VERSION ""

NS_ :

BS_:

BU_:

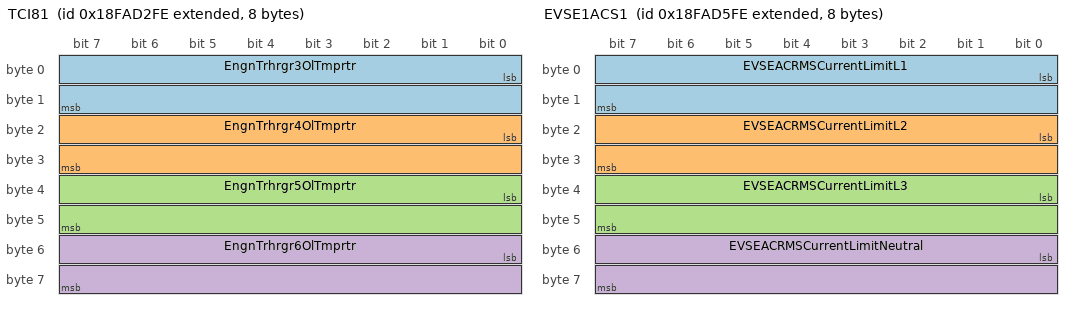
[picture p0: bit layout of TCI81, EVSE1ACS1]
BO_ 2566574846 TCI81: 8 Vector__XXX
 SG_ EngnTrhrgr3OlTmprtr : 0|16@1+ (0.03125,-273) [-273|1734.96875] "degC" Vector__XXX
 SG_ EngnTrhrgr4OlTmprtr : 16|16@1+ (0.03125,-273) [-273|1734.96875] "degC" Vector__XXX
 SG_ EngnTrhrgr5OlTmprtr : 32|16@1+ (0.03125,-273) [-273|1734.96875] "degC" Vector__XXX
 SG_ EngnTrhrgr6OlTmprtr : 48|16@1+ (0.03125,-273) [-273|1734.96875] "degC" Vector__XXX

BO_ 2566575102 ADSC: 8 Vector__XXX
 SG_ TSC1CntrlPrpsP7InhtCmmnd : 0|2@1+ (1,0) [0|3] "" Vector__XXX

BO_ 2566575358 EVSE1ACS2: 8 Vector__XXX
 SG_ EVSE1ACRMSCurrent : 0|16@1+ (0.05,-1600) [-1600|1612.75] "A" Vector__XXX
 SG_ EVSE1ACRMSVoltage : 16|16@1+ (0.05,0) [0|3212.75] "V" Vector__XXX

BO_ 2566575614 EVSE1ACS1: 8 Vector__XXX
 SG_ EVSEACRMSCurrentLimitL1 : 0|16@1+ (0.0625,0) [0|4015.9375] "A" Vector__XXX
 SG_ EVSEACRMSCurrentLimitL2 : 16|16@1+ (0.0625,0) [0|4015.9375] "A" Vector__XXX
 SG_ EVSEACRMSCurrentLimitL3 : 32|16@1+ (0.0625,0) [0|4015.9375] "A" Vector__XXX
 SG_ EVSEACRMSCurrentLimitNeutral : 48|16@1+ (0.0625,0) [0|4015.9375] "A" Vector__XXX

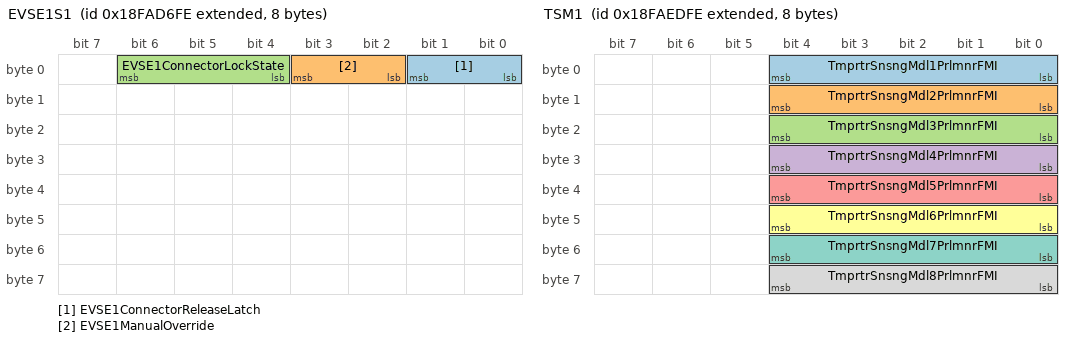
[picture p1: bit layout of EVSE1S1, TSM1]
BO_ 2566575870 EVSE1S1: 8 Vector__XXX
 SG_ EVSE1ConnectorReleaseLatch : 0|2@1+ (1,0) [0|3] "" Vector__XXX
 SG_ EVSE1ManualOverride : 2|2@1+ (1,0) [0|3] "" Vector__XXX
 SG_ EVSE1ConnectorLockState : 4|3@1+ (1,0) [0|7] "" Vector__XXX

BO_ 2566581758 TSM1: 8 Vector__XXX
 SG_ TmprtrSnsngMdl1PrlmnrFMI : 0|5@1+ (1,0) [0|31] "binary" Vector__XXX
 SG_ TmprtrSnsngMdl2PrlmnrFMI : 8|5@1+ (1,0) [0|31] "binary" Vector__XXX
 SG_ TmprtrSnsngMdl3PrlmnrFMI : 16|5@1+ (1,0) [0|31] "binary" Vector__XXX
 SG_ TmprtrSnsngMdl4PrlmnrFMI : 24|5@1+ (1,0) [0|31] "binary" Vector__XXX
 SG_ TmprtrSnsngMdl5PrlmnrFMI : 32|5@1+ (1,0) [0|31] "binary" Vector__XXX
 SG_ TmprtrSnsngMdl6PrlmnrFMI : 40|5@1+ (1,0) [0|31] "binary" Vector__XXX
 SG_ TmprtrSnsngMdl7PrlmnrFMI : 48|5@1+ (1,0) [0|31] "binary" Vector__XXX
 SG_ TmprtrSnsngMdl8PrlmnrFMI : 56|5@1+ (1,0) [0|31] "binary" Vector__XXX

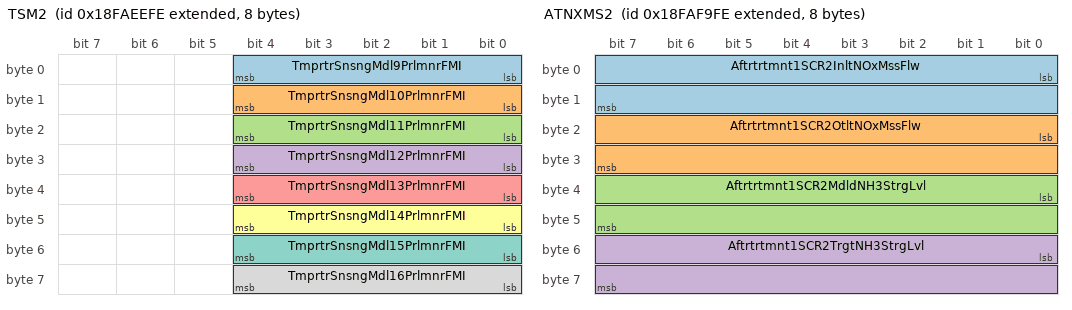
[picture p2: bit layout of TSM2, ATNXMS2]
BO_ 2566582014 TSM2: 8 Vector__XXX
 SG_ TmprtrSnsngMdl9PrlmnrFMI : 0|5@1+ (1,0) [0|31] "binary" Vector__XXX
 SG_ TmprtrSnsngMdl10PrlmnrFMI : 8|5@1+ (1,0) [0|31] "binary" Vector__XXX
 SG_ TmprtrSnsngMdl11PrlmnrFMI : 16|5@1+ (1,0) [0|31] "binary" Vector__XXX
 SG_ TmprtrSnsngMdl12PrlmnrFMI : 24|5@1+ (1,0) [0|31] "binary" Vector__XXX
 SG_ TmprtrSnsngMdl13PrlmnrFMI : 32|5@1+ (1,0) [0|31] "binary" Vector__XXX
 SG_ TmprtrSnsngMdl14PrlmnrFMI : 40|5@1+ (1,0) [0|31] "binary" Vector__XXX
 SG_ TmprtrSnsngMdl15PrlmnrFMI : 48|5@1+ (1,0) [0|31] "binary" Vector__XXX
 SG_ TmprtrSnsngMdl16PrlmnrFMI : 56|5@1+ (1,0) [0|31] "binary" Vector__XXX

BO_ 2566582270 A2SCRSI3: 8 Vector__XXX
 SG_ Aftrtrtmnt2SCRNrmlzdCnvrsnEffn : 0|8@1+ (0.4,0) [0|100] "%" Vector__XXX

BO_ 2566582526 A1SCRSI3: 8 Vector__XXX
 SG_ Aftrtrtmnt1SCRNrmlzdCnvrsnEffn : 0|8@1+ (0.4,0) [0|100] "%" Vector__XXX

BO_ 2566582782 PSATL: 200 Vector__XXX
 SG_ HrdLftmPrplsnSstmAtvTm : 0|32@1+ (1,0) [0|4211081215] "s" Vector__XXX
 SG_ HrdLftmIdlPrplsnSstmAtvTm : 32|32@1+ (1,0) [0|4211081215] "s" Vector__XXX
 SG_ HrdLftmUrnPrplsnSstmAtvTm : 64|32@1+ (1,0) [0|4211081215] "s" Vector__XXX

BO_ 2566583038 PSATS: 200 Vector__XXX
 SG_ HrdStrd100HrRntPrplsnSstmAtvTm : 0|16@1+ (10,0) [0|642550] "s" Vector__XXX
 SG_ HrdStrd100HrIdlPrplsnSstmAtvTm : 16|16@1+ (10,0) [0|642550] "s" Vector__XXX
 SG_ HrdStrd100HrUrnPrplsnSstmAtvTm : 32|16@1+ (10,0) [0|642550] "s" Vector__XXX

BO_ 2566583294 PSATA: 200 Vector__XXX
 SG_ HrdAtv100HrPrplsnSstmAtvTm : 0|16@1+ (10,0) [0|642550] "s" Vector__XXX
 SG_ HrdAtv100HrIdlPrplsnSstmAtvTm : 16|16@1+ (10,0) [0|642550] "s" Vector__XXX
 SG_ HrdAtv100HrUrnPrplsnSstmAtvTm : 32|16@1+ (10,0) [0|642550] "s" Vector__XXX

BO_ 2566583550 HCDIOL: 200 Vector__XXX
 SG_ HdLtDstTvdCDptOptwtE : 0|32@1+ (5,0) [0|21055406075] "m" Vector__XXX
 SG_ HdLtDstTvdCDptOptwtER : 32|32@1+ (5,0) [0|21055406075] "m" Vector__XXX
 SG_ HdLtDstTvdDvStCIsOpt : 64|32@1+ (5,0) [0|21055406075] "m" Vector__XXX
 SG_ HrdLftmFlCnsmdnChrgDpltngOprtn : 96|32@1+ (0.5,0) [0|2105540607.5] "l" Vector__XXX
 SG_ HdLtFCsdDvStCIsOpt : 128|32@1+ (0.5,0) [0|2105540607.5] "l" Vector__XXX
 SG_ HdLtGdECsdCDptOptwtE : 160|32@1+ (1,0) [0|4211081215] "kWh" Vector__XXX
 SG_ HdLtGdECsdCDptOptwtER : 192|32@1+ (1,0) [0|4211081215] "kWh" Vector__XXX
 SG_ HrdLftmGrdEnrgntthBttr : 224|32@1+ (1,0) [0|4211081215] "kWh" Vector__XXX

BO_ 2566583806 HCDIOS: 200 Vector__XXX
 SG_ HdStd100HDstTvdCDptOptwtE : 0|16@1+ (0.25,0) [0|16063.75] "km" Vector__XXX
 SG_ HdStd100HDstTvdCDptOptwtER : 16|16@1+ (0.25,0) [0|16063.75] "km" Vector__XXX
 SG_ HdStd100HDstTvdDvStCIsOpt : 32|16@1+ (0.25,0) [0|16063.75] "km" Vector__XXX
 SG_ HdStd100HFCsdCDptOpt : 48|16@1+ (0.5,0) [0|32127.5] "l" Vector__XXX
 SG_ HdStd100HFCsdDvStCIsOpt : 64|16@1+ (0.5,0) [0|32127.5] "l" Vector__XXX
 SG_ HdStd100HGdECsdCDptOptwtE : 80|16@1+ (1,0) [0|64255] "kWh" Vector__XXX
 SG_ HdStd100HGdECsdCDptOptwtER : 96|16@1+ (1,0) [0|64255] "kWh" Vector__XXX
 SG_ HrdStrd100HrGrdEnrgntthBttr : 112|16@1+ (1,0) [0|64255] "kWh" Vector__XXX

BO_ 2566584062 HCDIOA: 200 Vector__XXX
 SG_ HdAtv100HDstTvdCDptOptwtE : 0|16@1+ (0.25,0) [0|16063.75] "km" Vector__XXX
 SG_ HdAtv100HDstTvdCDptOptwtER : 16|16@1+ (0.25,0) [0|16063.75] "km" Vector__XXX
 SG_ HdAtv100HDstTvdDvStCIsOpt : 32|16@1+ (0.25,0) [0|16063.75] "km" Vector__XXX
 SG_ HdAtv100HFCsdCDptOpt : 48|16@1+ (0.5,0) [0|32127.5] "l" Vector__XXX
 SG_ HdAtv100HFCsdDvStCIsOpt : 64|16@1+ (0.5,0) [0|32127.5] "l" Vector__XXX
 SG_ HdAtv100HGdECsdCDptOptwtE : 80|16@1+ (1,0) [0|64255] "kWh" Vector__XXX
 SG_ HdAtv100HGdECsdCDptOptwtER : 96|16@1+ (1,0) [0|64255] "kWh" Vector__XXX
 SG_ HrdAtv100HrGrdEnrgntthBttr : 112|16@1+ (1,0) [0|64255] "kWh" Vector__XXX

BO_ 2566584318 AT1HI3: 200 Vector__XXX
 SG_ Atttt1DPFRCptSttEVDst1 : 0|32@1+ (5,0) [0|21055406075] "m" Vector__XXX
 SG_ Atttt1DPFRCptEdEVDst1 : 32|32@1+ (5,0) [0|21055406075] "m" Vector__XXX
 SG_ Atttt1DPFRCptSttEVDst2 : 64|32@1+ (5,0) [0|21055406075] "m" Vector__XXX
 SG_ Atttt1DPFRCptEdEVDst2 : 96|32@1+ (0.125,0) [0|526385151.875] "km" Vector__XXX
 SG_ Atttt1DPFRCptSttEVDst3 : 128|32@1+ (5,0) [0|21055406075] "m" Vector__XXX
 SG_ Atttt1DPFRCptEdEVDst3 : 160|32@1+ (5,0) [0|21055406075] "m" Vector__XXX
 SG_ Atttt1TtERtWtNDEFDv : 192|32@1+ (1,0) [0|4211081215] "s" Vector__XXX
 SG_ Atttt1TtTSCRItBw200Css : 224|32@1+ (1,0) [0|4211081215] "s" Vector__XXX

BO_ 2566584830 ATNXMS2: 8 Vector__XXX
 SG_ Aftrtrtmnt1SCR2InltNOxMssFlw : 0|16@1+ (0.0001,0) [0|6.4255] "g/s" Vector__XXX
 SG_ Aftrtrtmnt1SCR2OtltNOxMssFlw : 16|16@1+ (0.0001,0) [0|6.4255] "g/s" Vector__XXX
 SG_ Aftrtrtmnt1SCR2MdldNH3StrgLvl : 32|16@1+ (1,0) [0|64255] "mg/l" Vector__XXX
 SG_ Aftrtrtmnt1SCR2TrgtNH3StrgLvl : 48|16@1+ (1,0) [0|64255] "mg/l" Vector__XXX

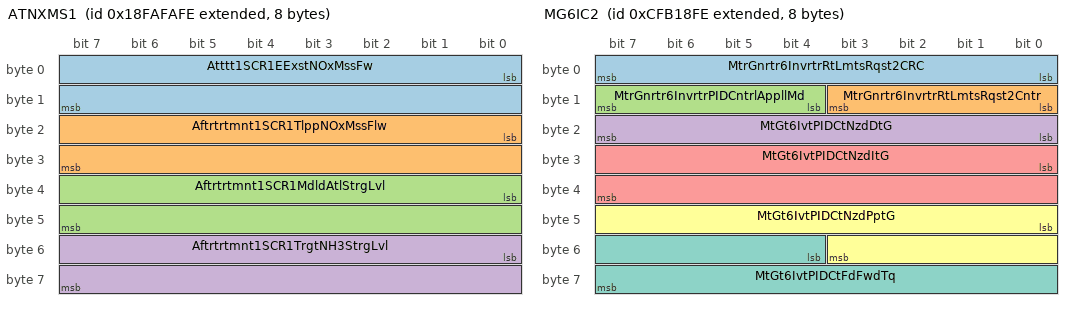
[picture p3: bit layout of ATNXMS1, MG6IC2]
BO_ 2566585086 ATNXMS1: 8 Vector__XXX
 SG_ Atttt1SCR1EExstNOxMssFw : 0|16@1+ (0.0001,0) [0|6.4255] "g/s" Vector__XXX
 SG_ Aftrtrtmnt1SCR1TlppNOxMssFlw : 16|16@1+ (0.0001,0) [0|6.4255] "g/s" Vector__XXX
 SG_ Aftrtrtmnt1SCR1MdldAtlStrgLvl : 32|16@1+ (1,0) [0|64255] "mg/l" Vector__XXX
 SG_ Aftrtrtmnt1SCR1TrgtNH3StrgLvl : 48|16@1+ (1,0) [0|64255] "mg/l" Vector__XXX

BO_ 2566585342 EVAP1: 200 Vector__XXX
 SG_ EVAPSystemPurgePressure : 0|16@1+ (4,0) [0|257] "Pa" Vector__XXX
 SG_ EVAPSystemVaporPressure : 16|16@1+ (4,0) [0|257] "Pa" Vector__XXX
 SG_ EVAPSystemPurgeValveCommand : 32|8@1+ (0.4,0) [0|100] "%" Vector__XXX
 SG_ EVAPSystemPurgeValvePosition : 40|8@1+ (0.4,0) [0|100] "%" Vector__XXX

BO_ 2566585598 GHGTL: 200 Vector__XXX
 SG_ GHGTrkngLftmEngnRnTm : 0|32@1+ (1,0) [0|4211081215] "s" Vector__XXX
 SG_ GHGTrkngLftmVhlDstn : 32|32@1+ (5,0) [0|21055406075] "m" Vector__XXX
 SG_ GHGTrkngLftmVhlFlCnsmptn : 64|32@1+ (0.05,0) [0|210554060.75] "l" Vector__XXX
 SG_ GHGTrkngLftmEngnFlCnsmptn : 96|32@1+ (0.05,0) [0|210554060.75] "l" Vector__XXX
 SG_ GHGTrkngLftmEngnOtptEnrg : 128|32@1+ (1,0) [0|4211081215] "kWh" Vector__XXX
 SG_ GHGTrkngLftmPstvKntEnrgNmrtr : 160|32@1+ (5,0) [0|21055406075] "(km*km)/(h*h)" Vector__XXX
 SG_ GHGTrkngLftmUrnSpdRnTm : 192|32@1+ (1,0) [0|4211081215] "s" Vector__XXX
 SG_ GHGTrackingLifetimeIdleRunTime : 224|32@1+ (1,0) [0|4211081215] "s" Vector__XXX
 SG_ GHGTrkngLftmEngnIdlFlCnsmptn : 256|32@1+ (0.05,0) [0|210554060.75] "l" Vector__XXX
 SG_ GHGTrkngLftmEngnPwrTkOffRnTm : 288|32@1+ (1,0) [0|4211081215] "s" Vector__XXX
 SG_ GHGTLtEPwTOFCspt : 320|32@1+ (0.05,0) [0|210554060.75] "l" Vector__XXX
 SG_ GHGTLtAttEStdwTAtvtCt : 352|16@1+ (1,0) [0|64255] "count" Vector__XXX
 SG_ GHGTrkngLftmStpStrtThnlgRnTm : 384|32@1+ (1,0) [0|4211081215] "s" Vector__XXX

BO_ 2566585854 GHGTS1: 200 Vector__XXX
 SG_ GHGTrkngStrd100HrEngnRnTm : 0|16@1+ (10,0) [0|642550] "s" Vector__XXX
 SG_ GHGTrkngStrd100HrVhlDstn : 16|16@1+ (0.25,0) [0|16063.75] "km" Vector__XXX
 SG_ GHGTrkngStrd100HrVhlFlCnsmptn : 32|16@1+ (0.5,0) [0|32127.5] "l" Vector__XXX
 SG_ GHGTrkngStrd100HrEngnFlCnsmptn : 48|16@1+ (0.5,0) [0|32127.5] "l" Vector__XXX
 SG_ GHGTrkngStrd100HrEngnOtptEnrg : 64|16@1+ (1,0) [0|64255] "kWh" Vector__XXX
 SG_ GHGTStd100HPstvKtENt : 80|32@1+ (1,0) [0|4211081215] "(km*km)/(h*h)" Vector__XXX
 SG_ GHGTrkngStrd100HrUrnSpdRnTm : 112|16@1+ (10,0) [0|642550] "s" Vector__XXX
 SG_ GHGTrkngStrd100HrIdlRnTm : 128|16@1+ (10,0) [0|642550] "s" Vector__XXX
 SG_ GHGTStd100HEIdFCspt : 144|16@1+ (0.5,0) [0|32127.5] "l" Vector__XXX
 SG_ GHGTStd100HEPwTORT : 160|16@1+ (10,0) [0|642550] "s" Vector__XXX
 SG_ GHGTStd100HEPwTOFCspt : 176|16@1+ (0.5,0) [0|32127.5] "l" Vector__XXX
 SG_ GHGTStd100HAttEStdwTAtvtCt : 192|16@1+ (1,0) [0|64255] "count" Vector__XXX
 SG_ GHGTStd100HStpSttTRT : 208|16@1+ (10,0) [0|642550] "s" Vector__XXX

BO_ 2566586110 GHGTA1: 200 Vector__XXX
 SG_ GHGTrkngAtv100HrEngnRnTm : 0|16@1+ (10,0) [0|642550] "s" Vector__XXX
 SG_ GHGTrkngAtv100HrVhlDstn : 16|16@1+ (0.25,0) [0|16063.75] "km" Vector__XXX
 SG_ GHGTrkngAtv100HrVhlFlCnsmptn : 32|16@1+ (0.5,0) [0|32127.5] "l" Vector__XXX
 SG_ GHGTrkngAtv100HrEngnFlCnsmptn : 48|16@1+ (0.5,0) [0|32127.5] "l" Vector__XXX
 SG_ GHGTrkngAtv100HrEngnOtptEnrg : 64|16@1+ (1,0) [0|64255] "kWh" Vector__XXX
 SG_ GHGTAtv100HPstvKtENt : 80|32@1+ (1,0) [0|4211081215] "(km*km)/(h*h)" Vector__XXX
 SG_ GHGTrkngAtv100HrUrnSpdRnTm : 112|16@1+ (10,0) [0|642550] "s" Vector__XXX
 SG_ GHGTrkngAtv100HrIdlRnTm : 128|16@1+ (10,0) [0|642550] "s" Vector__XXX
 SG_ GHGTAtv100HEIdFCspt : 144|16@1+ (0.5,0) [0|32127.5] "l" Vector__XXX
 SG_ GHGTAtv100HEPwTORT : 160|16@1+ (10,0) [0|642550] "s" Vector__XXX
 SG_ GHGTAtv100HEPwTOFCspt : 176|16@1+ (0.5,0) [0|32127.5] "l" Vector__XXX
 SG_ GHGTAtv100HAttEStdwTAtvtCt : 192|16@1+ (1,0) [0|64255] "count" Vector__XXX
 SG_ GHGTAtv100HStpSttTRT : 208|16@1+ (10,0) [0|642550] "s" Vector__XXX

BO_ 2566587134 NTFCEA: 200 Vector__XXX
 SG_ NOxTEAtvtLtFCsptB1Tt : 0|32@1+ (0.05,0) [0|210554060.75] "l" Vector__XXX
 SG_ NOxTEAtvtLtFCsptB2 : 32|32@1+ (0.05,0) [0|210554060.75] "l" Vector__XXX
 SG_ NOxTEAtvtLtFCsptB3 : 64|32@1+ (0.05,0) [0|210554060.75] "l" Vector__XXX
 SG_ NOxTEAtvtLtFCsptB4 : 96|32@1+ (0.05,0) [0|210554060.75] "l" Vector__XXX
 SG_ NOxTEAtvtLtFCsptB5 : 128|32@1+ (0.05,0) [0|210554060.75] "l" Vector__XXX
 SG_ NOxTEAtvtLtFCsptB6 : 160|32@1+ (0.05,0) [0|210554060.75] "l" Vector__XXX
 SG_ NOxTEAtvtLtFCsptB7 : 192|32@1+ (0.05,0) [0|210554060.75] "l" Vector__XXX
 SG_ NOxTEAtvtLtFCsptB8 : 224|32@1+ (0.05,0) [0|210554060.75] "l" Vector__XXX
 SG_ NOxTEAtvtLtFCsptB9 : 256|32@1+ (0.05,0) [0|210554060.75] "l" Vector__XXX
 SG_ NOxTEAtvtLtFCsptB10 : 288|32@1+ (0.05,0) [0|210554060.75] "l" Vector__XXX
 SG_ NOxTEAtvtLtFCsptB11 : 320|32@1+ (0.05,0) [0|210554060.75] "l" Vector__XXX
 SG_ NOxTEAtvtLtFCsptB12 : 352|32@1+ (0.05,0) [0|210554060.75] "l" Vector__XXX
 SG_ NOxTEAtvtLtFCsptB13 : 384|32@1+ (0.05,0) [0|210554060.75] "l" Vector__XXX
 SG_ NOxTEAtvtLtFCsptB14 : 416|32@1+ (0.05,0) [0|210554060.75] "l" Vector__XXX
 SG_ NOxTEAtvtLtFCsptB15NTEBIN : 448|32@1+ (0.05,0) [0|210554060.75] "l" Vector__XXX
 SG_ NOxTEAtvtLtFCsptB16RB : 480|32@1+ (0.05,0) [0|210554060.75] "l" Vector__XXX
 SG_ NOxTEAtvtLtFCsptB17MILOB : 512|32@1+ (0.05,0) [0|210554060.75] "l" Vector__XXX

BO_ 2566587390 NTEHEA: 200 Vector__XXX
 SG_ NOxTEAtvtLtERTB1Tt : 0|32@1+ (1,0) [0|4211081215] "s" Vector__XXX
 SG_ NOxTrkngEngnAtvtLftmEngnRnTmBn2 : 32|32@1+ (1,0) [0|4211081215] "s" Vector__XXX
 SG_ NOxTrkngEngnAtvtLftmEngnRnTmBn3 : 64|32@1+ (1,0) [0|4211081215] "s" Vector__XXX
 SG_ NOxTrkngEngnAtvtLftmEngnRnTmBn4 : 96|32@1+ (1,0) [0|4211081215] "s" Vector__XXX
 SG_ NOxTrkngEngnAtvtLftmEngnRnTmBn5 : 128|32@1+ (1,0) [0|4211081215] "s" Vector__XXX
 SG_ NOxTrkngEngnAtvtLftmEngnRnTmBn6 : 160|32@1+ (1,0) [0|4211081215] "s" Vector__XXX
 SG_ NOxTrkngEngnAtvtLftmEngnRnTmBn7 : 192|32@1+ (1,0) [0|4211081215] "s" Vector__XXX
 SG_ NOxTrkngEngnAtvtLftmEngnRnTmBn8 : 224|32@1+ (1,0) [0|4211081215] "s" Vector__XXX
 SG_ NOxTrkngEngnAtvtLftmEngnRnTmBn9 : 256|32@1+ (1,0) [0|4211081215] "s" Vector__XXX
 SG_ NOxTEAtvtLtERTB10 : 288|32@1+ (1,0) [0|4211081215] "s" Vector__XXX
 SG_ NOxTEAtvtLtERTB11 : 320|32@1+ (1,0) [0|4211081215] "s" Vector__XXX
 SG_ NOxTEAtvtLtERTB12 : 352|32@1+ (1,0) [0|4211081215] "s" Vector__XXX
 SG_ NOxTEAtvtLtERTB13 : 384|32@1+ (1,0) [0|4211081215] "s" Vector__XXX
 SG_ NOxTEAtvtLtERTB14 : 416|32@1+ (1,0) [0|4211081215] "s" Vector__XXX
 SG_ NOxTEAtvtLtERTB15NTEBIN : 448|32@1+ (1,0) [0|4211081215] "s" Vector__XXX
 SG_ NOxTEAtvtLtERTB16RB : 480|32@1+ (1,0) [0|4211081215] "s" Vector__XXX
 SG_ NOxTEAtvtLtERTB17MILOB : 512|32@1+ (1,0) [0|4211081215] "s" Vector__XXX

BO_ 2566587646 NTVMEA: 200 Vector__XXX
 SG_ NOxTEAtvtLtVDstB1Tt : 0|32@1+ (5,0) [0|21055406075] "m" Vector__XXX
 SG_ NOxTrkngEngnAtvtLftmVhlDstnBn2 : 32|32@1+ (5,0) [0|21055406075] "m" Vector__XXX
 SG_ NOxTrkngEngnAtvtLftmVhlDstnBn3 : 64|32@1+ (5,0) [0|21055406075] "m" Vector__XXX
 SG_ NOxTrkngEngnAtvtLftmVhlDstnBn4 : 96|32@1+ (5,0) [0|21055406075] "m" Vector__XXX
 SG_ NOxTrkngEngnAtvtLftmVhlDstnBn5 : 128|32@1+ (5,0) [0|21055406075] "m" Vector__XXX
 SG_ NOxTrkngEngnAtvtLftmVhlDstnBn6 : 160|32@1+ (5,0) [0|21055406075] "m" Vector__XXX
 SG_ NOxTrkngEngnAtvtLftmVhlDstnBn7 : 192|32@1+ (5,0) [0|21055406075] "m" Vector__XXX
 SG_ NOxTrkngEngnAtvtLftmVhlDstnBn8 : 224|32@1+ (5,0) [0|21055406075] "m" Vector__XXX
 SG_ NOxTrkngEngnAtvtLftmVhlDstnBn9 : 256|32@1+ (5,0) [0|21055406075] "m" Vector__XXX
 SG_ NOxTrkngEngnAtvtLftmVhlDstnBn10 : 288|32@1+ (5,0) [0|21055406075] "m" Vector__XXX
 SG_ NOxTrkngEngnAtvtLftmVhlDstnBn11 : 320|32@1+ (5,0) [0|21055406075] "m" Vector__XXX
 SG_ NOxTrkngEngnAtvtLftmVhlDstnBn12 : 352|32@1+ (5,0) [0|21055406075] "m" Vector__XXX
 SG_ NOxTrkngEngnAtvtLftmVhlDstnBn13 : 384|32@1+ (5,0) [0|21055406075] "m" Vector__XXX
 SG_ NOxTrkngEngnAtvtLftmVhlDstnBn14 : 416|32@1+ (5,0) [0|21055406075] "m" Vector__XXX
 SG_ NOxTEAtvtLtVDstB15NTEBIN : 448|32@1+ (5,0) [0|21055406075] "m" Vector__XXX
 SG_ NOxTEAtvtLtVDstB16RB : 480|32@1+ (5,0) [0|21055406075] "m" Vector__XXX
 SG_ NOxTEAtvtLtVDstB17MILOB : 512|32@1+ (5,0) [0|21055406075] "m" Vector__XXX

BO_ 2566587902 NTEEEA: 200 Vector__XXX
 SG_ NOxTEAtvtLtEOtptEB1Tt : 0|32@1+ (1,0) [0|4211081215] "kWh" Vector__XXX
 SG_ NOxTEAtvtLtEOtptEB2 : 32|32@1+ (1,0) [0|4211081215] "kWh" Vector__XXX
 SG_ NOxTEAtvtLtEOtptEB3 : 64|32@1+ (1,0) [0|4211081215] "kWh" Vector__XXX
 SG_ NOxTEAtvtLtEOtptEB4 : 96|32@1+ (1,0) [0|4211081215] "kWh" Vector__XXX
 SG_ NOxTEAtvtLtEOtptEB5 : 128|32@1+ (1,0) [0|4211081215] "kWh" Vector__XXX
 SG_ NOxTEAtvtLtEOtptEB6 : 160|32@1+ (1,0) [0|4211081215] "kWh" Vector__XXX
 SG_ NOxTEAtvtLtEOtptEB7 : 192|32@1+ (1,0) [0|4211081215] "kWh" Vector__XXX
 SG_ NOxTEAtvtLtEOtptEB8 : 224|32@1+ (1,0) [0|4211081215] "kWh" Vector__XXX
 SG_ NOxTEAtvtLtEOtptEB9 : 256|32@1+ (1,0) [0|4211081215] "kWh" Vector__XXX
 SG_ NOxTEAtvtLtEOtptEB10 : 288|32@1+ (1,0) [0|4211081215] "kWh" Vector__XXX
 SG_ NOxTEAtvtLtEOtptEB11 : 320|32@1+ (1,0) [0|4211081215] "kWh" Vector__XXX
 SG_ NOxTEAtvtLtEOtptEB12 : 352|32@1+ (1,0) [0|4211081215] "kWh" Vector__XXX
 SG_ NOxTEAtvtLtEOtptEB13 : 384|32@1+ (1,0) [0|4211081215] "kWh" Vector__XXX
 SG_ NOxTEAtvtLtEOtptEB14 : 416|32@1+ (1,0) [0|4211081215] "kWh" Vector__XXX
 SG_ NOxTEAtvtLtEOtptEB15NTEBIN : 448|32@1+ (1,0) [0|4211081215] "kWh" Vector__XXX
 SG_ NOxTEAtvtLtEOtptEB16RB : 480|32@1+ (1,0) [0|4211081215] "kWh" Vector__XXX
 SG_ NOxTEAtvtLtEOtptEB17MILOB : 512|32@1+ (1,0) [0|4211081215] "kWh" Vector__XXX

BO_ 2566588158 NTFCV: 200 Vector__XXX
 SG_ NOxTVdNOxLtFCsptB1Tt : 0|32@1+ (0.05,0) [0|210554060.75] "l" Vector__XXX
 SG_ NOxTrkngVldNOxLftmFlCnsmptnBn2 : 32|32@1+ (0.05,0) [0|210554060.75] "l" Vector__XXX
 SG_ NOxTrkngVldNOxLftmFlCnsmptnBn3 : 64|32@1+ (0.05,0) [0|210554060.75] "l" Vector__XXX
 SG_ NOxTrkngVldNOxLftmFlCnsmptnBn4 : 96|32@1+ (0.05,0) [0|210554060.75] "l" Vector__XXX
 SG_ NOxTrkngVldNOxLftmFlCnsmptnBn5 : 128|32@1+ (0.05,0) [0|210554060.75] "l" Vector__XXX
 SG_ NOxTrkngVldNOxLftmFlCnsmptnBn6 : 160|32@1+ (0.05,0) [0|210554060.75] "l" Vector__XXX
 SG_ NOxTrkngVldNOxLftmFlCnsmptnBn7 : 192|32@1+ (0.05,0) [0|210554060.75] "l" Vector__XXX
 SG_ NOxTrkngVldNOxLftmFlCnsmptnBn8 : 224|32@1+ (0.05,0) [0|210554060.75] "l" Vector__XXX
 SG_ NOxTrkngVldNOxLftmFlCnsmptnBn9 : 256|32@1+ (0.05,0) [0|210554060.75] "l" Vector__XXX
 SG_ NOxTrkngVldNOxLftmFlCnsmptnBn10 : 288|32@1+ (0.05,0) [0|210554060.75] "l" Vector__XXX
 SG_ NOxTrkngVldNOxLftmFlCnsmptnBn11 : 320|32@1+ (0.05,0) [0|210554060.75] "l" Vector__XXX
 SG_ NOxTrkngVldNOxLftmFlCnsmptnBn12 : 352|32@1+ (0.05,0) [0|210554060.75] "l" Vector__XXX
 SG_ NOxTrkngVldNOxLftmFlCnsmptnBn13 : 384|32@1+ (0.05,0) [0|210554060.75] "l" Vector__XXX
 SG_ NOxTrkngVldNOxLftmFlCnsmptnBn14 : 416|32@1+ (0.05,0) [0|210554060.75] "l" Vector__XXX
 SG_ NOxTVdNOxLtFCsptB15NTEBIN : 448|32@1+ (0.05,0) [0|210554060.75] "l" Vector__XXX
 SG_ NOxTVdNOxLtFCsptB16RB : 480|32@1+ (0.05,0) [0|210554060.75] "l" Vector__XXX
 SG_ NOxTVdNOxLtFCsptB17MILOB : 512|32@1+ (0.05,0) [0|210554060.75] "l" Vector__XXX

BO_ 2566588414 NTEHV: 200 Vector__XXX
 SG_ NOxTVdNOxLtERTB1Tt : 0|32@1+ (1,0) [0|4211081215] "s" Vector__XXX
 SG_ NOxTrkngVldNOxLftmEngnRnTmBn2 : 32|32@1+ (1,0) [0|4211081215] "s" Vector__XXX
 SG_ NOxTrkngVldNOxLftmEngnRnTmBn3 : 64|32@1+ (1,0) [0|4211081215] "s" Vector__XXX
 SG_ NOxTrkngVldNOxLftmEngnRnTmBn4 : 96|32@1+ (1,0) [0|4211081215] "s" Vector__XXX
 SG_ NOxTrkngVldNOxLftmEngnRnTmBn5 : 128|32@1+ (1,0) [0|4211081215] "s" Vector__XXX
 SG_ NOxTrkngVldNOxLftmEngnRnTmBn6 : 160|32@1+ (1,0) [0|4211081215] "s" Vector__XXX
 SG_ NOxTrkngVldNOxLftmEngnRnTmBn7 : 192|32@1+ (1,0) [0|4211081215] "s" Vector__XXX
 SG_ NOxTrkngVldNOxLftmEngnRnTmBn8 : 224|32@1+ (1,0) [0|4211081215] "s" Vector__XXX
 SG_ NOxTrkngVldNOxLftmEngnRnTmBn9 : 256|32@1+ (1,0) [0|4211081215] "s" Vector__XXX
 SG_ NOxTrkngVldNOxLftmEngnRnTmBn10 : 288|32@1+ (1,0) [0|4211081215] "s" Vector__XXX
 SG_ NOxTrkngVldNOxLftmEngnRnTmBn11 : 320|32@1+ (1,0) [0|4211081215] "s" Vector__XXX
 SG_ NOxTrkngVldNOxLftmEngnRnTmBn12 : 352|32@1+ (1,0) [0|4211081215] "s" Vector__XXX
 SG_ NOxTrkngVldNOxLftmEngnRnTmBn13 : 384|32@1+ (1,0) [0|4211081215] "s" Vector__XXX
 SG_ NOxTrkngVldNOxLftmEngnRnTmBn14 : 416|32@1+ (1,0) [0|4211081215] "s" Vector__XXX
 SG_ NOxTVdNOxLtERTB15NTEBIN : 448|32@1+ (1,0) [0|4211081215] "s" Vector__XXX
 SG_ NOxTVdNOxLtERTB16RB : 480|32@1+ (1,0) [0|4211081215] "s" Vector__XXX
 SG_ NOxTVdNOxLtERTB17MILOB : 512|32@1+ (1,0) [0|4211081215] "s" Vector__XXX

BO_ 2566588670 NTVMV: 200 Vector__XXX
 SG_ NOxTrkngVldNOxLftmVhlDstnBn1Ttl : 0|32@1+ (5,0) [0|21055406075] "m" Vector__XXX
 SG_ NOxTrkngVldNOxLftmVhlDstnBn2 : 32|32@1+ (5,0) [0|21055406075] "m" Vector__XXX
 SG_ NOxTrkngVldNOxLftmVhlDstnBn3 : 64|32@1+ (5,0) [0|21055406075] "m" Vector__XXX
 SG_ NOxTrkngVldNOxLftmVhlDstnBn4 : 96|32@1+ (5,0) [0|21055406075] "m" Vector__XXX
 SG_ NOxTrkngVldNOxLftmVhlDstnBn5 : 128|32@1+ (5,0) [0|21055406075] "m" Vector__XXX
 SG_ NOxTrkngVldNOxLftmVhlDstnBn6 : 160|32@1+ (5,0) [0|21055406075] "m" Vector__XXX
 SG_ NOxTrkngVldNOxLftmVhlDstnBn7 : 192|32@1+ (5,0) [0|21055406075] "m" Vector__XXX
 SG_ NOxTrkngVldNOxLftmVhlDstnBn8 : 224|32@1+ (5,0) [0|21055406075] "m" Vector__XXX
 SG_ NOxTrkngVldNOxLftmVhlDstnBn9 : 256|32@1+ (5,0) [0|21055406075] "m" Vector__XXX
 SG_ NOxTrkngVldNOxLftmVhlDstnBn10 : 288|32@1+ (5,0) [0|21055406075] "m" Vector__XXX
 SG_ NOxTrkngVldNOxLftmVhlDstnBn11 : 320|32@1+ (5,0) [0|21055406075] "m" Vector__XXX
 SG_ NOxTrkngVldNOxLftmVhlDstnBn12 : 352|32@1+ (5,0) [0|21055406075] "m" Vector__XXX
 SG_ NOxTrkngVldNOxLftmVhlDstnBn13 : 384|32@1+ (5,0) [0|21055406075] "m" Vector__XXX
 SG_ NOxTrkngVldNOxLftmVhlDstnBn14 : 416|32@1+ (5,0) [0|21055406075] "m" Vector__XXX
 SG_ NOxTVdNOxLtVDstB15NTEBIN : 448|32@1+ (5,0) [0|21055406075] "m" Vector__XXX
 SG_ NOxTVdNOxLtVDstB16RB : 480|32@1+ (5,0) [0|21055406075] "m" Vector__XXX
 SG_ NOxTVdNOxLtVDstB17MILOB : 512|32@1+ (5,0) [0|21055406075] "m" Vector__XXX

BO_ 2566588926 NTEEV: 200 Vector__XXX
 SG_ NOxTVdNOxLtEOtptEB1Tt : 0|32@1+ (1,0) [0|4211081215] "kWh" Vector__XXX
 SG_ NOxTVdNOxLtEOtptEB2 : 32|32@1+ (1,0) [0|4211081215] "kWh" Vector__XXX
 SG_ NOxTVdNOxLtEOtptEB3 : 64|32@1+ (1,0) [0|4211081215] "kWh" Vector__XXX
 SG_ NOxTVdNOxLtEOtptEB4 : 96|32@1+ (1,0) [0|4211081215] "kWh" Vector__XXX
 SG_ NOxTVdNOxLtEOtptEB5 : 128|32@1+ (1,0) [0|4211081215] "kWh" Vector__XXX
 SG_ NOxTVdNOxLtEOtptEB6 : 160|32@1+ (1,0) [0|4211081215] "kWh" Vector__XXX
 SG_ NOxTVdNOxLtEOtptEB7 : 192|32@1+ (1,0) [0|4211081215] "kWh" Vector__XXX
 SG_ NOxTVdNOxLtEOtptEB8 : 224|32@1+ (1,0) [0|4211081215] "kWh" Vector__XXX
 SG_ NOxTVdNOxLtEOtptEB9 : 256|32@1+ (1,0) [0|4211081215] "kWh" Vector__XXX
 SG_ NOxTVdNOxLtEOtptEB10 : 288|32@1+ (1,0) [0|4211081215] "kWh" Vector__XXX
 SG_ NOxTVdNOxLtEOtptEB11 : 320|32@1+ (1,0) [0|4211081215] "kWh" Vector__XXX
 SG_ NOxTVdNOxLtEOtptEB12 : 352|32@1+ (1,0) [0|4211081215] "kWh" Vector__XXX
 SG_ NOxTVdNOxLtEOtptEB13 : 384|32@1+ (1,0) [0|4211081215] "kWh" Vector__XXX
 SG_ NOxTVdNOxLtEOtptEB14 : 416|32@1+ (1,0) [0|4211081215] "kWh" Vector__XXX
 SG_ NOxTVdNOxLtEOtptEB15NTEBIN : 448|32@1+ (1,0) [0|4211081215] "kWh" Vector__XXX
 SG_ NOxTVdNOxLtEOtptEB16RB : 480|32@1+ (1,0) [0|4211081215] "kWh" Vector__XXX
 SG_ NOxTVdNOxLtEOtptEB17MILOB : 512|32@1+ (1,0) [0|4211081215] "kWh" Vector__XXX

BO_ 2566589182 NTENV: 200 Vector__XXX
 SG_ NOxTVdNOxLtEOtNOxMssB1Tt : 0|32@1+ (1,0) [0|4211081215] "g" Vector__XXX
 SG_ NOxTVdNOxLtEOtNOxMssB2 : 32|32@1+ (1,0) [0|4211081215] "g" Vector__XXX
 SG_ NOxTVdNOxLtEOtNOxMssB3 : 64|32@1+ (1,0) [0|4211081215] "g" Vector__XXX
 SG_ NOxTVdNOxLtEOtNOxMssB4 : 96|32@1+ (1,0) [0|4211081215] "g" Vector__XXX
 SG_ NOxTVdNOxLtEOtNOxMssB5 : 128|32@1+ (1,0) [0|4211081215] "g" Vector__XXX
 SG_ NOxTVdNOxLtEOtNOxMssB6 : 160|32@1+ (1,0) [0|4211081215] "g" Vector__XXX
 SG_ NOxTVdNOxLtEOtNOxMssB7 : 192|32@1+ (1,0) [0|4211081215] "g" Vector__XXX
 SG_ NOxTVdNOxLtEOtNOxMssB8 : 224|32@1+ (1,0) [0|4211081215] "g" Vector__XXX
 SG_ NOxTVdNOxLtEOtNOxMssB9 : 256|32@1+ (1,0) [0|4211081215] "g" Vector__XXX
 SG_ NOxTVdNOxLtEOtNOxMssB10 : 288|32@1+ (1,0) [0|4211081215] "g" Vector__XXX
 SG_ NOxTVdNOxLtEOtNOxMssB11 : 320|32@1+ (1,0) [0|4211081215] "g" Vector__XXX
 SG_ NOxTVdNOxLtEOtNOxMssB12 : 352|32@1+ (1,0) [0|4211081215] "g" Vector__XXX
 SG_ NOxTVdNOxLtEOtNOxMssB13 : 384|32@1+ (1,0) [0|4211081215] "g" Vector__XXX
 SG_ NOxTVdNOxLtEOtNOxMssB14 : 416|32@1+ (1,0) [0|4211081215] "g" Vector__XXX
 SG_ NOxTVdNOxLtEOtNOxMssB15NTEBIN : 448|32@1+ (1,0) [0|4211081215] "g" Vector__XXX
 SG_ NOxTVdNOxLtEOtNOxMssB16RB : 480|32@1+ (1,0) [0|4211081215] "g" Vector__XXX
 SG_ NOxTVdNOxLtEOtNOxMssB17MILOB : 512|32@1+ (1,0) [0|4211081215] "g" Vector__XXX

BO_ 2566589438 NTSNV: 200 Vector__XXX
 SG_ NOxTVdNOxLtSstOtNOxMssB1Tt : 0|32@1+ (1,0) [0|4211081215] "g" Vector__XXX
 SG_ NOxTVdNOxLtSstOtNOxMssB2 : 32|32@1+ (1,0) [0|4211081215] "g" Vector__XXX
 SG_ NOxTVdNOxLtSstOtNOxMssB3 : 64|32@1+ (1,0) [0|4211081215] "g" Vector__XXX
 SG_ NOxTVdNOxLtSstOtNOxMssB4 : 96|32@1+ (1,0) [0|4211081215] "g" Vector__XXX
 SG_ NOxTVdNOxLtSstOtNOxMssB5 : 128|32@1+ (1,0) [0|4211081215] "g" Vector__XXX
 SG_ NOxTVdNOxLtSstOtNOxMssB6 : 160|32@1+ (1,0) [0|4211081215] "g" Vector__XXX
 SG_ NOxTVdNOxLtSstOtNOxMssB7 : 192|32@1+ (1,0) [0|4211081215] "g" Vector__XXX
 SG_ NOxTVdNOxLtSstOtNOxMssB8 : 224|32@1+ (1,0) [0|4211081215] "g" Vector__XXX
 SG_ NOxTVdNOxLtSstOtNOxMssB9 : 256|32@1+ (1,0) [0|4211081215] "g" Vector__XXX
 SG_ NOxTVdNOxLtSstOtNOxMssB10 : 288|32@1+ (1,0) [0|4211081215] "g" Vector__XXX
 SG_ NOxTVdNOxLtSstOtNOxMssB11 : 320|32@1+ (1,0) [0|4211081215] "g" Vector__XXX
 SG_ NOxTVdNOxLtSstOtNOxMssB12 : 352|32@1+ (1,0) [0|4211081215] "g" Vector__XXX
 SG_ NOxTVdNOxLtSstOtNOxMssB13 : 384|32@1+ (1,0) [0|4211081215] "g" Vector__XXX
 SG_ NOxTVdNOxLtSstOtNOxMssB14 : 416|32@1+ (1,0) [0|4211081215] "g" Vector__XXX
 SG_ NOxTVdNOxLtSstOtNOxMssB15NTEBIN : 448|32@1+ (1,0) [0|4211081215] "g" Vector__XXX
 SG_ NOxTVdNOxLtSstOtNOxMssB16RB : 480|32@1+ (1,0) [0|4211081215] "g" Vector__XXX
 SG_ NOxTVdNOxLtSstOtNOxMssB17MILOB : 512|32@1+ (1,0) [0|4211081215] "g" Vector__XXX

BO_ 2566589694 NTFCS: 200 Vector__XXX
 SG_ NOxTStd100HFCsptB1Tt : 0|16@1+ (0.5,0) [0|32127.5] "l" Vector__XXX
 SG_ NOxTrkngStrd100HrFlCnsmptnBn2 : 16|16@1+ (0.5,0) [0|32127.5] "l" Vector__XXX
 SG_ NOxTrkngStrd100HrFlCnsmptnBn3 : 32|16@1+ (0.5,0) [0|32127.5] "l" Vector__XXX
 SG_ NOxTrkngStrd100HrFlCnsmptnBn4 : 48|16@1+ (0.5,0) [0|32127.5] "l" Vector__XXX
 SG_ NOxTrkngStrd100HrFlCnsmptnBn5 : 64|16@1+ (0.5,0) [0|32127.5] "l" Vector__XXX
 SG_ NOxTrkngStrd100HrFlCnsmptnBn6 : 80|16@1+ (0.5,0) [0|32127.5] "l" Vector__XXX
 SG_ NOxTrkngStrd100HrFlCnsmptnBn7 : 96|16@1+ (0.5,0) [0|32127.5] "l" Vector__XXX
 SG_ NOxTrkngStrd100HrFlCnsmptnBn8 : 112|16@1+ (0.5,0) [0|32127.5] "l" Vector__XXX
 SG_ NOxTrkngStrd100HrFlCnsmptnBn9 : 128|16@1+ (0.5,0) [0|32127.5] "l" Vector__XXX
 SG_ NOxTrkngStrd100HrFlCnsmptnBn10 : 144|16@1+ (0.5,0) [0|32127.5] "l" Vector__XXX
 SG_ NOxTrkngStrd100HrFlCnsmptnBn11 : 160|16@1+ (0.5,0) [0|32127.5] "l" Vector__XXX
 SG_ NOxTrkngStrd100HrFlCnsmptnBn12 : 176|16@1+ (0.5,0) [0|32127.5] "l" Vector__XXX
 SG_ NOxTrkngStrd100HrFlCnsmptnBn13 : 192|16@1+ (0.5,0) [0|32127.5] "l" Vector__XXX
 SG_ NOxTrkngStrd100HrFlCnsmptnBn14 : 208|16@1+ (0.5,0) [0|32127.5] "l" Vector__XXX
 SG_ NOxTStd100HFCsptB15NTEBIN : 224|16@1+ (0.5,0) [0|32127.5] "l" Vector__XXX
 SG_ NOxTStd100HFCsptB16RB : 240|16@1+ (0.5,0) [0|32127.5] "l" Vector__XXX
 SG_ NOxTStd100HFCsptB17MILOB : 256|16@1+ (0.5,0) [0|32127.5] "l" Vector__XXX

BO_ 2566589950 NTEHS: 200 Vector__XXX
 SG_ NOxTrkngStrd100HrEngnRnTmBn1Ttl : 0|16@1+ (10,0) [0|642550] "s" Vector__XXX
 SG_ NOxTrkngStrd100HrEngnRnTmBn2 : 16|16@1+ (10,0) [0|642550] "s" Vector__XXX
 SG_ NOxTrkngStrd100HrEngnRnTmBn3 : 32|16@1+ (10,0) [0|642550] "s" Vector__XXX
 SG_ NOxTrkngStrd100HrEngnRnTmBn4 : 48|16@1+ (10,0) [0|642550] "s" Vector__XXX
 SG_ NOxTrkngStrd100HrEngnRnTmBn5 : 64|16@1+ (10,0) [0|642550] "s" Vector__XXX
 SG_ NOxTrkngStrd100HrEngnRnTmBn6 : 80|16@1+ (10,0) [0|642550] "s" Vector__XXX
 SG_ NOxTrkngStrd100HrEngnRnTmBn7 : 96|16@1+ (10,0) [0|642550] "s" Vector__XXX
 SG_ NOxTrkngStrd100HrEngnRnTmBn8 : 112|16@1+ (10,0) [0|642550] "s" Vector__XXX
 SG_ NOxTrkngStrd100HrEngnRnTmBn9 : 128|16@1+ (10,0) [0|642550] "s" Vector__XXX
 SG_ NOxTrkngStrd100HrEngnRnTmBn10 : 144|16@1+ (10,0) [0|642550] "s" Vector__XXX
 SG_ NOxTrkngStrd100HrEngnRnTmBn11 : 160|16@1+ (10,0) [0|642550] "s" Vector__XXX
 SG_ NOxTrkngStrd100HrEngnRnTmBn12 : 176|16@1+ (10,0) [0|642550] "s" Vector__XXX
 SG_ NOxTrkngStrd100HrEngnRnTmBn13 : 192|16@1+ (10,0) [0|642550] "s" Vector__XXX
 SG_ NOxTrkngStrd100HrEngnRnTmBn14 : 208|16@1+ (10,0) [0|642550] "s" Vector__XXX
 SG_ NOxTStd100HERTB15NTEBIN : 224|16@1+ (10,0) [0|642550] "s" Vector__XXX
 SG_ NOxTStd100HERTB16RB : 240|16@1+ (10,0) [0|642550] "s" Vector__XXX
 SG_ NOxTStd100HERTB17MILOB : 256|16@1+ (10,0) [0|642550] "s" Vector__XXX

BO_ 2566590206 NTVMS: 200 Vector__XXX
 SG_ NOxTrkngStrd100HrVhlDstnBn1Ttl : 0|16@1+ (0.25,0) [0|16063.75] "km" Vector__XXX
 SG_ NOxTrkngStrd100HrVhlDstnBn2 : 16|16@1+ (0.25,0) [0|16063.75] "km" Vector__XXX
 SG_ NOxTrkngStrd100HrVhlDstnBn3 : 32|16@1+ (0.25,0) [0|16063.75] "km" Vector__XXX
 SG_ NOxTrkngStrd100HrVhlDstnBn4 : 48|16@1+ (0.25,0) [0|16063.75] "km" Vector__XXX
 SG_ NOxTrkngStrd100HrVhlDstnBn5 : 64|16@1+ (0.25,0) [0|16063.75] "km" Vector__XXX
 SG_ NOxTrkngStrd100HrVhlDstnBn6 : 80|16@1+ (0.25,0) [0|16063.75] "km" Vector__XXX
 SG_ NOxTrkngStrd100HrVhlDstnBn7 : 96|16@1+ (0.25,0) [0|16063.75] "km" Vector__XXX
 SG_ NOxTrkngStrd100HrVhlDstnBn8 : 112|16@1+ (0.25,0) [0|16063.75] "km" Vector__XXX
 SG_ NOxTrkngStrd100HrVhlDstnBn9 : 128|16@1+ (0.25,0) [0|16063.75] "km" Vector__XXX
 SG_ NOxTrkngStrd100HrVhlDstnBn10 : 144|16@1+ (0.25,0) [0|16063.75] "km" Vector__XXX
 SG_ NOxTrkngStrd100HrVhlDstnBn11 : 160|16@1+ (0.25,0) [0|16063.75] "km" Vector__XXX
 SG_ NOxTrkngStrd100HrVhlDstnBn12 : 176|16@1+ (0.25,0) [0|16063.75] "km" Vector__XXX
 SG_ NOxTrkngStrd100HrVhlDstnBn13 : 192|16@1+ (0.25,0) [0|16063.75] "km" Vector__XXX
 SG_ NOxTrkngStrd100HrVhlDstnBn14 : 208|16@1+ (0.25,0) [0|16063.75] "km" Vector__XXX
 SG_ NOxTStd100HVDstB15NTEBIN : 224|16@1+ (0.25,0) [0|16063.75] "km" Vector__XXX
 SG_ NOxTStd100HVDstB16RB : 240|16@1+ (0.25,0) [0|16063.75] "km" Vector__XXX
 SG_ NOxTStd100HVDstB17MILOB : 256|16@1+ (0.25,0) [0|16063.75] "km" Vector__XXX

BO_ 2566590462 NTEES: 200 Vector__XXX
 SG_ NOxTStd100HEOtptEB1Tt : 0|16@1+ (1,0) [0|64255] "kWh" Vector__XXX
 SG_ NOxTStd100HEOtptEB2 : 16|16@1+ (1,0) [0|64255] "kWh" Vector__XXX
 SG_ NOxTStd100HEOtptEB3 : 32|16@1+ (1,0) [0|64255] "kWh" Vector__XXX
 SG_ NOxTStd100HEOtptEB4 : 48|16@1+ (1,0) [0|64255] "kWh" Vector__XXX
 SG_ NOxTStd100HEOtptEB5 : 64|16@1+ (1,0) [0|64255] "kWh" Vector__XXX
 SG_ NOxTStd100HEOtptEB6 : 80|16@1+ (1,0) [0|64255] "kWh" Vector__XXX
 SG_ NOxTStd100HEOtptEB7 : 96|16@1+ (1,0) [0|64255] "kWh" Vector__XXX
 SG_ NOxTStd100HEOtptEB8 : 112|16@1+ (1,0) [0|64255] "kWh" Vector__XXX
 SG_ NOxTStd100HEOtptEB9 : 128|16@1+ (1,0) [0|64255] "kWh" Vector__XXX
 SG_ NOxTStd100HEOtptEB10 : 144|16@1+ (1,0) [0|64255] "kWh" Vector__XXX
 SG_ NOxTStd100HEOtptEB11 : 160|16@1+ (1,0) [0|64255] "kWh" Vector__XXX
 SG_ NOxTStd100HEOtptEB12 : 176|16@1+ (1,0) [0|64255] "kWh" Vector__XXX
 SG_ NOxTStd100HEOtptEB13 : 192|16@1+ (1,0) [0|64255] "kWh" Vector__XXX
 SG_ NOxTStd100HEOtptEB14 : 208|16@1+ (1,0) [0|64255] "kWh" Vector__XXX
 SG_ NOxTStd100HEOtptEB15NTEBIN : 224|16@1+ (1,0) [0|64255] "kWh" Vector__XXX
 SG_ NOxTStd100HEOtptEB16RB : 240|16@1+ (1,0) [0|64255] "kWh" Vector__XXX
 SG_ NOxTStd100HEOtptEB17MILOB : 256|16@1+ (1,0) [0|64255] "kWh" Vector__XXX

BO_ 2566590718 NTENS: 200 Vector__XXX
 SG_ NOxTStd100HEOtNOxMssB1Tt : 0|32@1+ (0.0005,0) [0|2105540.6075] "g" Vector__XXX
 SG_ NOxTStd100HEOtNOxMssB2 : 32|32@1+ (0.0005,0) [0|2105540.6075] "g" Vector__XXX
 SG_ NOxTStd100HEOtNOxMssB3 : 64|32@1+ (0.0005,0) [0|2105540.6075] "g" Vector__XXX
 SG_ NOxTStd100HEOtNOxMssB4 : 96|32@1+ (0.0005,0) [0|2105540.6075] "g" Vector__XXX
 SG_ NOxTStd100HEOtNOxMssB5 : 128|32@1+ (0.0005,0) [0|2105540.6075] "g" Vector__XXX
 SG_ NOxTStd100HEOtNOxMssB6 : 160|32@1+ (0.0005,0) [0|2105540.6075] "g" Vector__XXX
 SG_ NOxTStd100HEOtNOxMssB7 : 192|32@1+ (0.0005,0) [0|2105540.6075] "g" Vector__XXX
 SG_ NOxTStd100HEOtNOxMssB8 : 224|32@1+ (0.0005,0) [0|2105540.6075] "g" Vector__XXX
 SG_ NOxTStd100HEOtNOxMssB9 : 256|32@1+ (0.0005,0) [0|2105540.6075] "g" Vector__XXX
 SG_ NOxTStd100HEOtNOxMssB10 : 288|32@1+ (0.0005,0) [0|2105540.6075] "g" Vector__XXX
 SG_ NOxTStd100HEOtNOxMssB11 : 320|32@1+ (0.0005,0) [0|2105540.6075] "g" Vector__XXX
 SG_ NOxTStd100HEOtNOxMssB12 : 352|32@1+ (0.0005,0) [0|2105540.6075] "g" Vector__XXX
 SG_ NOxTStd100HEOtNOxMssB13 : 384|32@1+ (0.0005,0) [0|2105540.6075] "g" Vector__XXX
 SG_ NOxTStd100HEOtNOxMssB14 : 416|32@1+ (0.0005,0) [0|2105540.6075] "g" Vector__XXX
 SG_ NOxTStd100HEOtNOxMssB15NTEBIN : 448|32@1+ (0.0005,0) [0|2105540.6075] "g" Vector__XXX
 SG_ NOxTStd100HEOtNOxMssB16RB : 480|32@1+ (0.0005,0) [0|2105540.6075] "g" Vector__XXX
 SG_ NOxTStd100HEOtNOxMssB17MILOB : 512|32@1+ (0.0005,0) [0|2105540.6075] "g" Vector__XXX

BO_ 2566590974 NTSNS: 200 Vector__XXX
 SG_ NOxTStd100HSstOtNOxMssB1Tt : 0|32@1+ (0.0002,0) [0|842216.243] "g" Vector__XXX
 SG_ NOxTStd100HSstOtNOxMssB2 : 32|32@1+ (0.0002,0) [0|842216.243] "g" Vector__XXX
 SG_ NOxTStd100HSstOtNOxMssB3 : 64|32@1+ (0.0002,0) [0|842216.243] "g" Vector__XXX
 SG_ NOxTStd100HSstOtNOxMssB4 : 96|32@1+ (0.0002,0) [0|842216.243] "g" Vector__XXX
 SG_ NOxTStd100HSstOtNOxMssB5 : 128|32@1+ (0.0002,0) [0|842216.243] "g" Vector__XXX
 SG_ NOxTStd100HSstOtNOxMssB6 : 160|32@1+ (0.0002,0) [0|842216.243] "g" Vector__XXX
 SG_ NOxTStd100HSstOtNOxMssB7 : 192|32@1+ (0.0002,0) [0|842216.243] "g" Vector__XXX
 SG_ NOxTStd100HSstOtNOxMssB8 : 224|32@1+ (0.0002,0) [0|842216.243] "g" Vector__XXX
 SG_ NOxTStd100HSstOtNOxMssB9 : 256|32@1+ (0.0002,0) [0|842216.243] "g" Vector__XXX
 SG_ NOxTStd100HSstOtNOxMssB10 : 288|32@1+ (0.0002,0) [0|842216.243] "g" Vector__XXX
 SG_ NOxTStd100HSstOtNOxMssB11 : 320|32@1+ (0.0002,0) [0|842216.243] "g" Vector__XXX
 SG_ NOxTStd100HSstOtNOxMssB12 : 352|32@1+ (0.0002,0) [0|842216.243] "g" Vector__XXX
 SG_ NOxTStd100HSstOtNOxMssB13 : 384|32@1+ (0.0002,0) [0|842216.243] "g" Vector__XXX
 SG_ NOxTStd100HSstOtNOxMssB14 : 416|32@1+ (0.0002,0) [0|842216.243] "g" Vector__XXX
 SG_ NOxTStd100HSstOtNOxMssB15NTEBIN : 448|32@1+ (0.0002,0) [0|842216.243] "g" Vector__XXX
 SG_ NOxTStd100HSstOtNOxMssB16RB : 480|32@1+ (0.0002,0) [0|842216.243] "g" Vector__XXX
 SG_ NOxTStd100HSstOtNOxMssB17MILOB : 512|32@1+ (0.0002,0) [0|842216.243] "g" Vector__XXX

BO_ 2566591230 NTFCA: 200 Vector__XXX
 SG_ NOxTrkngAtv100HrFlCnsmptnBn1Ttl : 0|16@1+ (0.5,0) [0|32127.5] "l" Vector__XXX
 SG_ NOxTrkngAtv100HrFlCnsmptnBn2 : 16|16@1+ (0.5,0) [0|32127.5] "l" Vector__XXX
 SG_ NOxTrkngAtv100HrFlCnsmptnBn3 : 32|16@1+ (0.5,0) [0|32127.5] "l" Vector__XXX
 SG_ NOxTrkngAtv100HrFlCnsmptnBn4 : 48|16@1+ (0.5,0) [0|32127.5] "l" Vector__XXX
 SG_ NOxTrkngAtv100HrFlCnsmptnBn5 : 64|16@1+ (0.5,0) [0|32127.5] "l" Vector__XXX
 SG_ NOxTrkngAtv100HrFlCnsmptnBn6 : 80|16@1+ (0.5,0) [0|32127.5] "l" Vector__XXX
 SG_ NOxTrkngAtv100HrFlCnsmptnBn7 : 96|16@1+ (0.5,0) [0|32127.5] "l" Vector__XXX
 SG_ NOxTrkngAtv100HrFlCnsmptnBn8 : 112|16@1+ (0.5,0) [0|32127.5] "l" Vector__XXX
 SG_ NOxTrkngAtv100HrFlCnsmptnBn9 : 128|16@1+ (0.5,0) [0|32127.5] "l" Vector__XXX
 SG_ NOxTrkngAtv100HrFlCnsmptnBn10 : 144|16@1+ (0.5,0) [0|32127.5] "l" Vector__XXX
 SG_ NOxTrkngAtv100HrFlCnsmptnBn11 : 160|16@1+ (0.5,0) [0|32127.5] "l" Vector__XXX
 SG_ NOxTrkngAtv100HrFlCnsmptnBn12 : 176|16@1+ (0.5,0) [0|32127.5] "l" Vector__XXX
 SG_ NOxTrkngAtv100HrFlCnsmptnBn13 : 192|16@1+ (0.5,0) [0|32127.5] "l" Vector__XXX
 SG_ NOxTrkngAtv100HrFlCnsmptnBn14 : 208|16@1+ (0.5,0) [0|32127.5] "l" Vector__XXX
 SG_ NOxTAtv100HFCsptB15NTEBIN : 224|16@1+ (0.5,0) [0|32127.5] "l" Vector__XXX
 SG_ NOxTAtv100HFCsptB16RB : 240|16@1+ (0.5,0) [0|32127.5] "l" Vector__XXX
 SG_ NOxTAtv100HFCsptB17MILOB : 256|16@1+ (0.5,0) [0|32127.5] "l" Vector__XXX

BO_ 2566591486 NTEHA: 200 Vector__XXX
 SG_ NOxTrkngAtv100HrEngnRnTmBn1Ttl : 0|16@1+ (10,0) [0|642550] "s" Vector__XXX
 SG_ NOxTrkngAtv100HrEngnRnTmBn2 : 16|16@1+ (10,0) [0|642550] "s" Vector__XXX
 SG_ NOxTrkngAtv100HrEngnRnTmBn3 : 32|16@1+ (10,0) [0|642550] "s" Vector__XXX
 SG_ NOxTrkngAtv100HrEngnRnTmBn4 : 48|16@1+ (10,0) [0|642550] "s" Vector__XXX
 SG_ NOxTrkngAtv100HrEngnRnTmBn5 : 64|16@1+ (10,0) [0|642550] "s" Vector__XXX
 SG_ NOxTrkngAtv100HrEngnRnTmBn6 : 80|16@1+ (10,0) [0|642550] "s" Vector__XXX
 SG_ NOxTrkngAtv100HrEngnRnTmBn7 : 96|16@1+ (10,0) [0|642550] "s" Vector__XXX
 SG_ NOxTrkngAtv100HrEngnRnTmBn8 : 112|16@1+ (10,0) [0|642550] "s" Vector__XXX
 SG_ NOxTrkngAtv100HrEngnRnTmBn9 : 128|16@1+ (10,0) [0|642550] "s" Vector__XXX
 SG_ NOxTrkngAtv100HrEngnRnTmBn10 : 144|16@1+ (10,0) [0|642550] "s" Vector__XXX
 SG_ NOxTrkngAtv100HrEngnRnTmBn11 : 160|16@1+ (10,0) [0|642550] "s" Vector__XXX
 SG_ NOxTrkngAtv100HrEngnRnTmBn12 : 176|16@1+ (10,0) [0|642550] "s" Vector__XXX
 SG_ NOxTrkngAtv100HrEngnRnTmBn13 : 192|16@1+ (10,0) [0|642550] "s" Vector__XXX
 SG_ NOxTrkngAtv100HrEngnRnTmBn14 : 208|16@1+ (10,0) [0|642550] "s" Vector__XXX
 SG_ NOxTAtv100HERTB15NTEBIN : 224|16@1+ (10,0) [0|642550] "s" Vector__XXX
 SG_ NOxTAtv100HERTB16RB : 240|16@1+ (10,0) [0|642550] "s" Vector__XXX
 SG_ NOxTAtv100HERTB17MILOB : 256|16@1+ (10,0) [0|642550] "s" Vector__XXX

BO_ 2566591742 NTVMA: 200 Vector__XXX
 SG_ NOxTrkngAtv100HrVhlDstnBn1Ttl : 0|16@1+ (0.25,0) [0|16063.75] "km" Vector__XXX
 SG_ NOxTrkngAtv100HrVhlDstnBn2 : 16|16@1+ (0.25,0) [0|16063.75] "km" Vector__XXX
 SG_ NOxTrkngAtv100HrVhlDstnBn3 : 32|16@1+ (0.25,0) [0|16063.75] "km" Vector__XXX
 SG_ NOxTrkngAtv100HrVhlDstnBn4 : 48|16@1+ (0.25,0) [0|16063.75] "km" Vector__XXX
 SG_ NOxTrkngAtv100HrVhlDstnBn5 : 64|16@1+ (0.25,0) [0|16063.75] "km" Vector__XXX
 SG_ NOxTrkngAtv100HrVhlDstnBn6 : 80|16@1+ (0.25,0) [0|16063.75] "km" Vector__XXX
 SG_ NOxTrkngAtv100HrVhlDstnBn7 : 96|16@1+ (0.25,0) [0|16063.75] "km" Vector__XXX
 SG_ NOxTrkngAtv100HrVhlDstnBn8 : 112|16@1+ (0.25,0) [0|16063.75] "km" Vector__XXX
 SG_ NOxTrkngAtv100HrVhlDstnBn9 : 128|16@1+ (0.25,0) [0|16063.75] "km" Vector__XXX
 SG_ NOxTrkngAtv100HrVhlDstnBn10 : 144|16@1+ (0.25,0) [0|16063.75] "km" Vector__XXX
 SG_ NOxTrkngAtv100HrVhlDstnBn11 : 160|16@1+ (0.25,0) [0|16063.75] "km" Vector__XXX
 SG_ NOxTrkngAtv100HrVhlDstnBn12 : 176|16@1+ (0.25,0) [0|16063.75] "km" Vector__XXX
 SG_ NOxTrkngAtv100HrVhlDstnBn13 : 192|16@1+ (0.25,0) [0|16063.75] "km" Vector__XXX
 SG_ NOxTrkngAtv100HrVhlDstnBn14 : 208|16@1+ (0.25,0) [0|16063.75] "km" Vector__XXX
 SG_ NOxTAtv100HVDstB15NTEBIN : 224|16@1+ (0.25,0) [0|16063.75] "km" Vector__XXX
 SG_ NOxTAtv100HVDstB16RB : 240|16@1+ (0.25,0) [0|16063.75] "km" Vector__XXX
 SG_ NOxTAtv100HVDstB17MILOB : 256|16@1+ (0.25,0) [0|16063.75] "km" Vector__XXX

BO_ 2566591998 NTEEA: 200 Vector__XXX
 SG_ NOxTAtv100HEOtptEB1Tt : 0|16@1+ (1,0) [0|64255] "kWh" Vector__XXX
 SG_ NOxTrkngAtv100HrEngnOtptEnrgBn2 : 16|16@1+ (1,0) [0|64255] "kWh" Vector__XXX
 SG_ NOxTrkngAtv100HrEngnOtptEnrgBn3 : 32|16@1+ (1,0) [0|64255] "kWh" Vector__XXX
 SG_ NOxTrkngAtv100HrEngnOtptEnrgBn4 : 48|16@1+ (1,0) [0|64255] "kWh" Vector__XXX
 SG_ NOxTrkngAtv100HrEngnOtptEnrgBn5 : 64|16@1+ (1,0) [0|64255] "kWh" Vector__XXX
 SG_ NOxTrkngAtv100HrEngnOtptEnrgBn6 : 80|16@1+ (1,0) [0|64255] "kWh" Vector__XXX
 SG_ NOxTrkngAtv100HrEngnOtptEnrgBn7 : 96|16@1+ (1,0) [0|64255] "kWh" Vector__XXX
 SG_ NOxTrkngAtv100HrEngnOtptEnrgBn8 : 112|16@1+ (1,0) [0|64255] "kWh" Vector__XXX
 SG_ NOxTrkngAtv100HrEngnOtptEnrgBn9 : 128|16@1+ (1,0) [0|64255] "kWh" Vector__XXX
 SG_ NOxTAtv100HEOtptEB10 : 144|16@1+ (1,0) [0|64255] "kWh" Vector__XXX
 SG_ NOxTAtv100HEOtptEB11 : 160|16@1+ (1,0) [0|64255] "kWh" Vector__XXX
 SG_ NOxTAtv100HEOtptEB12 : 176|16@1+ (1,0) [0|64255] "kWh" Vector__XXX
 SG_ NOxTAtv100HEOtptEB13 : 192|16@1+ (1,0) [0|64255] "kWh" Vector__XXX
 SG_ NOxTAtv100HEOtptEB14 : 208|16@1+ (1,0) [0|64255] "kWh" Vector__XXX
 SG_ NOxTAtv100HEOtptEB15NTEBIN : 224|16@1+ (1,0) [0|64255] "kWh" Vector__XXX
 SG_ NOxTAtv100HEOtptEB16RB : 240|16@1+ (1,0) [0|64255] "kWh" Vector__XXX
 SG_ NOxTAtv100HEOtptEB17MILOB : 256|16@1+ (1,0) [0|64255] "kWh" Vector__XXX

BO_ 2566592254 NTENA: 200 Vector__XXX
 SG_ NOxTAtv100HEOtNOxMssB1Tt : 0|32@1+ (0.0005,0) [0|2105540.6075] "g" Vector__XXX
 SG_ NOxTrkngAtv100HrEngnOtNOxMssBn2 : 32|32@1+ (0.0005,0) [0|2105540.6075] "g" Vector__XXX
 SG_ NOxTrkngAtv100HrEngnOtNOxMssBn3 : 64|32@1+ (0.0005,0) [0|2105540.6075] "g" Vector__XXX
 SG_ NOxTrkngAtv100HrEngnOtNOxMssBn4 : 96|32@1+ (0.0005,0) [0|2105540.6075] "g" Vector__XXX
 SG_ NOxTrkngAtv100HrEngnOtNOxMssBn5 : 128|32@1+ (0.0005,0) [0|2105540.6075] "g" Vector__XXX
 SG_ NOxTrkngAtv100HrEngnOtNOxMssBn6 : 160|32@1+ (0.0005,0) [0|2105540.6075] "g" Vector__XXX
 SG_ NOxTrkngAtv100HrEngnOtNOxMssBn7 : 192|32@1+ (0.0005,0) [0|2105540.6075] "g" Vector__XXX
 SG_ NOxTrkngAtv100HrEngnOtNOxMssBn8 : 224|32@1+ (0.0005,0) [0|2105540.6075] "g" Vector__XXX
 SG_ NOxTrkngAtv100HrEngnOtNOxMssBn9 : 256|32@1+ (0.0005,0) [0|2105540.6075] "g" Vector__XXX
 SG_ NOxTAtv100HEOtNOxMssB10 : 288|32@1+ (0.0005,0) [0|2105540.6075] "g" Vector__XXX
 SG_ NOxTAtv100HEOtNOxMssB11 : 320|32@1+ (0.0005,0) [0|2105540.6075] "g" Vector__XXX
 SG_ NOxTAtv100HEOtNOxMssB12 : 352|32@1+ (0.0005,0) [0|2105540.6075] "g" Vector__XXX
 SG_ NOxTAtv100HEOtNOxMssB13 : 384|32@1+ (0.0005,0) [0|2105540.6075] "g" Vector__XXX
 SG_ NOxTAtv100HEOtNOxMssB14 : 416|32@1+ (0.0005,0) [0|2105540.6075] "g" Vector__XXX
 SG_ NOxTAtv100HEOtNOxMssB15NTEBIN : 448|32@1+ (0.0005,0) [0|2105540.6075] "g" Vector__XXX
 SG_ NOxTAtv100HEOtNOxMssB16RB : 480|32@1+ (0.0005,0) [0|2105540.6075] "g" Vector__XXX
 SG_ NOxTAtv100HEOtNOxMssB17MILOB : 512|32@1+ (0.0005,0) [0|2105540.6075] "g" Vector__XXX

BO_ 2566592510 NTSNA: 200 Vector__XXX
 SG_ NOxTAtv100HSstOtNOxMssB1Tt : 0|32@1+ (0.0002,0) [0|842216.243] "g" Vector__XXX
 SG_ NOxTrkngAtv100HrSstmOtNOxMssBn2 : 32|32@1+ (0.0002,0) [0|842216.243] "g" Vector__XXX
 SG_ NOxTrkngAtv100HrSstmOtNOxMssBn3 : 64|32@1+ (0.0002,0) [0|842216.243] "g" Vector__XXX
 SG_ NOxTrkngAtv100HrSstmOtNOxMssBn4 : 96|32@1+ (0.0002,0) [0|842216.243] "g" Vector__XXX
 SG_ NOxTrkngAtv100HrSstmOtNOxMssBn5 : 128|32@1+ (0.0002,0) [0|842216.243] "g" Vector__XXX
 SG_ NOxTrkngAtv100HrSstmOtNOxMssBn6 : 160|32@1+ (0.0002,0) [0|842216.243] "g" Vector__XXX
 SG_ NOxTrkngAtv100HrSstmOtNOxMssBn7 : 192|32@1+ (0.0002,0) [0|842216.243] "g" Vector__XXX
 SG_ NOxTrkngAtv100HrSstmOtNOxMssBn8 : 224|32@1+ (0.0002,0) [0|842216.243] "g" Vector__XXX
 SG_ NOxTrkngAtv100HrSstmOtNOxMssBn9 : 256|32@1+ (0.0002,0) [0|842216.243] "g" Vector__XXX
 SG_ NOxTAtv100HSstOtNOxMssB10 : 288|32@1+ (0.0002,0) [0|842216.243] "g" Vector__XXX
 SG_ NOxTAtv100HSstOtNOxMssB11 : 320|32@1+ (0.0002,0) [0|842216.243] "g" Vector__XXX
 SG_ NOxTAtv100HSstOtNOxMssB12 : 352|32@1+ (0.0002,0) [0|842216.243] "g" Vector__XXX
 SG_ NOxTAtv100HSstOtNOxMssB13 : 384|32@1+ (0.0002,0) [0|842216.243] "g" Vector__XXX
 SG_ NOxTAtv100HSstOtNOxMssB14 : 416|32@1+ (0.0002,0) [0|842216.243] "g" Vector__XXX
 SG_ NOxTAtv100HSstOtNOxMssB15NTEBIN : 448|32@1+ (0.0002,0) [0|842216.243] "g" Vector__XXX
 SG_ NOxTAtv100HSstOtNOxMssB16RB : 480|32@1+ (0.0002,0) [0|842216.243] "g" Vector__XXX
 SG_ NOxTAtv100HSstOtNOxMssB17MILOB : 512|32@1+ (0.0002,0) [0|842216.243] "g" Vector__XXX

BO_ 2365266174 MG6IC2: 8 Vector__XXX
 SG_ MtrGnrtr6InvrtrRtLmtsRqst2CRC : 0|8@1+ (1,0) [0|255] "count" Vector__XXX
 SG_ MtrGnrtr6InvrtrRtLmtsRqst2Cntr : 8|4@1+ (1,0) [0|15] "" Vector__XXX
 SG_ MtrGnrtr6InvrtrPIDCntrlAppllMd : 12|4@1+ (1,0) [0|15] "" Vector__XXX
 SG_ MtGt6IvtPIDCtNzdDtG : 16|8@1+ (11689,0) [0|7.8125] "%/(%/s)" Vector__XXX
 SG_ MtGt6IvtPIDCtNzdItG : 24|16@1+ (23377,0) [0|1003.984375] "%/(%/s)" Vector__XXX
 SG_ MtGt6IvtPIDCtNzdPptG : 40|12@1+ (42370,0) [0|250.9375] "%/%" Vector__XXX
 SG_ MtGt6IvtPIDCtFdFwdTq : 52|12@1+ (42370,-125) [-125|125.9375] "%" Vector__XXX

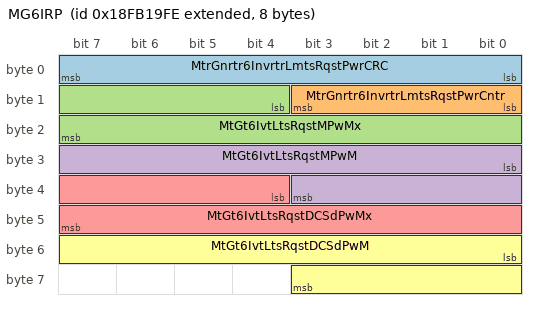
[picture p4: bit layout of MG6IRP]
BO_ 2566593022 MG6IRP: 8 Vector__XXX
 SG_ MtrGnrtr6InvrtrLmtsRqstPwrCRC : 0|8@1+ (1,0) [0|255] "count" Vector__XXX
 SG_ MtrGnrtr6InvrtrLmtsRqstPwrCntr : 8|4@1+ (1,0) [0|15] "" Vector__XXX
 SG_ MtGt6IvtLtsRqstMPwMx : 12|12@1+ (42370,-125) [-125|125.9375] "%" Vector__XXX
 SG_ MtGt6IvtLtsRqstMPwM : 24|12@1+ (42370,-125) [-125|125.9375] "%" Vector__XXX
 SG_ MtGt6IvtLtsRqstDCSdPwMx : 36|12@1+ (42370,-125) [-125|125.9375] "%" Vector__XXX
 SG_ MtGt6IvtLtsRqstDCSdPwM : 48|12@1+ (42370,-125) [-125|125.9375] "%" Vector__XXX

CM_ BO_ 2566574846 "Turbocharger Information 8";
CM_ SG_ 2566574846 EngnTrhrgr3OlTmprtr "Engine Turbocharger 3 Oil Temperature: Temperature of the lubricant for the third turbocharger.";
CM_ SG_ 2566574846 EngnTrhrgr4OlTmprtr "Engine Turbocharger 4 Oil Temperature: Temperature of the lubricant for the fourth turbocharger.";
CM_ SG_ 2566574846 EngnTrhrgr5OlTmprtr "Engine Turbocharger 5 Oil Temperature: Temperature of the lubricant for the fifth turbocharger.";
CM_ SG_ 2566574846 EngnTrhrgr6OlTmprtr "Engine Turbocharger 6 Oil Temperature: Temperature of the lubricant for the sixth turbocharger.";
CM_ BO_ 2566575102 "Automated Driving System Control";
CM_ SG_ 2566575102 TSC1CntrlPrpsP7InhtCmmnd "TSC1 Control Purpose P7 Inhibit Command: Signal which indicates sending TSC1 Control Purpose P7 is inhibited or not. Devices shall not send TSC1 Control Purpose P7 when the received SPN 12868 (TSC1 Control Purpose P7 Inhibit Command) is 01b. If those...";
CM_ BO_ 2566575358 "EVSE 1 AC Status 2";
CM_ SG_ 2566575358 EVSE1ACRMSCurrent "EVSE1 AC RMS Current: AC RMS current being drawn from the EVSE.Negative values indicate power being drained from the vehicle and returned to the grid.";
CM_ SG_ 2566575358 EVSE1ACRMSVoltage "EVSE1 AC RMS Voltage: AC RMS Voltage of this connected EVSE supply.";
CM_ BO_ 2566575614 "EVSE 1 AC Status 1";
CM_ SG_ 2566575614 EVSEACRMSCurrentLimitL1 "EVSE AC RMS Current Limit L1: Maximum AC RMS current that can be supplied by the EVSE on a single phase AC supply or L1 of a 3-phase AC supply.";
CM_ SG_ 2566575614 EVSEACRMSCurrentLimitL2 "EVSE AC RMS Current Limit L2: Maximum AC RMS current that can be supplied by the EVSE on L2 of a 3-phase AC supply.";
CM_ SG_ 2566575614 EVSEACRMSCurrentLimitL3 "EVSE AC RMS Current Limit L3: Maximum AC RMS current that can be supplied by the EVSE on L3 of a 3-phase AC supply.";
CM_ SG_ 2566575614 EVSEACRMSCurrentLimitNeutral "EVSE AC RMS Current Limit Neutral: Maximum AC RMS current that can carried on the neutral connection from the EVSE.If this parameter is set to 0 A then only symmetrical 3-phase operation is allowed.";
CM_ BO_ 2566575870 "EVSE 1 Status 1";
CM_ SG_ 2566575870 EVSE1ConnectorReleaseLatch "EVSE1 Connector Release Latch: Indicates the Release Latch status of this EVSE Connector.J1772 and IEC-61851-1 describes a momentary push-to-break switch (S3) that will be opened when the Release Latch is operated prior to removal of the connector.00...";
CM_ SG_ 2566575870 EVSE1ManualOverride "EVSE1 Manual Override: Indicates the state of a manual override switch on the vehicle, if present. The switch may be used to disable charging and unlock the the connector.00b = Manual override not active01b = Manual override active10b = Error11b = No...";
CM_ SG_ 2566575870 EVSE1ConnectorLockState "EVSE1 Connector Lock State: Indicates the state of this EVSE Connector Lock (if present).000b = Unlocked001b = Locked010b = In transition to/from Locked011b = Reserved100b = Reserved101b = No locking mechanism is available on this vehicle110b = Error...";
CM_ BO_ 2566581758 "Temperature Sensing Module 1";
CM_ SG_ 2566581758 TmprtrSnsngMdl1PrlmnrFMI "Temperature Sensing Module 1 Preliminary FMI: Used to identify the applicable J1939-73 FMI detected in the Temperature Sensing Module 1 by the manufacturer's software. When there are multiple failures, the most severe is transmitted.  A value of 31 i...";
CM_ SG_ 2566581758 TmprtrSnsngMdl2PrlmnrFMI "Temperature Sensing Module 2 Preliminary FMI: Used to identify the applicable J1939-73 FMI detected in the Temperature Sensing Module 2 by the manufacturer's software. When there are multiple failures, the most severe is transmitted.  A value of 31 i...";
CM_ SG_ 2566581758 TmprtrSnsngMdl3PrlmnrFMI "Temperature Sensing Module 3 Preliminary FMI: Used to identify the applicable J1939-73 FMI detected in the Temperature Sensing Module 3 by the manufacturer's software. When there are multiple failures, the most severe is transmitted.  A value of 31 i...";
CM_ SG_ 2566581758 TmprtrSnsngMdl4PrlmnrFMI "Temperature Sensing Module 4 Preliminary FMI: Used to identify the applicable J1939-73 FMI detected in the Temperature Sensing Module 4 by the manufacturer's software. When there are multiple failures, the most severe is transmitted.  A value of 31 i...";
CM_ SG_ 2566581758 TmprtrSnsngMdl5PrlmnrFMI "Temperature Sensing Module 5 Preliminary FMI: Used to identify the applicable J1939-73 FMI detected in the Temperature Sensing Module 5 by the manufacturer's software. When there are multiple failures, the most severe is transmitted.  A value of 31 i...";
CM_ SG_ 2566581758 TmprtrSnsngMdl6PrlmnrFMI "Temperature Sensing Module 6 Preliminary FMI: Used to identify the applicable J1939-73 FMI detected in the Temperature Sensing Module 6 by the manufacturer's software. When there are multiple failures, the most severe is transmitted.  A value of 31 i...";
CM_ SG_ 2566581758 TmprtrSnsngMdl7PrlmnrFMI "Temperature Sensing Module 7 Preliminary FMI: Used to identify the applicable J1939-73 FMI detected in the Temperature Sensing Module 7 by the manufacturer's software. When there are multiple failures, the most severe is transmitted.  A value of 31 i...";
CM_ SG_ 2566581758 TmprtrSnsngMdl8PrlmnrFMI "Temperature Sensing Module 8 Preliminary FMI: Used to identify the applicable J1939-73 FMI detected in the Temperature Sensing Module 8 by the manufacturer's software. When there are multiple failures, the most severe is transmitted.  A value of 31 i...";
CM_ BO_ 2566582014 "Temperature Sensing Module 2";
CM_ SG_ 2566582014 TmprtrSnsngMdl9PrlmnrFMI "Temperature Sensing Module 9 Preliminary FMI: Used to identify the applicable J1939-73 FMI detected in the Temperature Sensing Module 9 by the manufacturer's software. When there are multiple failures, the most severe is transmitted.  A value of 31 i...";
CM_ SG_ 2566582014 TmprtrSnsngMdl10PrlmnrFMI "Temperature Sensing Module 10 Preliminary FMI: Used to identify the applicable J1939-73 FMI detected in the Temperature Sensing Module 10 by the manufacturer's software. When there are multiple failures, the most severe is transmitted.  A value of 31...";
CM_ SG_ 2566582014 TmprtrSnsngMdl11PrlmnrFMI "Temperature Sensing Module 11 Preliminary FMI: Used to identify the applicable J1939-73 FMI detected in the Temperature Sensing Module 11 by the manufacturer's software. When there are multiple failures, the most severe is transmitted.  A value of 31...";
CM_ SG_ 2566582014 TmprtrSnsngMdl12PrlmnrFMI "Temperature Sensing Module 12 Preliminary FMI: Used to identify the applicable J1939-73 FMI detected in the Temperature Sensing Module 12 by the manufacturer's software. When there are multiple failures, the most severe is transmitted.  A value of 31...";
CM_ SG_ 2566582014 TmprtrSnsngMdl13PrlmnrFMI "Temperature Sensing Module 13 Preliminary FMI: Used to identify the applicable J1939-73 FMI detected in the Temperature Sensing Module 13 by the manufacturer's software. When there are multiple failures, the most severe is transmitted.  A value of 31...";
CM_ SG_ 2566582014 TmprtrSnsngMdl14PrlmnrFMI "Temperature Sensing Module 14 Preliminary FMI: Used to identify the applicable J1939-73 FMI detected in the Temperature Sensing Module 14 by the manufacturer's software. When there are multiple failures, the most severe is transmitted.  A value of 31...";
CM_ SG_ 2566582014 TmprtrSnsngMdl15PrlmnrFMI "Temperature Sensing Module 15 Preliminary FMI: Used to identify the applicable J1939-73 FMI detected in the Temperature Sensing Module 15 by the manufacturer's software. When there are multiple failures, the most severe is transmitted.  A value of 31...";
CM_ SG_ 2566582014 TmprtrSnsngMdl16PrlmnrFMI "Temperature Sensing Module 16 Preliminary FMI: Used to identify the applicable J1939-73 FMI detected in the Temperature Sensing Module 16 by the manufacturer's software. When there are multiple failures, the most severe is transmitted.  A value of 31...";
CM_ BO_ 2566582270 "Aftertreatment 2 SCR Service Information 3";
CM_ SG_ 2566582270 Aftrtrtmnt2SCRNrmlzdCnvrsnEffn "Aftertreatment 2 SCR Normalized Conversion Efficiency: The ratio of measured SCR Catalyst conversion efficiency to the estimated nominal SCR Catalyst conversion efficiency, represented as a percentage.";
CM_ BO_ 2566582526 "Aftertreatment 1 SCR Service Information 3";
CM_ SG_ 2566582526 Aftrtrtmnt1SCRNrmlzdCnvrsnEffn "Aftertreatment 1 SCR Normalized Conversion Efficiency: The ratio of measured SCR Catalyst conversion efficiency to the estimated nominal SCR Catalyst conversion efficiency, represented as a percentage.";
CM_ BO_ 2566582782 "PSA Times Lifetime Hours";
CM_ SG_ 2566582782 HrdLftmPrplsnSstmAtvTm "Hybrid Lifetime Propulsion System Active Time : Total propulsion system active time during the lifetime of the vehicle. OBD requires all hybrids to support this parameter. ";
CM_ SG_ 2566582782 HrdLftmIdlPrplsnSstmAtvTm "Hybrid Lifetime Idle Propulsion System Active Time : Total idle propulsion system active time (v <= 1.6 km/h) during the lifetime of the vehicle. OBD requires all hybrids to support this parameter.";
CM_ SG_ 2566582782 HrdLftmUrnPrplsnSstmAtvTm "Hybrid Lifetime Urban Propulsion System Active Time : Total urban (1.6 km/h < v <= 60 km/h) propulsion system active time during the lifetime of the vehicle. OBD requires all hybrids to support this parameter.";
CM_ BO_ 2566583038 "PSA Times Stored 100 Hours";
CM_ SG_ 2566583038 HrdStrd100HrRntPrplsnSstmAtvTm "Hybrid Stored 100 Hour Recent Propulsion System Active Time : Most recent stored cumulative propulsion system active time during 100 hours of vehicle operation. OBD requires all hybrids to support this parameter. ";
CM_ SG_ 2566583038 HrdStrd100HrIdlPrplsnSstmAtvTm "Hybrid Stored 100 Hour Idle Propulsion System Active Time: Most recent stored cumulative idle (v <= 1.6 km/h) propulsion system active time during 100 hours of vehicle operation. OBD requires all hybrids to support this parameter.";
CM_ SG_ 2566583038 HrdStrd100HrUrnPrplsnSstmAtvTm "Hybrid Stored 100 Hour Urban Propulsion System Active Time : Most recent stored cumulative urban (1.6 km/h < v <= 60 km/h) propulsion system active time during 100 hours of vehicle operation. OBD requires all hybrids to support this parameter.";
CM_ BO_ 2566583294 "PSA Times Active 100 Hours";
CM_ SG_ 2566583294 HrdAtv100HrPrplsnSstmAtvTm "Hybrid Active 100 Hour Propulsion System Active Time : Cumulative propulsion system active time during recent operation (time < 100 hours). OBD requires all hybrids to support this parameter.";
CM_ SG_ 2566583294 HrdAtv100HrIdlPrplsnSstmAtvTm "Hybrid Active 100 Hour Idle Propulsion System Active Time : Cumulative idle (v <= 1.6 km/h) propulsion system active time during recent operation (time < 100 hours). OBD requires all hybrids to support this parameter.";
CM_ SG_ 2566583294 HrdAtv100HrUrnPrplsnSstmAtvTm "Hybrid Active 100 Hour Urban Propulsion System Active Time : Cumulative urban  (1.6 km/h < v <= 60 km/h) propulsion system active time during recent operation (time < 100 hours). OBD requires all hybrids to support this parameter.";
CM_ BO_ 2566583550 "Hybrid Charge Depleting or Increasing Operation Lifetime Hours";
CM_ SG_ 2566583550 HdLtDstTvdCDptOptwtE "Hybrid Lifetime Distance Traveled in Charge Depleting Operation with Engine off : Total distance traveled while in charge depleting operation with engine off during the lifetime of the vehicle. OBD requires hybrids that are plugin vehicles to support...";
CM_ SG_ 2566583550 HdLtDstTvdCDptOptwtER "Hybrid Lifetime Distance Traveled in Charge Depleting Operation with Engine Running : Total distance traveled while in charge depleting operation with engine running during the lifetime of the vehicle. OBD requires hybrids that are plugin vehicles to...";
CM_ SG_ 2566583550 HdLtDstTvdDvStCIsOpt "Hybrid Lifetime Distance Traveled in Driver-Selectable Charge Increasing Operation : Total distance traveled while in driver-selectable charge increasing operation during the lifetime of the vehicle. OBD requires hybrids that are plugin vehicles to s...";
CM_ SG_ 2566583550 HrdLftmFlCnsmdnChrgDpltngOprtn "Hybrid Lifetime Fuel Consumed in Charge Depleting Operation : Total fuel consumption during charge-depleting operation during the lifetime of the vehicle. OBD requires hybrids that are plugin vehicles to support this parameter.  ";
CM_ SG_ 2566583550 HdLtFCsdDvStCIsOpt "Hybrid Lifetime Fuel Consumed in Driver-Selectable Charge Increasing Operation : Total fuel consumption during driver-selectable charge increasing operation during the lifetime of the vehicle. OBD requires hybrids that are plugin vehicles to support ...";
CM_ SG_ 2566583550 HdLtGdECsdCDptOptwtE "Hybrid Lifetime Grid Energy Consumed in Charge Depleting Operation with Engine off : Total grid energy supplied by the battery pack in charge depleting operation with engine off during the lifetime of the vehicle. OBD requires hybrids that are plugin...";
CM_ SG_ 2566583550 HdLtGdECsdCDptOptwtER "Hybrid Lifetime Grid Energy Consumed in Charge Depleting Operation with Engine Running : Total grid energy supplied by the battery pack in charge depleting operation with engine running during the lifetime of the vehicle. OBD requires hybrids that ar...";
CM_ SG_ 2566583550 HrdLftmGrdEnrgntthBttr "Hybrid Lifetime Grid Energy into the Battery : Total grid energy into the battery during the lifetime of the vehicle. OBD requires hybrids that are plugin vehicles to support this parameter.  ";
CM_ BO_ 2566583806 "Hybrid Charge Depleting or Increasing Operation Stored 100 Hours";
CM_ SG_ 2566583806 HdStd100HDstTvdCDptOptwtE "Hybrid Stored 100 Hour Distance Traveled in Charge Depleting Operation with Engine off : Most recent stored 100-hour cumulative distance traveled while in charge depleting operation with engine off. OBD requires hybrids that are plugin vehicles to su...";
CM_ SG_ 2566583806 HdStd100HDstTvdCDptOptwtER "Hybrid Stored 100 Hour Distance Traveled in Charge Depleting Operation with Engine Running : Most recent stored 100-hour cumulative distance traveled while in charge depleting operation with engine running. OBD requires hybrids that are plugin vehicl...";
CM_ SG_ 2566583806 HdStd100HDstTvdDvStCIsOpt "Hybrid Stored 100 Hour Distance Traveled in Driver-Selectable Charge Increasing Operation : Most recent stored 100-hour cumulative distance traveled while in driver-selectable charge increasing operation. OBD requires hybrids that are plugin vehicles...";
CM_ SG_ 2566583806 HdStd100HFCsdCDptOpt "Hybrid Stored 100 Hour Fuel Consumed in Charge Depleting Operation : Most recent stored 100-hour cumulative fuel consumed during charge-depleting operation. OBD requires hybrids that are plugin vehicles to support this parameter.  ";
CM_ SG_ 2566583806 HdStd100HFCsdDvStCIsOpt "Hybrid Stored 100 Hour Fuel Consumed in Driver-Selectable Charge Increasing Operation : Most recent stored 100-hour cumulative fuel consumed during charge-depleting operation. OBD requires hybrids that are plugin vehicles to support this parameter.  ";
CM_ SG_ 2566583806 HdStd100HGdECsdCDptOptwtE "Hybrid Stored 100 Hour Grid Energy Consumed in Charge Depleting Operation with Engine off : Most recent stored 100-hour cumulative grid energy consumed during charge depleting operation with engine off. OBD requires hybrids that are plugin vehicles t...";
CM_ SG_ 2566583806 HdStd100HGdECsdCDptOptwtER "Hybrid Stored 100 Hour Grid Energy Consumed in Charge Depleting Operation with Engine Running : Most recent stored 100-hour cumulative grid energy consumed during charge depleting operation with engine running. OBD requires hybrids that are plugin ve...";
CM_ SG_ 2566583806 HrdStrd100HrGrdEnrgntthBttr "Hybrid Stored 100 Hour Grid Energy into the Battery : Most recent stored 100-hour cumulative grid energy into the Battery. OBD requires hybrids that are plugin vehicles to support this parameter.  ";
CM_ BO_ 2566584062 "Hybrid Charge Depleting or Increasing Operation Active 100 Hours";
CM_ SG_ 2566584062 HdAtv100HDstTvdCDptOptwtE "Hybrid Active 100 Hour Distance Traveled in Charge Depleting Operation with Engine off : Cumulative distance traveled while in charge depleting operation with engine off during recent operation (time < 100 hours). OBD requires hybrids that are plugin...";
CM_ SG_ 2566584062 HdAtv100HDstTvdCDptOptwtER "Hybrid Active 100 Hour Distance Traveled in Charge Depleting Operation with Engine Running : Cumulative distance traveled while in charge depleting operation with engine running during recent operation (time < 100 hours). OBD requires hybrids that ar...";
CM_ SG_ 2566584062 HdAtv100HDstTvdDvStCIsOpt "Hybrid Active 100 Hour Distance Traveled in Driver-Selectable Charge Increasing Operation : Cumulative distance traveled while in driver-selectable charge increasing operation during recent operation (time < 100 hours). OBD requires hybrids that are ...";
CM_ SG_ 2566584062 HdAtv100HFCsdCDptOpt "Hybrid Active 100 Hour Fuel Consumed in Charge Depleting Operation : Cumulative fuel consumption during charge-depleting operation during recent operation (time < 100 hours). OBD requires hybrids that are plugin vehicles to support this parameter.  ";
CM_ SG_ 2566584062 HdAtv100HFCsdDvStCIsOpt "Hybrid Active 100 Hour Fuel Consumed in Driver-Selectable Charge Increasing Operation : Cumulative fuel consumption during driver-selectable charge increasing operation during recent operation (time < 100 hours). OBD requires hybrids that are plugin ...";
CM_ SG_ 2566584062 HdAtv100HGdECsdCDptOptwtE "Hybrid Active 100 Hour Grid Energy Consumed in Charge Depleting Operation with Engine off : Cumulative grid energy supplied by the battery pack in charge depleting operation with engine off during recent operation (time < 100 hours). OBD requires hyb...";
CM_ SG_ 2566584062 HdAtv100HGdECsdCDptOptwtER "Hybrid Active 100 Hour Grid Energy Consumed in Charge Depleting Operation with Engine Running : Cumulative grid energy supplied by the battery pack in charge depleting operation with engine running during recent operation (time < 100 hours). OBD requ...";
CM_ SG_ 2566584062 HrdAtv100HrGrdEnrgntthBttr "Hybrid Active 100 Hour Grid Energy into the Battery : Cumulative grid energy into the battery during recent operation (time < 100 hours). OBD requires hybrids that are plugin vehicles to support this parameter.  ";
CM_ BO_ 2566584318 "Aftertreatment 1 Historical Information 3";
CM_ SG_ 2566584318 Atttt1DPFRCptSttEVDst1 "Aftertreatment 1 DPF Regen Complete Starting Engine Vehicle Distance 1: The engine vehicle distance for the initiation of instance one of the last 3 complete DPF regenerations. Note: Engine vehicle distance data need not be presented in ascending ord...";
CM_ SG_ 2566584318 Atttt1DPFRCptEdEVDst1 "Aftertreatment 1 DPF Regen Complete Ending Engine Vehicle Distance 1: The engine vehicle distance for the completion of instance one of the last 3 complete DPF regenerations. Note: Engine vehicle distance data need not be presented in ascending order...";
CM_ SG_ 2566584318 Atttt1DPFRCptSttEVDst2 "Aftertreatment 1 DPF Regen Complete Starting Engine Vehicle Distance 2: The engine vehicle distance for the initiation of instance two of the last 3 complete DPF regenerations. Note: Engine vehicle distance data need not be presented in ascending ord...";
CM_ SG_ 2566584318 Atttt1DPFRCptEdEVDst2 "Aftertreatment 1 DPF Regen Complete Ending Engine Vehicle Distance 2: The engine vehicle distance for the completion of instance two of the last 3 complete DPF regenerations. Note: Engine vehicle distance data need not be presented in ascending order...";
CM_ SG_ 2566584318 Atttt1DPFRCptSttEVDst3 "Aftertreatment 1 DPF Regen Complete Starting Engine Vehicle Distance 3: The engine vehicle distance for the initiation of instance three of the last 3 complete DPF regenerations. Note: Engine vehicle distance data need not be presented in ascending o...";
CM_ SG_ 2566584318 Atttt1DPFRCptEdEVDst3 "Aftertreatment 1 DPF Regen Complete Ending Engine Vehicle Distance 3: The engine vehicle distance for the completion of instance three of the last 3 complete DPF regenerations.Note: Engine vehicle distance data need not be presented in ascending orde...";
CM_ SG_ 2566584318 Atttt1TtERtWtNDEFDv "Aftertreatment 1 Total Engine Runtime With No DEF Delivery: Total engine run time with no delivery of reductant (e.g., diesel exhaust fluid) used to control NOx emissions due to insufficient exhaust temperature, DEF quality, Insufficent DEF quantity,...";
CM_ SG_ 2566584318 Atttt1TtTSCRItBw200Css "Aftertreatment 1 Total Time SCR Inlet Below 200 Celsius: Total engine run time with exhaust temperature below 200 degrees Celsius as measured just upstream of the NOx converting catalyst. Note: If an engine has more than one NOx converting catalyst, ...";
CM_ BO_ 2566584830 "Aftertreatment 1 SCR 2 NOx Mass and NH3 Storage";
CM_ SG_ 2566584830 Aftrtrtmnt1SCR2InltNOxMssFlw "Aftertreatment 1 SCR 2 Inlet NOx Mass Flow: The mass flow of the NOx in the engine exhaust stream before the second NOx converting catalyst in aftertreatment 1.This SP provides the NOx mass flow for the outlet of the first SCR catalyst for systems wi...";
CM_ SG_ 2566584830 Aftrtrtmnt1SCR2OtltNOxMssFlw "Aftertreatment 1 SCR 2 Outlet NOx Mass Flow: The mass flow of the NOx in the engine exhaust stream after the NOx converting catalyst in aftertreatment 2.This SP shall be omitted for aftertreatment systems with exhaust flow through sequential SCR cata...";
CM_ SG_ 2566584830 Aftrtrtmnt1SCR2MdldNH3StrgLvl "Aftertreatment 1 SCR 2 Modeled NH3 Storage Level: The modeled or actual NH3 storage level in the second SCR catalyst in aftertreatment 1.";
CM_ SG_ 2566584830 Aftrtrtmnt1SCR2TrgtNH3StrgLvl "Aftertreatment 1 SCR 2 Target NH3 Storage Level: The target NH3 storage level in the second SCR catalyst in aftertreatment 1.";
CM_ BO_ 2566585086 "Aftertreatment 1 SCR 1 NOx Mass and NH3 Storage";
CM_ SG_ 2566585086 Atttt1SCR1EExstNOxMssFw "Aftertreatment 1 SCR 1 Engine Exhaust NOx Mass Flow: The mass flow of the NOx in the engine exhaust stream before the NOx converting catalyst in aftertreatment 1.If there is only one sensor that provides the engine outlet NOx mass flow in a system wi...";
CM_ SG_ 2566585086 Aftrtrtmnt1SCR1TlppNOxMssFlw "Aftertreatment 1 SCR 1 Tailpipe NOx Mass Flow: The mass flow of the NOx in the engine exhaust stream after all NOx converting catalysts in aftertreatment 1.For systems with a second, parallel flow SCR catalyst, SPN 12755 shall be used to provide the ...";
CM_ SG_ 2566585086 Aftrtrtmnt1SCR1MdldAtlStrgLvl "Aftertreatment 1 SCR 1 Modeled/Actual Storage Level: The modeled or actual NH3 storage level in the first SCR catalyst in aftertreatment 1.";
CM_ SG_ 2566585086 Aftrtrtmnt1SCR1TrgtNH3StrgLvl "Aftertreatment 1 SCR 1 Target NH3 Storage Level: The target NH3 storage level in the first SCR catalyst in aftertreatment 1.";
CM_ BO_ 2566585342 "Evaporative System Pressure and Control";
CM_ SG_ 2566585342 EVAPSystemPurgePressure "EVAP System Purge Pressure: Absolute pressure of the purge element measured in the EVAP System.";
CM_ SG_ 2566585342 EVAPSystemVaporPressure "EVAP System Vapor Pressure : Absolute pressure of the fuel vapor measured in the EVAP System.";
CM_ SG_ 2566585342 EVAPSystemPurgeValveCommand "EVAP System Purge Valve Command: Commanded relative position of the EVAP System Purge Valve ";
CM_ SG_ 2566585342 EVAPSystemPurgeValvePosition "EVAP System Purge Valve Position: Relative position of the EVAP System Purge Valve";
CM_ BO_ 2566585598 "GHG Tracking Lifetime Array Data";
CM_ SG_ 2566585598 GHGTrkngLftmEngnRnTm "GHG Tracking Lifetime Engine Run Time: Accumulated engine run time over the lifetime of the vehicle for GHG Tracking.  ";
CM_ SG_ 2566585598 GHGTrkngLftmVhlDstn "GHG Tracking Lifetime Vehicle Distance: Accumulated vehicle distance over the lifetime of the vehicle for GHG Tracking.  ";
CM_ SG_ 2566585598 GHGTrkngLftmVhlFlCnsmptn "GHG Tracking Lifetime Vehicle Fuel Consumption: Accumulated vehicle fuel consumption over the lifetime of the vehicle for GHG Tracking.  ";
CM_ SG_ 2566585598 GHGTrkngLftmEngnFlCnsmptn "GHG Tracking Lifetime Engine Fuel Consumption: Accumulated engine fuel consumption over the lifetime of the vehicle for GHG Tracking.  ";
CM_ SG_ 2566585598 GHGTrkngLftmEngnOtptEnrg "GHG Tracking Lifetime Engine Output Energy: Accumulated engine output energy over the lifetime of the vehicle for GHG Tracking.  ";
CM_ SG_ 2566585598 GHGTrkngLftmPstvKntEnrgNmrtr "GHG Tracking Lifetime Positive Kinetic Energy Numerator: Accumulated positive kinetic energy numerator (as delta-V-squared) over the lifetime of the vehicle for GHG Tracking.    The PKE Denominator is provided by GHG Tracking Lifetime Vehicle Distanc...";
CM_ SG_ 2566585598 GHGTrkngLftmUrnSpdRnTm "GHG Tracking Lifetime Urban Speed Run Time: Accumulated time at urban vehicle speeds (1.6 km/h < v <= 60 km/h) over the lifetime of the vehicle for GHG Tracking.";
CM_ SG_ 2566585598 GHGTrackingLifetimeIdleRunTime "GHG Tracking Lifetime Idle Run Time: Accumulated engine run time under idle conditions (v <= 1.6 km/h) over the lifetime of the vehicle for GHG Tracking.";
CM_ SG_ 2566585598 GHGTrkngLftmEngnIdlFlCnsmptn "GHG Tracking Lifetime Engine Idle Fuel Consumption: Accumulated fuel consumption under idle conditions (v <= 1.6 km/h) over the lifetime of the vehicle for GHG Tracking.";
CM_ SG_ 2566585598 GHGTrkngLftmEngnPwrTkOffRnTm "GHG Tracking Lifetime Engine Power Take Off Run Time: Accumulated engine runtime under power take off [PTO] governor control over the lifetime of the vehicle for GHG Tracking.  ";
CM_ SG_ 2566585598 GHGTLtEPwTOFCspt "GHG Tracking Lifetime Engine Power Take Off Fuel Consumption: Accumulated fuel consumption under power take off [PTO] governor control over the lifetime of the vehicle for GHG Tracking.  ";
CM_ SG_ 2566585598 GHGTLtAttEStdwTAtvtCt "GHG Tracking Lifetime Automatic Engine Shutdown Technology Activation Count: Accumulated activation counts of the automatic engine [idle] shutdown (AES) system over the lifetime of the vehicle for GHG Tracking.  ";
CM_ SG_ 2566585598 GHGTrkngLftmStpStrtThnlgRnTm "GHG Tracking Lifetime Stop-Start Technology Run Time: Accumulated time where the stop start system is commanding the engine off over the lifetime of the vehicle for GHG Tracking.  ";
CM_ BO_ 2566585854 "GHG Tracking Stored 100 Hour Array Data";
CM_ SG_ 2566585854 GHGTrkngStrd100HrEngnRnTm "GHG Tracking Stored 100 Hour Engine Run Time: Accumulated engine run time over the prior 100 hour period for GHG Tracking.  ";
CM_ SG_ 2566585854 GHGTrkngStrd100HrVhlDstn "GHG Tracking Stored 100 Hour Vehicle Distance: Accumulated vehicle distance over the prior 100 hour period for GHG Tracking.  ";
CM_ SG_ 2566585854 GHGTrkngStrd100HrVhlFlCnsmptn "GHG Tracking Stored 100 Hour Vehicle Fuel Consumption: Accumulated vehicle fuel consumption over the prior 100 hour period for GHG Tracking.  ";
CM_ SG_ 2566585854 GHGTrkngStrd100HrEngnFlCnsmptn "GHG Tracking Stored 100 Hour Engine Fuel Consumption: Accumulated engine fuel consumption over the prior 100 hour period for GHG Tracking.  ";
CM_ SG_ 2566585854 GHGTrkngStrd100HrEngnOtptEnrg "GHG Tracking Stored 100 Hour Engine Output Energy: Accumulated engine output energy over the prior 100 hour period for GHG Tracking.  ";
CM_ SG_ 2566585854 GHGTStd100HPstvKtENt "GHG Tracking Stored 100 Hour Positive Kinetic Energy Numerator: Accumulated positive kinetic energy numerator (as delta-V-squared) over the prior 100 hour period for GHG Tracking.  The PKE denominator is GHG Tracking Stored 100 Hour Vehicle Distance....";
CM_ SG_ 2566585854 GHGTrkngStrd100HrUrnSpdRnTm "GHG Tracking Stored 100 Hour Urban Speed Run Time: Accumulated time at urban vehicle speeds (1.6 km/h < v <= 60 km/h) over the prior 100 hour period for GHG Tracking.";
CM_ SG_ 2566585854 GHGTrkngStrd100HrIdlRnTm "GHG Tracking Stored 100 Hour Idle Run Time: Accumulated engine run time under idle conditions (v <= 1.6 km/h) over the prior 100 hour period for GHG Tracking.";
CM_ SG_ 2566585854 GHGTStd100HEIdFCspt "GHG Tracking Stored 100 Hour Engine Idle Fuel Consumption: Accumulated fuel consumption under idle conditions (v <= 1.6 km/h) over the prior 100 hour period for GHG Tracking.";
CM_ SG_ 2566585854 GHGTStd100HEPwTORT "GHG Tracking Stored 100 Hour Engine Power Take Off Run Time: Accumulated engine runtime under power take off [PTO] governor control over the prior 100 hour period for GHG Tracking.  ";
CM_ SG_ 2566585854 GHGTStd100HEPwTOFCspt "GHG Tracking Stored 100 Hour Engine Power Take Off Fuel Consumption: Accumulated fuel consumption under power take off [PTO] governor control over the prior 100 hour period for GHG Tracking.  ";
CM_ SG_ 2566585854 GHGTStd100HAttEStdwTAtvtCt "GHG Tracking Stored 100 Hour Automatic Engine Shutdown Technology Activation Count: Accumulated activation counts of the automatic engine [idle] shutdown (AES) system over the prior 100 hour period for GHG Tracking.  ";
CM_ SG_ 2566585854 GHGTStd100HStpSttTRT "GHG Tracking Stored 100 Hour Stop-Start Technology Run Time: Accumulated time where the stop start system is commanding the engine off over the prior 100 hour period for GHG Tracking.  ";
CM_ BO_ 2566586110 "GHG Tracking Active 100 Hour Array Data";
CM_ SG_ 2566586110 GHGTrkngAtv100HrEngnRnTm "GHG Tracking Active 100 Hour Engine Run Time: Accumulated engine run time over the current 100 hour period for GHG Tracking.  ";
CM_ SG_ 2566586110 GHGTrkngAtv100HrVhlDstn "GHG Tracking Active 100 Hour Vehicle Distance: Accumulated vehicle distance over the current 100 hour period for GHG Tracking.  ";
CM_ SG_ 2566586110 GHGTrkngAtv100HrVhlFlCnsmptn "GHG Tracking Active 100 Hour Vehicle Fuel Consumption: Accumulated vehicle fuel consumption over the current 100 hour period for GHG Tracking.  ";
CM_ SG_ 2566586110 GHGTrkngAtv100HrEngnFlCnsmptn "GHG Tracking Active 100 Hour Engine Fuel Consumption: Accumulated engine fuel consumption over the current 100 hour period for GHG Tracking.  ";
CM_ SG_ 2566586110 GHGTrkngAtv100HrEngnOtptEnrg "GHG Tracking Active 100 Hour Engine Output Energy: Accumulated engine output energy over the current 100 hour period for GHG Tracking.  ";
CM_ SG_ 2566586110 GHGTAtv100HPstvKtENt "GHG Tracking Active 100 Hour Positive Kinetic Energy Numerator: Accumulated positive kinetic energy numerator (as delta-V-squared) over the current 100 hour period for GHG Tracking.  The PKE denominator is GHG Tracking Active 100 Hour Vehicle Distanc...";
CM_ SG_ 2566586110 GHGTrkngAtv100HrUrnSpdRnTm "GHG Tracking Active 100 Hour Urban Speed Run Time: Accumulated time at urban vehicle speeds (1.6 km/h < v <= 60 km/h) over the current 100 hour period for GHG Tracking.";
CM_ SG_ 2566586110 GHGTrkngAtv100HrIdlRnTm "GHG Tracking Active 100 Hour Idle Run Time: Accumulated engine run time under idle conditions (v <= 1.6 km/h) over the current 100 hour period for GHG Tracking.";
CM_ SG_ 2566586110 GHGTAtv100HEIdFCspt "GHG Tracking Active 100 Hour Engine Idle Fuel Consumption: Accumulated fuel consumption under idle conditions (v <= 1.6 km/h) over the current 100 hour period for GHG Tracking.";
CM_ SG_ 2566586110 GHGTAtv100HEPwTORT "GHG Tracking Active 100 Hour Engine Power Take Off Run Time: Accumulated engine runtime under power take off [PTO] governor control over the current 100 hour period for GHG Tracking.  ";
CM_ SG_ 2566586110 GHGTAtv100HEPwTOFCspt "GHG Tracking Active 100 Hour Engine Power Take Off Fuel Consumption: Accumulated fuel consumption under power take off [PTO] governor control over the current 100 hour period for GHG Tracking.  ";
CM_ SG_ 2566586110 GHGTAtv100HAttEStdwTAtvtCt "GHG Tracking Active 100 Hour Automatic Engine Shutdown Technology Activation Count: Accumulated activation counts of the automatic engine [idle] shutdown (AES) system over the current 100 hour period for GHG Tracking.  ";
CM_ SG_ 2566586110 GHGTAtv100HStpSttTRT "GHG Tracking Active 100 Hour Stop-Start Technology Run Time: Accumulated time where the stop start system is commanding the engine off over the current 100 hour period for GHG Tracking.  ";
CM_ BO_ 2566587134 "NOx Tracking Engine Activity Lifetime Fuel Consumption Bins ";
CM_ SG_ 2566587134 NOxTEAtvtLtFCsptB1Tt "NOx Tracking Engine Activity Lifetime Fuel Consumption Bin 1 (Total): Accumulated Fuel consumption regardless of NOx sensor status over the lifetime of the vehicle for Bin 1 [Note Bin 1 is the total of Bins 2-14]";
CM_ SG_ 2566587134 NOxTEAtvtLtFCsptB2 "NOx Tracking Engine Activity Lifetime Fuel Consumption Bin 2 : Accumulated Fuel consumption regardless of NOx sensor status over the lifetime of the vehicle for Bin 2 [Note Bin 2 is the 'idle' bin]";
CM_ SG_ 2566587134 NOxTEAtvtLtFCsptB3 "NOx Tracking Engine Activity Lifetime Fuel Consumption Bin 3 : Accumulated Fuel consumption regardless of NOx sensor status over the lifetime of the vehicle for Bin 3. ";
CM_ SG_ 2566587134 NOxTEAtvtLtFCsptB4 "NOx Tracking Engine Activity Lifetime Fuel Consumption Bin 4: Accumulated Fuel consumption regardless of NOx sensor status over the lifetime of the vehicle for Bin 4. ";
CM_ SG_ 2566587134 NOxTEAtvtLtFCsptB5 "NOx Tracking Engine Activity Lifetime Fuel Consumption Bin 5: Accumulated Fuel consumption regardless of NOx sensor status over the lifetime of the vehicle for Bin 5.";
CM_ SG_ 2566587134 NOxTEAtvtLtFCsptB6 "NOx Tracking Engine Activity Lifetime Fuel Consumption Bin 6: Accumulated Fuel consumption regardless of NOx sensor status over the lifetime of the vehicle for Bin 6. ";
CM_ SG_ 2566587134 NOxTEAtvtLtFCsptB7 "NOx Tracking Engine Activity Lifetime Fuel Consumption Bin 7: Accumulated Fuel consumption regardless of NOx sensor status over the lifetime of the vehicle for Bin 7. ";
CM_ SG_ 2566587134 NOxTEAtvtLtFCsptB8 "NOx Tracking Engine Activity Lifetime Fuel Consumption Bin 8: Accumulated Fuel consumption regardless of NOx sensor status over the lifetime of the vehicle for Bin 8. ";
CM_ SG_ 2566587134 NOxTEAtvtLtFCsptB9 "NOx Tracking Engine Activity Lifetime Fuel Consumption Bin 9: Accumulated Fuel consumption regardless of NOx sensor status over the lifetime of the vehicle for Bin 9";
CM_ SG_ 2566587134 NOxTEAtvtLtFCsptB10 "NOx Tracking Engine Activity Lifetime Fuel Consumption Bin 10: Accumulated Fuel consumption regardless of NOx sensor status over the lifetime of the vehicle for Bin 10";
CM_ SG_ 2566587134 NOxTEAtvtLtFCsptB11 "NOx Tracking Engine Activity Lifetime Fuel Consumption Bin 11: Accumulated Fuel consumption regardless of NOx sensor status over the lifetime of the vehicle for Bin 11";
CM_ SG_ 2566587134 NOxTEAtvtLtFCsptB12 "NOx Tracking Engine Activity Lifetime Fuel Consumption Bin 12: Accumulated Fuel consumption regardless of NOx sensor status over the lifetime of the vehicle for Bin 12";
CM_ SG_ 2566587134 NOxTEAtvtLtFCsptB13 "NOx Tracking Engine Activity Lifetime Fuel Consumption Bin 13: Accumulated Fuel consumption regardless of NOx sensor status over the lifetime of the vehicle for Bin 13";
CM_ SG_ 2566587134 NOxTEAtvtLtFCsptB14 "NOx Tracking Engine Activity Lifetime Fuel Consumption Bin 14 : Accumulated Fuel consumption regardless of NOx sensor status over the lifetime of the vehicle for Bin 14";
CM_ SG_ 2566587134 NOxTEAtvtLtFCsptB15NTEBIN "NOx Tracking Engine Activity Lifetime Fuel Consumption Bin 15 (NTE BIN): Accumulated Fuel consumption regardless of NOx sensor status over the lifetime of the vehicle for Bin 15 [Note Bin 15 is the NTE Bin]";
CM_ SG_ 2566587134 NOxTEAtvtLtFCsptB16RB "NOx Tracking Engine Activity Lifetime Fuel Consumption Bin 16 (Regen Bin) : Accumulated Fuel consumption regardless of NOx sensor status over the lifetime of the vehicle for Bin 16 [Note Bin 16 is the Regen Bin]";
CM_ SG_ 2566587134 NOxTEAtvtLtFCsptB17MILOB "NOx Tracking Engine Activity Lifetime Fuel Consumption Bin 17 (MIL On Bin): Accumulated Fuel consumption regardless of NOx sensor status over the lifetime of the vehicle for Bin 17 [Note Bin 17 is the MIL On  bin].";
CM_ BO_ 2566587390 "NOx Tracking Engine Activity Lifetime Engine Run Time Bins ";
CM_ SG_ 2566587390 NOxTEAtvtLtERTB1Tt "NOx Tracking Engine Activity Lifetime Engine Run Time Bin 1 (Total): Accumulated Engine run time regardless of NOx sensor status over the lifetime of the vehicle for Bin 1 [Note Bin 1 is the total of Bins 2-14]";
CM_ SG_ 2566587390 NOxTrkngEngnAtvtLftmEngnRnTmBn2 "NOx Tracking Engine Activity Lifetime Engine Run Time Bin 2 : Accumulated Engine run time regardless of NOx sensor status over the lifetime of the vehicle for Bin 2 [Note Bin 2 is the 'idle' bin]";
CM_ SG_ 2566587390 NOxTrkngEngnAtvtLftmEngnRnTmBn3 "NOx Tracking Engine Activity Lifetime Engine Run Time Bin 3 : Accumulated Engine run time regardless of NOx sensor status over the lifetime of the vehicle for Bin 3. ";
CM_ SG_ 2566587390 NOxTrkngEngnAtvtLftmEngnRnTmBn4 "NOx Tracking Engine Activity Lifetime Engine Run Time Bin 4: Accumulated Engine run time regardless of NOx sensor status over the lifetime of the vehicle for Bin 4.";
CM_ SG_ 2566587390 NOxTrkngEngnAtvtLftmEngnRnTmBn5 "NOx Tracking Engine Activity Lifetime Engine Run Time Bin 5: Accumulated Engine run time regardless of NOx sensor status over the lifetime of the vehicle for Bin 5.";
CM_ SG_ 2566587390 NOxTrkngEngnAtvtLftmEngnRnTmBn6 "NOx Tracking Engine Activity Lifetime Engine Run Time Bin 6: Accumulated Engine run time regardless of NOx sensor status over the lifetime of the vehicle for Bin 6. ";
CM_ SG_ 2566587390 NOxTrkngEngnAtvtLftmEngnRnTmBn7 "NOx Tracking Engine Activity Lifetime Engine Run Time Bin 7: Accumulated Engine run time regardless of NOx sensor status over the lifetime of the vehicle for Bin 7. ";
CM_ SG_ 2566587390 NOxTrkngEngnAtvtLftmEngnRnTmBn8 "NOx Tracking Engine Activity Lifetime Engine Run Time Bin 8: Accumulated Engine run time regardless of NOx sensor status over the lifetime of the vehicle for Bin 8. ";
CM_ SG_ 2566587390 NOxTrkngEngnAtvtLftmEngnRnTmBn9 "NOx Tracking Engine Activity Lifetime Engine Run Time Bin 9: Accumulated Engine run time regardless of NOx sensor status over the lifetime of the vehicle for Bin 9";
CM_ SG_ 2566587390 NOxTEAtvtLtERTB10 "NOx Tracking Engine Activity Lifetime Engine Run Time Bin 10: Accumulated Engine run time regardless of NOx sensor status over the lifetime of the vehicle for Bin 10";
CM_ SG_ 2566587390 NOxTEAtvtLtERTB11 "NOx Tracking Engine Activity Lifetime Engine Run Time Bin 11: Accumulated Engine run time regardless of NOx sensor status over the lifetime of the vehicle for Bin 11";
CM_ SG_ 2566587390 NOxTEAtvtLtERTB12 "NOx Tracking Engine Activity Lifetime Engine Run Time Bin 12: Accumulated Engine run time regardless of NOx sensor status over the lifetime of the vehicle for Bin 12";
CM_ SG_ 2566587390 NOxTEAtvtLtERTB13 "NOx Tracking Engine Activity Lifetime Engine Run Time Bin 13: Accumulated Engine run time regardless of NOx sensor status over the lifetime of the vehicle for Bin 13";
CM_ SG_ 2566587390 NOxTEAtvtLtERTB14 "NOx Tracking Engine Activity Lifetime Engine Run Time Bin 14 : Accumulated Engine run time regardless of NOx sensor status over the lifetime of the vehicle for Bin 14";
CM_ SG_ 2566587390 NOxTEAtvtLtERTB15NTEBIN "NOx Tracking Engine Activity Lifetime Engine Run Time Bin 15 (NTE BIN): Accumulated Engine run time regardless of NOx sensor status over the lifetime of the vehicle for Bin 15 [Note Bin 15 is the NTE Bin]";
CM_ SG_ 2566587390 NOxTEAtvtLtERTB16RB "NOx Tracking Engine Activity Lifetime Engine Run Time Bin 16 (Regen Bin) : Accumulated Engine run time regardless of NOx sensor status over the lifetime of the vehicle for Bin 16 [Note Bin 16 is the Regen Bin]";
CM_ SG_ 2566587390 NOxTEAtvtLtERTB17MILOB "NOx Tracking Engine Activity Lifetime Engine Run Time Bin 17 (MIL On Bin): Accumulated Engine run time regardless of NOx sensor status over the lifetime of the vehicle for Bin 17 [Note Bin 17 is the MIL On Bin].";
CM_ BO_ 2566587646 "NOx Tracking Engine Activity Lifetime Vehicle Distance Bins ";
CM_ SG_ 2566587646 NOxTEAtvtLtVDstB1Tt "NOx Tracking Engine Activity Lifetime Vehicle Distance Bin 1 (Total): Accumulated Vehicle distance regardless of NOx sensor status over the lifetime of the vehicle for Bin 1 [Note Bin 1 is the total of Bins 2-14]";
CM_ SG_ 2566587646 NOxTrkngEngnAtvtLftmVhlDstnBn2 "NOx Tracking Engine Activity Lifetime Vehicle Distance Bin 2 : Accumulated Vehicle distance regardless of NOx sensor status over the lifetime of the vehicle for Bin 2 [Note Bin 2 is the 'idle' bin]";
CM_ SG_ 2566587646 NOxTrkngEngnAtvtLftmVhlDstnBn3 "NOx Tracking Engine Activity Lifetime Vehicle Distance Bin 3 : Accumulated Vehicle distance regardless of NOx sensor status over the lifetime of the vehicle for Bin 3.";
CM_ SG_ 2566587646 NOxTrkngEngnAtvtLftmVhlDstnBn4 "NOx Tracking Engine Activity Lifetime Vehicle Distance Bin 4: Accumulated Vehicle distance regardless of NOx sensor status over the lifetime of the vehicle for Bin 4.";
CM_ SG_ 2566587646 NOxTrkngEngnAtvtLftmVhlDstnBn5 "NOx Tracking Engine Activity Lifetime Vehicle Distance Bin 5: Accumulated Vehicle distance regardless of NOx sensor status over the lifetime of the vehicle for Bin 5.";
CM_ SG_ 2566587646 NOxTrkngEngnAtvtLftmVhlDstnBn6 "NOx Tracking Engine Activity Lifetime Vehicle Distance Bin 6: Accumulated Vehicle distance regardless of NOx sensor status over the lifetime of the vehicle for Bin 6. ";
CM_ SG_ 2566587646 NOxTrkngEngnAtvtLftmVhlDstnBn7 "NOx Tracking Engine Activity Lifetime Vehicle Distance Bin 7: Accumulated Vehicle distance regardless of NOx sensor status over the lifetime of the vehicle for Bin 7. ";
CM_ SG_ 2566587646 NOxTrkngEngnAtvtLftmVhlDstnBn8 "NOx Tracking Engine Activity Lifetime Vehicle Distance Bin 8: Accumulated Vehicle distance regardless of NOx sensor status over the lifetime of the vehicle for Bin 8. ";
CM_ SG_ 2566587646 NOxTrkngEngnAtvtLftmVhlDstnBn9 "NOx Tracking Engine Activity Lifetime Vehicle Distance Bin 9: Accumulated Vehicle distance regardless of NOx sensor status over the lifetime of the vehicle for Bin 9";
CM_ SG_ 2566587646 NOxTrkngEngnAtvtLftmVhlDstnBn10 "NOx Tracking Engine Activity Lifetime Vehicle Distance Bin 10: Accumulated Vehicle distance regardless of NOx sensor status over the lifetime of the vehicle for Bin 10";
CM_ SG_ 2566587646 NOxTrkngEngnAtvtLftmVhlDstnBn11 "NOx Tracking Engine Activity Lifetime Vehicle Distance Bin 11: Accumulated Vehicle distance regardless of NOx sensor status over the lifetime of the vehicle for Bin 11";
CM_ SG_ 2566587646 NOxTrkngEngnAtvtLftmVhlDstnBn12 "NOx Tracking Engine Activity Lifetime Vehicle Distance Bin 12: Accumulated Vehicle distance regardless of NOx sensor status over the lifetime of the vehicle for Bin 12";
CM_ SG_ 2566587646 NOxTrkngEngnAtvtLftmVhlDstnBn13 "NOx Tracking Engine Activity Lifetime Vehicle Distance Bin 13: Accumulated Vehicle distance regardless of NOx sensor status over the lifetime of the vehicle for Bin 13";
CM_ SG_ 2566587646 NOxTrkngEngnAtvtLftmVhlDstnBn14 "NOx Tracking Engine Activity Lifetime Vehicle Distance Bin 14 : Accumulated Vehicle distance regardless of NOx sensor status over the lifetime of the vehicle for Bin 14";
CM_ SG_ 2566587646 NOxTEAtvtLtVDstB15NTEBIN "NOx Tracking Engine Activity Lifetime Vehicle Distance Bin 15 (NTE BIN): Accumulated Vehicle distance regardless of NOx sensor status over the lifetime of the vehicle for Bin 15 [Note Bin 15 is the NTE Bin]";
CM_ SG_ 2566587646 NOxTEAtvtLtVDstB16RB "NOx Tracking Engine Activity Lifetime Vehicle Distance Bin 16 (Regen Bin) : Accumulated Vehicle distance regardless of NOx sensor status over the lifetime of the vehicle for Bin 16 [Note Bin 16 is the Regen Bin]";
CM_ SG_ 2566587646 NOxTEAtvtLtVDstB17MILOB "NOx Tracking Engine Activity Lifetime Vehicle Distance Bin 17 (MIL On Bin): Accumulated Vehicle distance regardless of NOx sensor status over the lifetime of the vehicle for Bin 17 [Note Bin 17 is the MIL On Bin].";
CM_ BO_ 2566587902 "NOx Tracking Engine Activity Lifetime Engine Output Energy Bins ";
CM_ SG_ 2566587902 NOxTEAtvtLtEOtptEB1Tt "NOx Tracking Engine Activity Lifetime Engine Output Energy Bin 1 (Total) : Accumulated Engine output energy regardless of NOx sensor status over the lifetime of the vehicle for Bin 1 [Note Bin 1 is the total of bins 2-14]";
CM_ SG_ 2566587902 NOxTEAtvtLtEOtptEB2 "NOx Tracking Engine Activity Lifetime Engine Output Energy Bin 2 : Accumulated Engine output energy regardless of NOx sensor status over the lifetime of the vehicle for Bin 2 [Note Bin 2 is the 'idle' bin]";
CM_ SG_ 2566587902 NOxTEAtvtLtEOtptEB3 "NOx Tracking Engine Activity Lifetime Engine Output Energy Bin 3 : Accumulated Engine output energy regardless of NOx sensor status over the lifetime of the vehicle for Bin 3.";
CM_ SG_ 2566587902 NOxTEAtvtLtEOtptEB4 "NOx Tracking Engine Activity Lifetime Engine Output Energy Bin 4: Accumulated Engine output energy regardless of NOx sensor status over the lifetime of the vehicle for Bin 4. ";
CM_ SG_ 2566587902 NOxTEAtvtLtEOtptEB5 "NOx Tracking Engine Activity Lifetime Engine Output Energy Bin 5: Accumulated Engine output energy regardless of NOx sensor status over the lifetime of the vehicle for Bin 5.";
CM_ SG_ 2566587902 NOxTEAtvtLtEOtptEB6 "NOx Tracking Engine Activity Lifetime Engine Output Energy Bin 6: Accumulated Engine output energy regardless of NOx sensor status over the lifetime of the vehicle for Bin 6. ";
CM_ SG_ 2566587902 NOxTEAtvtLtEOtptEB7 "NOx Tracking Engine Activity Lifetime Engine Output Energy Bin 7: Accumulated Engine output energy regardless of NOx sensor status over the lifetime of the vehicle for Bin 7. ";
CM_ SG_ 2566587902 NOxTEAtvtLtEOtptEB8 "NOx Tracking Engine Activity Lifetime Engine Output Energy Bin 8: Accumulated Engine output energy regardless of NOx sensor status over the lifetime of the vehicle for Bin 8. ";
CM_ SG_ 2566587902 NOxTEAtvtLtEOtptEB9 "NOx Tracking Engine Activity Lifetime Engine Output Energy Bin 9: Accumulated Engine output energy regardless of NOx sensor status over the lifetime of the vehicle for Bin 9";
CM_ SG_ 2566587902 NOxTEAtvtLtEOtptEB10 "NOx Tracking Engine Activity Lifetime Engine Output Energy Bin 10: Accumulated Engine output energy regardless of NOx sensor status over the lifetime of the vehicle for Bin 10";
CM_ SG_ 2566587902 NOxTEAtvtLtEOtptEB11 "NOx Tracking Engine Activity Lifetime Engine Output Energy Bin 11: Accumulated Engine output energy regardless of NOx sensor status over the lifetime of the vehicle for Bin 11";
CM_ SG_ 2566587902 NOxTEAtvtLtEOtptEB12 "NOx Tracking Engine Activity Lifetime Engine Output Energy Bin 12: Accumulated Engine output energy regardless of NOx sensor status over the lifetime of the vehicle for Bin 12";
CM_ SG_ 2566587902 NOxTEAtvtLtEOtptEB13 "NOx Tracking Engine Activity Lifetime Engine Output Energy Bin 13: Accumulated Engine output energy regardless of NOx sensor status over the lifetime of the vehicle for Bin 13";
CM_ SG_ 2566587902 NOxTEAtvtLtEOtptEB14 "NOx Tracking Engine Activity Lifetime Engine Output Energy Bin 14 : Accumulated Engine output energy regardless of NOx sensor status over the lifetime of the vehicle for Bin 14";
CM_ SG_ 2566587902 NOxTEAtvtLtEOtptEB15NTEBIN "NOx Tracking Engine Activity Lifetime Engine Output Energy Bin 15 (NTE BIN): Accumulated Engine output energy regardless of NOx sensor status over the lifetime of the vehicle for Bin 15 [Note Bin 15 is the NTE Bin]";
CM_ SG_ 2566587902 NOxTEAtvtLtEOtptEB16RB "NOx Tracking Engine Activity Lifetime Engine Output Energy Bin 16 (Regen Bin) : Accumulated Engine output energy regardless of NOx sensor status over the lifetime of the vehicle for Bin 16 [Note Bin 16 is the Regen Bin]";
CM_ SG_ 2566587902 NOxTEAtvtLtEOtptEB17MILOB "NOx Tracking Engine Activity Lifetime Engine Output Energy Bin 17 (MIL On Bin): Accumulated Engine output energy regardless of NOx sensor status over the lifetime of the vehicle for Bin 17 [Note Bin 17 is the MIL On Bin].";
CM_ BO_ 2566588158 "NOx Tracking Valid NOx Lifetime Fuel Consumption Bins ";
CM_ SG_ 2566588158 NOxTVdNOxLtFCsptB1Tt "NOx Tracking Valid NOx Lifetime Fuel Consumption Bin 1 (Total): Accumulated Fuel consumption while all NOx sensors are active over the lifetime of the vehicle for Bin 1 [Note Bin 1 is the total of Bins 2-14]";
CM_ SG_ 2566588158 NOxTrkngVldNOxLftmFlCnsmptnBn2 "NOx Tracking Valid NOx Lifetime Fuel Consumption Bin 2 : Accumulated Fuel consumption while all NOx sensors are active over the lifetime of the vehicle for Bin 2 [Note Bin 2 is the 'idle' bin]";
CM_ SG_ 2566588158 NOxTrkngVldNOxLftmFlCnsmptnBn3 "NOx Tracking Valid NOx Lifetime Fuel Consumption Bin 3 : Accumulated Fuel consumption while all NOx sensors are active over the lifetime of the vehicle for Bin 3. ";
CM_ SG_ 2566588158 NOxTrkngVldNOxLftmFlCnsmptnBn4 "NOx Tracking Valid NOx Lifetime Fuel Consumption Bin 4: Accumulated Fuel consumption while all NOx sensors are active over the lifetime of the vehicle for Bin 4. ";
CM_ SG_ 2566588158 NOxTrkngVldNOxLftmFlCnsmptnBn5 "NOx Tracking Valid NOx Lifetime Fuel Consumption Bin 5: Accumulated Fuel consumption while all NOx sensors are active over the lifetime of the vehicle for Bin 5.";
CM_ SG_ 2566588158 NOxTrkngVldNOxLftmFlCnsmptnBn6 "NOx Tracking Valid NOx Lifetime Fuel Consumption Bin 6: Accumulated Fuel consumption while all NOx sensors are active over the lifetime of the vehicle for Bin 6. ";
CM_ SG_ 2566588158 NOxTrkngVldNOxLftmFlCnsmptnBn7 "NOx Tracking Valid NOx Lifetime Fuel Consumption Bin 7: Accumulated Fuel consumption while all NOx sensors are active over the lifetime of the vehicle for Bin 7. ";
CM_ SG_ 2566588158 NOxTrkngVldNOxLftmFlCnsmptnBn8 "NOx Tracking Valid NOx Lifetime Fuel Consumption Bin 8: Accumulated Fuel consumption while all NOx sensors are active over the lifetime of the vehicle for Bin 8. ";
CM_ SG_ 2566588158 NOxTrkngVldNOxLftmFlCnsmptnBn9 "NOx Tracking Valid NOx Lifetime Fuel Consumption Bin 9: Accumulated Fuel consumption while all NOx sensors are active over the lifetime of the vehicle for Bin 9";
CM_ SG_ 2566588158 NOxTrkngVldNOxLftmFlCnsmptnBn10 "NOx Tracking Valid NOx Lifetime Fuel Consumption Bin 10: Accumulated Fuel consumption while all NOx sensors are active over the lifetime of the vehicle for Bin 10";
CM_ SG_ 2566588158 NOxTrkngVldNOxLftmFlCnsmptnBn11 "NOx Tracking Valid NOx Lifetime Fuel Consumption Bin 11: Accumulated Fuel consumption while all NOx sensors are active over the lifetime of the vehicle for Bin 11";
CM_ SG_ 2566588158 NOxTrkngVldNOxLftmFlCnsmptnBn12 "NOx Tracking Valid NOx Lifetime Fuel Consumption Bin 12: Accumulated Fuel consumption while all NOx sensors are active over the lifetime of the vehicle for Bin 12";
CM_ SG_ 2566588158 NOxTrkngVldNOxLftmFlCnsmptnBn13 "NOx Tracking Valid NOx Lifetime Fuel Consumption Bin 13: Accumulated Fuel consumption while all NOx sensors are active over the lifetime of the vehicle for Bin 13";
CM_ SG_ 2566588158 NOxTrkngVldNOxLftmFlCnsmptnBn14 "NOx Tracking Valid NOx Lifetime Fuel Consumption Bin 14 : Accumulated Fuel consumption while all NOx sensors are active over the lifetime of the vehicle for Bin 14";
CM_ SG_ 2566588158 NOxTVdNOxLtFCsptB15NTEBIN "NOx Tracking Valid NOx Lifetime Fuel Consumption Bin 15 (NTE BIN) : Accumulated Fuel consumption while all NOx sensors are active over the lifetime of the vehicle for Bin 15 [Note Bin 15 is the NTE Bin]";
CM_ SG_ 2566588158 NOxTVdNOxLtFCsptB16RB "NOx Tracking Valid NOx Lifetime Fuel Consumption Bin 16 (Regen Bin) : Accumulated Fuel consumption while all NOx sensors are active over the lifetime of the vehicle for Bin 16 [Note Bin 16 is the Regen Bin]";
CM_ SG_ 2566588158 NOxTVdNOxLtFCsptB17MILOB "NOx Tracking Valid NOx Lifetime Fuel Consumption Bin 17 (MIL On Bin) : Accumulated Fuel consumption while all NOx sensors are active over the lifetime of the vehicle for Bin 17 [Note Bin 17 is the MIL On Bin]";
CM_ BO_ 2566588414 "NOx Tracking Valid NOx Lifetime Engine Run Time Bins ";
CM_ SG_ 2566588414 NOxTVdNOxLtERTB1Tt "NOx Tracking Valid NOx Lifetime Engine Run Time Bin 1 (Total): Accumulated Engine run time while all NOx sensors are active over the lifetime of the vehicle for Bin 1 [Note Bin 1 is the total of Bins 2-14]";
CM_ SG_ 2566588414 NOxTrkngVldNOxLftmEngnRnTmBn2 "NOx Tracking Valid NOx Lifetime Engine Run Time Bin 2 : Accumulated Engine run time while all NOx sensors are active over the lifetime of the vehicle for Bin 2 [Note Bin 2 is the 'idle' bin]";
CM_ SG_ 2566588414 NOxTrkngVldNOxLftmEngnRnTmBn3 "NOx Tracking Valid NOx Lifetime Engine Run Time Bin 3 : Accumulated Engine run time while all NOx sensors are active over the lifetime of the vehicle for Bin 3. ";
CM_ SG_ 2566588414 NOxTrkngVldNOxLftmEngnRnTmBn4 "NOx Tracking Valid NOx Lifetime Engine Run Time Bin 4: Accumulated Engine run time while all NOx sensors are active over the lifetime of the vehicle for Bin 4.";
CM_ SG_ 2566588414 NOxTrkngVldNOxLftmEngnRnTmBn5 "NOx Tracking Valid NOx Lifetime Engine Run Time Bin 5: Accumulated Engine run time while all NOx sensors are active over the lifetime of the vehicle for Bin 5.";
CM_ SG_ 2566588414 NOxTrkngVldNOxLftmEngnRnTmBn6 "NOx Tracking Valid NOx Lifetime Engine Run Time Bin 6: Accumulated Engine run time while all NOx sensors are active over the lifetime of the vehicle for Bin 6. ";
CM_ SG_ 2566588414 NOxTrkngVldNOxLftmEngnRnTmBn7 "NOx Tracking Valid NOx Lifetime Engine Run Time Bin 7: Accumulated Engine run time while all NOx sensors are active over the lifetime of the vehicle for Bin 7. ";
CM_ SG_ 2566588414 NOxTrkngVldNOxLftmEngnRnTmBn8 "NOx Tracking Valid NOx Lifetime Engine Run Time Bin 8: Accumulated Engine run time while all NOx sensors are active over the lifetime of the vehicle for Bin 8. ";
CM_ SG_ 2566588414 NOxTrkngVldNOxLftmEngnRnTmBn9 "NOx Tracking Valid NOx Lifetime Engine Run Time Bin 9: Accumulated Engine run time while all NOx sensors are active over the lifetime of the vehicle for Bin 9";
CM_ SG_ 2566588414 NOxTrkngVldNOxLftmEngnRnTmBn10 "NOx Tracking Valid NOx Lifetime Engine Run Time Bin 10: Accumulated Engine run time while all NOx sensors are active over the lifetime of the vehicle for Bin 10";
CM_ SG_ 2566588414 NOxTrkngVldNOxLftmEngnRnTmBn11 "NOx Tracking Valid NOx Lifetime Engine Run Time Bin 11: Accumulated Engine run time while all NOx sensors are active over the lifetime of the vehicle for Bin 11";
CM_ SG_ 2566588414 NOxTrkngVldNOxLftmEngnRnTmBn12 "NOx Tracking Valid NOx Lifetime Engine Run Time Bin 12: Accumulated Engine run time while all NOx sensors are active over the lifetime of the vehicle for Bin 12";
CM_ SG_ 2566588414 NOxTrkngVldNOxLftmEngnRnTmBn13 "NOx Tracking Valid NOx Lifetime Engine Run Time Bin 13: Accumulated Engine run time while all NOx sensors are active over the lifetime of the vehicle for Bin 13";
CM_ SG_ 2566588414 NOxTrkngVldNOxLftmEngnRnTmBn14 "NOx Tracking Valid NOx Lifetime Engine Run Time Bin 14 : Accumulated Engine run time while all NOx sensors are active over the lifetime of the vehicle for Bin 14";
CM_ SG_ 2566588414 NOxTVdNOxLtERTB15NTEBIN "NOx Tracking Valid NOx Lifetime Engine Run Time Bin 15 (NTE BIN) : Accumulated Engine run time while all NOx sensors are active over the lifetime of the vehicle for Bin 15 [Note Bin 15 is the NTE Bin]";
CM_ SG_ 2566588414 NOxTVdNOxLtERTB16RB "NOx Tracking Valid NOx Lifetime Engine Run Time Bin 16 (Regen Bin) : Accumulated Engine run time while all NOx sensors are active over the lifetime of the vehicle for Bin 16 [Note Bin 16 is the Regen Bin]";
CM_ SG_ 2566588414 NOxTVdNOxLtERTB17MILOB "NOx Tracking Valid NOx Lifetime Engine Run Time Bin 17 (MIL On Bin) : Accumulated Engine run time while all NOx sensors are active over the lifetime of the vehicle for Bin 17 [Note Bin 17 is the MIL On Bin]";
CM_ BO_ 2566588670 "NOx Tracking Valid NOx Lifetime Vehicle Distance Bins ";
CM_ SG_ 2566588670 NOxTrkngVldNOxLftmVhlDstnBn1Ttl "NOx Tracking Valid NOx Lifetime Vehicle Distance Bin 1 (Total): Accumulated Vehicle distance while all NOx sensors are active over the lifetime of the vehicle for Bin 1 [Note Bin 1 is the total of Bins 2-14]";
CM_ SG_ 2566588670 NOxTrkngVldNOxLftmVhlDstnBn2 "NOx Tracking Valid NOx Lifetime Vehicle Distance Bin 2 : Accumulated Vehicle distance while all NOx sensors are active over the lifetime of the vehicle for Bin 2 [Note Bin 2 is the 'idle' bin]";
CM_ SG_ 2566588670 NOxTrkngVldNOxLftmVhlDstnBn3 "NOx Tracking Valid NOx Lifetime Vehicle Distance Bin 3 : Accumulated Vehicle distance while all NOx sensors are active over the lifetime of the vehicle for Bin 3. ";
CM_ SG_ 2566588670 NOxTrkngVldNOxLftmVhlDstnBn4 "NOx Tracking Valid NOx Lifetime Vehicle Distance Bin 4: Accumulated Vehicle distance while all NOx sensors are active over the lifetime of the vehicle for Bin 4.";
CM_ SG_ 2566588670 NOxTrkngVldNOxLftmVhlDstnBn5 "NOx Tracking Valid NOx Lifetime Vehicle Distance Bin 5: Accumulated Vehicle distance while all NOx sensors are active over the lifetime of the vehicle for Bin 5.";
CM_ SG_ 2566588670 NOxTrkngVldNOxLftmVhlDstnBn6 "NOx Tracking Valid NOx Lifetime Vehicle Distance Bin 6: Accumulated Vehicle distance while all NOx sensors are active over the lifetime of the vehicle for Bin 6. ";
CM_ SG_ 2566588670 NOxTrkngVldNOxLftmVhlDstnBn7 "NOx Tracking Valid NOx Lifetime Vehicle Distance Bin 7: Accumulated Vehicle distance while all NOx sensors are active over the lifetime of the vehicle for Bin 7. ";
CM_ SG_ 2566588670 NOxTrkngVldNOxLftmVhlDstnBn8 "NOx Tracking Valid NOx Lifetime Vehicle Distance Bin 8: Accumulated Vehicle distance while all NOx sensors are active over the lifetime of the vehicle for Bin 8. ";
CM_ SG_ 2566588670 NOxTrkngVldNOxLftmVhlDstnBn9 "NOx Tracking Valid NOx Lifetime Vehicle Distance Bin 9: Accumulated Vehicle distance while all NOx sensors are active over the lifetime of the vehicle for Bin 9";
CM_ SG_ 2566588670 NOxTrkngVldNOxLftmVhlDstnBn10 "NOx Tracking Valid NOx Lifetime Vehicle Distance Bin 10: Accumulated Vehicle distance while all NOx sensors are active over the lifetime of the vehicle for Bin 10";
CM_ SG_ 2566588670 NOxTrkngVldNOxLftmVhlDstnBn11 "NOx Tracking Valid NOx Lifetime Vehicle Distance Bin 11: Accumulated Vehicle distance while all NOx sensors are active over the lifetime of the vehicle for Bin 11";
CM_ SG_ 2566588670 NOxTrkngVldNOxLftmVhlDstnBn12 "NOx Tracking Valid NOx Lifetime Vehicle Distance Bin 12: Accumulated Vehicle distance while all NOx sensors are active over the lifetime of the vehicle for Bin 12";
CM_ SG_ 2566588670 NOxTrkngVldNOxLftmVhlDstnBn13 "NOx Tracking Valid NOx Lifetime Vehicle Distance Bin 13: Accumulated Vehicle distance while all NOx sensors are active over the lifetime of the vehicle for Bin 13";
CM_ SG_ 2566588670 NOxTrkngVldNOxLftmVhlDstnBn14 "NOx Tracking Valid NOx Lifetime Vehicle Distance Bin 14 : Accumulated Vehicle distance while all NOx sensors are active over the lifetime of the vehicle for Bin 14";
CM_ SG_ 2566588670 NOxTVdNOxLtVDstB15NTEBIN "NOx Tracking Valid NOx Lifetime Vehicle Distance Bin 15 (NTE BIN) : Accumulated Vehicle distance while all NOx sensors are active over the lifetime of the vehicle for Bin 15 [Note Bin 15 is the NTE Bin]";
CM_ SG_ 2566588670 NOxTVdNOxLtVDstB16RB "NOx Tracking Valid NOx Lifetime Vehicle Distance Bin 16 (Regen Bin) : Accumulated Vehicle distance while all NOx sensors are active over the lifetime of the vehicle for Bin 16 [Note Bin 16 is the Regen Bin]";
CM_ SG_ 2566588670 NOxTVdNOxLtVDstB17MILOB "NOx Tracking Valid NOx Lifetime Vehicle Distance Bin 17 (MIL On Bin) : Accumulated Vehicle distance while all NOx sensors are active over the lifetime of the vehicle for Bin 17 [Note Bin 17 is the MIL On Bin]";
CM_ BO_ 2566588926 "NOx Tracking Valid NOx Lifetime Engine Output Energy Bins ";
CM_ SG_ 2566588926 NOxTVdNOxLtEOtptEB1Tt "NOx Tracking Valid NOx Lifetime Engine Output Energy Bin 1 (Total): Accumulated Engine output energy while all NOx sensors are active over the lifetime of the vehicle for Bin 1 [Note Bin 1 is the total of Bins 2-14]";
CM_ SG_ 2566588926 NOxTVdNOxLtEOtptEB2 "NOx Tracking Valid NOx Lifetime Engine Output Energy Bin 2 : Accumulated Engine output energy while all NOx sensors are active over the lifetime of the vehicle for Bin 2 [Note Bin 2 is the 'idle' bin]";
CM_ SG_ 2566588926 NOxTVdNOxLtEOtptEB3 "NOx Tracking Valid NOx Lifetime Engine Output Energy Bin 3 : Accumulated Engine output energy while all NOx sensors are active over the lifetime of the vehicle for Bin 3.";
CM_ SG_ 2566588926 NOxTVdNOxLtEOtptEB4 "NOx Tracking Valid NOx Lifetime Engine Output Energy Bin 4: Accumulated Engine output energy while all NOx sensors are active over the lifetime of the vehicle for Bin 4. ";
CM_ SG_ 2566588926 NOxTVdNOxLtEOtptEB5 "NOx Tracking Valid NOx Lifetime Engine Output Energy Bin 5: Accumulated Engine output energy while all NOx sensors are active over the lifetime of the vehicle for Bin 5.";
CM_ SG_ 2566588926 NOxTVdNOxLtEOtptEB6 "NOx Tracking Valid NOx Lifetime Engine Output Energy Bin 6: Accumulated Engine output energy while all NOx sensors are active over the lifetime of the vehicle for Bin 6. ";
CM_ SG_ 2566588926 NOxTVdNOxLtEOtptEB7 "NOx Tracking Valid NOx Lifetime Engine Output Energy Bin 7: Accumulated Engine output energy while all NOx sensors are active over the lifetime of the vehicle for Bin 7. ";
CM_ SG_ 2566588926 NOxTVdNOxLtEOtptEB8 "NOx Tracking Valid NOx Lifetime Engine Output Energy Bin 8: Accumulated Engine output energy while all NOx sensors are active over the lifetime of the vehicle for Bin 8. ";
CM_ SG_ 2566588926 NOxTVdNOxLtEOtptEB9 "NOx Tracking Valid NOx Lifetime Engine Output Energy Bin 9: Accumulated Engine output energy while all NOx sensors are active over the lifetime of the vehicle for Bin 9";
CM_ SG_ 2566588926 NOxTVdNOxLtEOtptEB10 "NOx Tracking Valid NOx Lifetime Engine Output Energy Bin 10: Accumulated Engine output energy while all NOx sensors are active over the lifetime of the vehicle for Bin 10";
CM_ SG_ 2566588926 NOxTVdNOxLtEOtptEB11 "NOx Tracking Valid NOx Lifetime Engine Output Energy Bin 11: Accumulated Engine output energy while all NOx sensors are active over the lifetime of the vehicle for Bin 11";
CM_ SG_ 2566588926 NOxTVdNOxLtEOtptEB12 "NOx Tracking Valid NOx Lifetime Engine Output Energy Bin 12: Accumulated Engine output energy while all NOx sensors are active over the lifetime of the vehicle for Bin 12";
CM_ SG_ 2566588926 NOxTVdNOxLtEOtptEB13 "NOx Tracking Valid NOx Lifetime Engine Output Energy Bin 13: Accumulated Engine output energy while all NOx sensors are active over the lifetime of the vehicle for Bin 13";
CM_ SG_ 2566588926 NOxTVdNOxLtEOtptEB14 "NOx Tracking Valid NOx Lifetime Engine Output Energy Bin 14 : Accumulated Engine output energy while all NOx sensors are active over the lifetime of the vehicle for Bin 14";
CM_ SG_ 2566588926 NOxTVdNOxLtEOtptEB15NTEBIN "NOx Tracking Valid NOx Lifetime Engine Output Energy Bin 15 (NTE BIN) : Accumulated Engine output energy while all NOx sensors are active over the lifetime of the vehicle for Bin 15 [Note Bin 15 is the NTE Bin]";
CM_ SG_ 2566588926 NOxTVdNOxLtEOtptEB16RB "NOx Tracking Valid NOx Lifetime Engine Output Energy Bin 16 (Regen Bin) : Accumulated Engine output energy while all NOx sensors are active over the lifetime of the vehicle for Bin 16 [Note Bin 16 is the Regen Bin]";
CM_ SG_ 2566588926 NOxTVdNOxLtEOtptEB17MILOB "NOx Tracking Valid NOx Lifetime Engine Output Energy Bin 17 (MIL On Bin) : Accumulated Engine output energy while all NOx sensors are active over the lifetime of the vehicle for Bin 17 [Note Bin 17 is the MIL On Bin]";
CM_ BO_ 2566589182 "NOx Tracking Valid NOx Lifetime Engine Out NOx Mass Bins ";
CM_ SG_ 2566589182 NOxTVdNOxLtEOtNOxMssB1Tt "NOx Tracking Valid NOx Lifetime Engine Out NOx Mass Bin 1 (Total): Accumulated Engine out NOx mass while all NOx sensors are active over the lifetime of the vehicle for Bin 1 [Note Bin 1 is the total of Bins 2-14]";
CM_ SG_ 2566589182 NOxTVdNOxLtEOtNOxMssB2 "NOx Tracking Valid NOx Lifetime Engine Out NOx Mass Bin 2 : Accumulated Engine out NOx mass while all NOx sensors are active over the lifetime of the vehicle for Bin 2 [Note Bin 2 is the 'idle' bin]";
CM_ SG_ 2566589182 NOxTVdNOxLtEOtNOxMssB3 "NOx Tracking Valid NOx Lifetime Engine Out NOx Mass Bin 3 : Accumulated Engine out NOx mass while all NOx sensors are active over the lifetime of the vehicle for Bin 3. ";
CM_ SG_ 2566589182 NOxTVdNOxLtEOtNOxMssB4 "NOx Tracking Valid NOx Lifetime Engine Out NOx Mass Bin 4: Accumulated Engine out NOx mass while all NOx sensors are active over the lifetime of the vehicle for Bin 4. ";
CM_ SG_ 2566589182 NOxTVdNOxLtEOtNOxMssB5 "NOx Tracking Valid NOx Lifetime Engine Out NOx Mass Bin 5: Accumulated Engine out NOx mass while all NOx sensors are active over the lifetime of the vehicle for Bin 5.";
CM_ SG_ 2566589182 NOxTVdNOxLtEOtNOxMssB6 "NOx Tracking Valid NOx Lifetime Engine Out NOx Mass Bin 6: Accumulated Engine out NOx mass while all NOx sensors are active over the lifetime of the vehicle for Bin 6. ";
CM_ SG_ 2566589182 NOxTVdNOxLtEOtNOxMssB7 "NOx Tracking Valid NOx Lifetime Engine Out NOx Mass Bin 7: Accumulated Engine out NOx mass while all NOx sensors are active over the lifetime of the vehicle for Bin 7. ";
CM_ SG_ 2566589182 NOxTVdNOxLtEOtNOxMssB8 "NOx Tracking Valid NOx Lifetime Engine Out NOx Mass Bin 8: Accumulated Engine out NOx mass while all NOx sensors are active over the lifetime of the vehicle for Bin 8. ";
CM_ SG_ 2566589182 NOxTVdNOxLtEOtNOxMssB9 "NOx Tracking Valid NOx Lifetime Engine Out NOx Mass Bin 9: Accumulated Engine out NOx mass while all NOx sensors are active over the lifetime of the vehicle for Bin 9";
CM_ SG_ 2566589182 NOxTVdNOxLtEOtNOxMssB10 "NOx Tracking Valid NOx Lifetime Engine Out NOx Mass Bin 10: Accumulated Engine out NOx mass while all NOx sensors are active over the lifetime of the vehicle for Bin 10";
CM_ SG_ 2566589182 NOxTVdNOxLtEOtNOxMssB11 "NOx Tracking Valid NOx Lifetime Engine Out NOx Mass Bin 11: Accumulated Engine out NOx mass while all NOx sensors are active over the lifetime of the vehicle for Bin 11";
CM_ SG_ 2566589182 NOxTVdNOxLtEOtNOxMssB12 "NOx Tracking Valid NOx Lifetime Engine Out NOx Mass Bin 12: Accumulated Engine out NOx mass while all NOx sensors are active over the lifetime of the vehicle for Bin 12";
CM_ SG_ 2566589182 NOxTVdNOxLtEOtNOxMssB13 "NOx Tracking Valid NOx Lifetime Engine Out NOx Mass Bin 13: Accumulated Engine out NOx mass while all NOx sensors are active over the lifetime of the vehicle for Bin 13";
CM_ SG_ 2566589182 NOxTVdNOxLtEOtNOxMssB14 "NOx Tracking Valid NOx Lifetime Engine Out NOx Mass Bin 14 : Accumulated Engine out NOx mass while all NOx sensors are active over the lifetime of the vehicle for Bin 14";
CM_ SG_ 2566589182 NOxTVdNOxLtEOtNOxMssB15NTEBIN "NOx Tracking Valid NOx Lifetime Engine Out NOx Mass Bin 15 (NTE BIN) : Accumulated Engine out NOx mass while all NOx sensors are active over the lifetime of the vehicle for Bin 15 [Note Bin 15 is the NTE Bin]";
CM_ SG_ 2566589182 NOxTVdNOxLtEOtNOxMssB16RB "NOx Tracking Valid NOx Lifetime Engine Out NOx Mass Bin 16 (Regen Bin) : Accumulated Engine out NOx mass while all NOx sensors are active over the lifetime of the vehicle for Bin 16 [Note Bin 16 is the Regen Bin]";
CM_ SG_ 2566589182 NOxTVdNOxLtEOtNOxMssB17MILOB "NOx Tracking Valid NOx Lifetime Engine Out NOx Mass Bin 17 (MIL On Bin): Accumulated Engine out NOx mass while all NOx sensors are active over the lifetime of the vehicle for Bin 17 [Note Bin 17 is the MIL On Bin]";
CM_ BO_ 2566589438 "NOx Tracking Valid NOx Lifetime System Out NOx Mass Bins ";
CM_ SG_ 2566589438 NOxTVdNOxLtSstOtNOxMssB1Tt "NOx Tracking Valid NOx Lifetime System Out NOx Mass Bin 1 (Total): Accumulated system out [SCR outlet] NOx mass while all NOx sensors are active over the lifetime of the vehicle for Bin 1 [Note Bin 1 is the total of Bins 2-14]";
CM_ SG_ 2566589438 NOxTVdNOxLtSstOtNOxMssB2 "NOx Tracking Valid NOx Lifetime System Out NOx Mass Bin 2 : Accumulated system out [SCR outlet] NOx mass while all NOx sensors are active over the lifetime of the vehicle for Bin 2 [Note Bin 2 is the 'idle' bin]";
CM_ SG_ 2566589438 NOxTVdNOxLtSstOtNOxMssB3 "NOx Tracking Valid NOx Lifetime System Out NOx Mass Bin 3 : Accumulated system out [SCR outlet] NOx mass while all NOx sensors are active over the lifetime of the vehicle for Bin 3. ";
CM_ SG_ 2566589438 NOxTVdNOxLtSstOtNOxMssB4 "NOx Tracking Valid NOx Lifetime System Out NOx Mass Bin 4: Accumulated system out [SCR outlet] NOx mass while all NOx sensors are active over the lifetime of the vehicle for Bin 4.";
CM_ SG_ 2566589438 NOxTVdNOxLtSstOtNOxMssB5 "NOx Tracking Valid NOx Lifetime System Out NOx Mass Bin 5: Accumulated system out [SCR outlet] NOx mass while all NOx sensors are active over the lifetime of the vehicle for Bin 5.";
CM_ SG_ 2566589438 NOxTVdNOxLtSstOtNOxMssB6 "NOx Tracking Valid NOx Lifetime System Out NOx Mass Bin 6: Accumulated system out [SCR outlet] NOx mass while all NOx sensors are active over the lifetime of the vehicle for Bin 6. ";
CM_ SG_ 2566589438 NOxTVdNOxLtSstOtNOxMssB7 "NOx Tracking Valid NOx Lifetime System Out NOx Mass Bin 7: Accumulated system out [SCR outlet] NOx mass while all NOx sensors are active over the lifetime of the vehicle for Bin 7. ";
CM_ SG_ 2566589438 NOxTVdNOxLtSstOtNOxMssB8 "NOx Tracking Valid NOx Lifetime System Out NOx Mass Bin 8: Accumulated system out [SCR outlet] NOx mass while all NOx sensors are active over the lifetime of the vehicle for Bin 8. ";
CM_ SG_ 2566589438 NOxTVdNOxLtSstOtNOxMssB9 "NOx Tracking Valid NOx Lifetime System Out NOx Mass Bin 9: Accumulated system out [SCR outlet] NOx mass while all NOx sensors are active over the lifetime of the vehicle for Bin 9";
CM_ SG_ 2566589438 NOxTVdNOxLtSstOtNOxMssB10 "NOx Tracking Valid NOx Lifetime System Out NOx Mass Bin 10: Accumulated system out [SCR outlet] NOx mass while all NOx sensors are active over the lifetime of the vehicle for Bin 10 ";
CM_ SG_ 2566589438 NOxTVdNOxLtSstOtNOxMssB11 "NOx Tracking Valid NOx Lifetime System Out NOx Mass Bin 11: Accumulated system out [SCR outlet] NOx mass while all NOx sensors are active over the lifetime of the vehicle for Bin 11";
CM_ SG_ 2566589438 NOxTVdNOxLtSstOtNOxMssB12 "NOx Tracking Valid NOx Lifetime System Out NOx Mass Bin 12: Accumulated system out [SCR outlet] NOx mass while all NOx sensors are active over the lifetime of the vehicle for Bin 12";
CM_ SG_ 2566589438 NOxTVdNOxLtSstOtNOxMssB13 "NOx Tracking Valid NOx Lifetime System Out NOx Mass Bin 13: Accumulated system out [SCR outlet] NOx mass while all NOx sensors are active over the lifetime of the vehicle for Bin 13";
CM_ SG_ 2566589438 NOxTVdNOxLtSstOtNOxMssB14 "NOx Tracking Valid NOx Lifetime System Out NOx Mass Bin 14 : Accumulated system out [SCR outlet] NOx mass while all NOx sensors are active over the lifetime of the vehicle for Bin 14";
CM_ SG_ 2566589438 NOxTVdNOxLtSstOtNOxMssB15NTEBIN "NOx Tracking Valid NOx Lifetime System Out NOx Mass Bin 15 (NTE BIN) : Accumulated system out [SCR outlet] NOx mass while all NOx sensors are active over the lifetime of the vehicle for Bin 15 [Note Bin 15 is the Regen Bin]";
CM_ SG_ 2566589438 NOxTVdNOxLtSstOtNOxMssB16RB "NOx Tracking Valid NOx Lifetime System Out NOx Mass Bin 16 (Regen Bin) : Accumulated system out [SCR outlet] NOx mass while all NOx sensors are active over the lifetime of the vehicle for Bin 16 [Note Bin 16 is the Regen Bin]";
CM_ SG_ 2566589438 NOxTVdNOxLtSstOtNOxMssB17MILOB "NOx Tracking Valid NOx Lifetime System Out NOx Mass Bin 17 (MIL On Bin) : Accumulated system out [SCR outlet] NOx mass while all NOx sensors are active over the lifetime of the vehicle for Bin 17 [Note Bin 17 is the MIL On Bin]";
CM_ BO_ 2566589694 "NOx Tracking Stored 100 Hour Fuel Consumption Bins ";
CM_ SG_ 2566589694 NOxTStd100HFCsptB1Tt "NOx Tracking Stored 100 Hour Fuel Consumption Bin 1 (Total): Accumulated Fuel consumption while all NOx sensors are active over the prior 100 hour period for Bin 1 [Note Bin 1 is the total of Bins 2-14]";
CM_ SG_ 2566589694 NOxTrkngStrd100HrFlCnsmptnBn2 "NOx Tracking Stored 100 Hour Fuel Consumption Bin 2 : Accumulated Fuel consumption while all NOx sensors are active over the prior 100 hour period for Bin 2 [Note Bin 2 is the 'idle' bin]";
CM_ SG_ 2566589694 NOxTrkngStrd100HrFlCnsmptnBn3 "NOx Tracking Stored 100 Hour Fuel Consumption Bin 3 : Accumulated Fuel consumption while all NOx sensors are active over the prior 100 hour period for Bin 3. ";
CM_ SG_ 2566589694 NOxTrkngStrd100HrFlCnsmptnBn4 "NOx Tracking Stored 100 Hour Fuel Consumption Bin 4: Accumulated Fuel consumption while all NOx sensors are active over the prior 100 hour period for Bin 4. ";
CM_ SG_ 2566589694 NOxTrkngStrd100HrFlCnsmptnBn5 "NOx Tracking Stored 100 Hour Fuel Consumption Bin 5: Accumulated Fuel consumption while all NOx sensors are active over the prior 100 hour period for Bin 5.";
CM_ SG_ 2566589694 NOxTrkngStrd100HrFlCnsmptnBn6 "NOx Tracking Stored 100 Hour Fuel Consumption Bin 6: Accumulated Fuel consumption while all NOx sensors are active over the prior 100 hour period for Bin 6. ";
CM_ SG_ 2566589694 NOxTrkngStrd100HrFlCnsmptnBn7 "NOx Tracking Stored 100 Hour Fuel Consumption Bin 7: Accumulated Fuel consumption while all NOx sensors are active over the prior 100 hour period for Bin 7. ";
CM_ SG_ 2566589694 NOxTrkngStrd100HrFlCnsmptnBn8 "NOx Tracking Stored 100 Hour Fuel Consumption Bin 8: Accumulated Fuel consumption while all NOx sensors are active over the prior 100 hour period for Bin 8. ";
CM_ SG_ 2566589694 NOxTrkngStrd100HrFlCnsmptnBn9 "NOx Tracking Stored 100 Hour Fuel Consumption Bin 9: Accumulated Fuel consumption while all NOx sensors are active over the prior 100 hour period for Bin 9";
CM_ SG_ 2566589694 NOxTrkngStrd100HrFlCnsmptnBn10 "NOx Tracking Stored 100 Hour Fuel Consumption Bin 10: Accumulated Fuel consumption while all NOx sensors are active over the prior 100 hour period for Bin 10";
CM_ SG_ 2566589694 NOxTrkngStrd100HrFlCnsmptnBn11 "NOx Tracking Stored 100 Hour Fuel Consumption Bin 11: Accumulated Fuel consumption while all NOx sensors are active over the prior 100 hour period for Bin 11";
CM_ SG_ 2566589694 NOxTrkngStrd100HrFlCnsmptnBn12 "NOx Tracking Stored 100 Hour Fuel Consumption Bin 12: Accumulated Fuel consumption while all NOx sensors are active over the prior 100 hour period for Bin 12";
CM_ SG_ 2566589694 NOxTrkngStrd100HrFlCnsmptnBn13 "NOx Tracking Stored 100 Hour Fuel Consumption Bin 13: Accumulated Fuel consumption while all NOx sensors are active over the prior 100 hour period for Bin 13";
CM_ SG_ 2566589694 NOxTrkngStrd100HrFlCnsmptnBn14 "NOx Tracking Stored 100 Hour Fuel Consumption Bin 14 : Accumulated Fuel consumption while all NOx sensors are active over the prior 100 hour period for Bin 14";
CM_ SG_ 2566589694 NOxTStd100HFCsptB15NTEBIN "NOx Tracking Stored 100 Hour Fuel Consumption Bin 15 (NTE BIN) : Accumulated Fuel consumption while all NOx sensors are active over the prior 100 hour period for Bin 15 [Note Bin 15 is the NTE Bin]";
CM_ SG_ 2566589694 NOxTStd100HFCsptB16RB "NOx Tracking Stored 100 Hour Fuel Consumption Bin 16 (Regen Bin) : Accumulated Fuel consumption while all NOx sensors are active over the prior 100 hour period for Bin 16 [Note Bin 16 is the Regen Bin]";
CM_ SG_ 2566589694 NOxTStd100HFCsptB17MILOB "NOx Tracking Stored 100 Hour Fuel Consumption Bin 17 (MIL On Bin) : Accumulated Fuel consumption while all NOx sensors are active over the prior 100 hour period for Bin 17 [Note Bin 17 is the MIL On Bin]";
CM_ BO_ 2566589950 "NOx Tracking Stored 100 Hour Engine Run Time Bins ";
CM_ SG_ 2566589950 NOxTrkngStrd100HrEngnRnTmBn1Ttl "NOx Tracking Stored 100 Hour Engine Run Time Bin 1 (Total): Accumulated Engine run time while all NOx sensors are active over the prior 100 hour period for Bin 1 [Note Bin 1 is the total of Bins 2-14]";
CM_ SG_ 2566589950 NOxTrkngStrd100HrEngnRnTmBn2 "NOx Tracking Stored 100 Hour Engine Run Time Bin 2 : Accumulated Engine run time while all NOx sensors are active over the prior 100 hour period for Bin 2 [Note Bin 2 is the 'idle' bin]";
CM_ SG_ 2566589950 NOxTrkngStrd100HrEngnRnTmBn3 "NOx Tracking Stored 100 Hour Engine Run Time Bin 3 : Accumulated Engine run time while all NOx sensors are active over the prior 100 hour period for Bin 3.";
CM_ SG_ 2566589950 NOxTrkngStrd100HrEngnRnTmBn4 "NOx Tracking Stored 100 Hour Engine Run Time Bin 4: Accumulated Engine run time while all NOx sensors are active over the prior 100 hour period for Bin 4.";
CM_ SG_ 2566589950 NOxTrkngStrd100HrEngnRnTmBn5 "NOx Tracking Stored 100 Hour Engine Run Time Bin 5: Accumulated Engine run time while all NOx sensors are active over the prior 100 hour period for Bin 5.";
CM_ SG_ 2566589950 NOxTrkngStrd100HrEngnRnTmBn6 "NOx Tracking Stored 100 Hour Engine Run Time Bin 6: Accumulated Engine run time while all NOx sensors are active over the prior 100 hour period for Bin 6. ";
CM_ SG_ 2566589950 NOxTrkngStrd100HrEngnRnTmBn7 "NOx Tracking Stored 100 Hour Engine Run Time Bin 7: Accumulated Engine run time while all NOx sensors are active over the prior 100 hour period for Bin 7. ";
CM_ SG_ 2566589950 NOxTrkngStrd100HrEngnRnTmBn8 "NOx Tracking Stored 100 Hour Engine Run Time Bin 8: Accumulated Engine run time while all NOx sensors are active over the prior 100 hour period for Bin 8. ";
CM_ SG_ 2566589950 NOxTrkngStrd100HrEngnRnTmBn9 "NOx Tracking Stored 100 Hour Engine Run Time Bin 9: Accumulated Engine run time while all NOx sensors are active over the prior 100 hour period for Bin 9";
CM_ SG_ 2566589950 NOxTrkngStrd100HrEngnRnTmBn10 "NOx Tracking Stored 100 Hour Engine Run Time Bin 10: Accumulated Engine run time while all NOx sensors are active over the prior 100 hour period for Bin 10";
CM_ SG_ 2566589950 NOxTrkngStrd100HrEngnRnTmBn11 "NOx Tracking Stored 100 Hour Engine Run Time Bin 11: Accumulated Engine run time while all NOx sensors are active over the prior 100 hour period for Bin 11";
CM_ SG_ 2566589950 NOxTrkngStrd100HrEngnRnTmBn12 "NOx Tracking Stored 100 Hour Engine Run Time Bin 12: Accumulated Engine run time while all NOx sensors are active over the prior 100 hour period for Bin 12";
CM_ SG_ 2566589950 NOxTrkngStrd100HrEngnRnTmBn13 "NOx Tracking Stored 100 Hour Engine Run Time Bin 13: Accumulated Engine run time while all NOx sensors are active over the prior 100 hour period for Bin 13";
CM_ SG_ 2566589950 NOxTrkngStrd100HrEngnRnTmBn14 "NOx Tracking Stored 100 Hour Engine Run Time Bin 14 : Accumulated Engine run time while all NOx sensors are active over the prior 100 hour period for Bin 14";
CM_ SG_ 2566589950 NOxTStd100HERTB15NTEBIN "NOx Tracking Stored 100 Hour Engine Run Time Bin 15 (NTE BIN) : Accumulated Engine run time while all NOx sensors are active over the prior 100 hour period for Bin 15 [Note Bin 15 is the NTE Bin]";
CM_ SG_ 2566589950 NOxTStd100HERTB16RB "NOx Tracking Stored 100 Hour Engine Run Time Bin 16 (Regen Bin) : Accumulated Engine run time while all NOx sensors are active over the prior 100 hour period for Bin 16 [Note Bin 16 is the Regen Bin]";
CM_ SG_ 2566589950 NOxTStd100HERTB17MILOB "NOx Tracking Stored 100 Hour Engine Run Time Bin 17 (MIL On Bin) : Accumulated Engine run time while all NOx sensors are active over the prior 100 hour period for Bin 17 [Note Bin 17 is the MIL On Bin]";
CM_ BO_ 2566590206 "NOx Tracking Stored 100 Hour Vehicle Distance Bins ";
CM_ SG_ 2566590206 NOxTrkngStrd100HrVhlDstnBn1Ttl "NOx Tracking Stored 100 Hour Vehicle Distance Bin 1 (Total): Accumulated Vehicle distance while all NOx sensors are active over the prior 100 hour period for Bin 1 [Note Bin 1 is the total of Bins 2-14]";
CM_ SG_ 2566590206 NOxTrkngStrd100HrVhlDstnBn2 "NOx Tracking Stored 100 Hour Vehicle Distance Bin 2 : Accumulated Vehicle distance while all NOx sensors are active over the prior 100 hour period for Bin 2 [Note Bin 2 is the 'idle' bin]";
CM_ SG_ 2566590206 NOxTrkngStrd100HrVhlDstnBn3 "NOx Tracking Stored 100 Hour Vehicle Distance Bin 3 : Accumulated Vehicle distance while all NOx sensors are active over the prior 100 hour period for Bin 3.";
CM_ SG_ 2566590206 NOxTrkngStrd100HrVhlDstnBn4 "NOx Tracking Stored 100 Hour Vehicle Distance Bin 4: Accumulated Vehicle distance while all NOx sensors are active over the prior 100 hour period for Bin 4.";
CM_ SG_ 2566590206 NOxTrkngStrd100HrVhlDstnBn5 "NOx Tracking Stored 100 Hour Vehicle Distance Bin 5: Accumulated Vehicle distance while all NOx sensors are active over the prior 100 hour period for Bin 5.";
CM_ SG_ 2566590206 NOxTrkngStrd100HrVhlDstnBn6 "NOx Tracking Stored 100 Hour Vehicle Distance Bin 6: Accumulated Vehicle distance while all NOx sensors are active over the prior 100 hour period for Bin 6. ";
CM_ SG_ 2566590206 NOxTrkngStrd100HrVhlDstnBn7 "NOx Tracking Stored 100 Hour Vehicle Distance Bin 7: Accumulated Vehicle distance while all NOx sensors are active over the prior 100 hour period for Bin 7. ";
CM_ SG_ 2566590206 NOxTrkngStrd100HrVhlDstnBn8 "NOx Tracking Stored 100 Hour Vehicle Distance Bin 8: Accumulated Vehicle distance while all NOx sensors are active over the prior 100 hour period for Bin 8. ";
CM_ SG_ 2566590206 NOxTrkngStrd100HrVhlDstnBn9 "NOx Tracking Stored 100 Hour Vehicle Distance Bin 9: Accumulated Vehicle distance while all NOx sensors are active over the prior 100 hour period for Bin 9";
CM_ SG_ 2566590206 NOxTrkngStrd100HrVhlDstnBn10 "NOx Tracking Stored 100 Hour Vehicle Distance Bin 10: Accumulated Vehicle distance while all NOx sensors are active over the prior 100 hour period for Bin 10";
CM_ SG_ 2566590206 NOxTrkngStrd100HrVhlDstnBn11 "NOx Tracking Stored 100 Hour Vehicle Distance Bin 11: Accumulated Vehicle distance while all NOx sensors are active over the prior 100 hour period for Bin 11";
CM_ SG_ 2566590206 NOxTrkngStrd100HrVhlDstnBn12 "NOx Tracking Stored 100 Hour Vehicle Distance Bin 12: Accumulated Vehicle distance while all NOx sensors are active over the prior 100 hour period for Bin 12";
CM_ SG_ 2566590206 NOxTrkngStrd100HrVhlDstnBn13 "NOx Tracking Stored 100 Hour Vehicle Distance Bin 13: Accumulated Vehicle distance while all NOx sensors are active over the prior 100 hour period for Bin 13";
CM_ SG_ 2566590206 NOxTrkngStrd100HrVhlDstnBn14 "NOx Tracking Stored 100 Hour Vehicle Distance Bin 14 : Accumulated Vehicle distance while all NOx sensors are active over the prior 100 hour period for Bin 14";
CM_ SG_ 2566590206 NOxTStd100HVDstB15NTEBIN "NOx Tracking Stored 100 Hour Vehicle Distance Bin 15 (NTE BIN) : Accumulated Vehicle distance while all NOx sensors are active over the prior 100 hour period for Bin 15 [Note Bin 15 is the NTE Bin]";
CM_ SG_ 2566590206 NOxTStd100HVDstB16RB "NOx Tracking Stored 100 Hour Vehicle Distance Bin 16 (Regen Bin) : Accumulated Vehicle distance while all NOx sensors are active over the prior 100 hour period for Bin 16 [Note Bin 16 is the Regen Bin]";
CM_ SG_ 2566590206 NOxTStd100HVDstB17MILOB "NOx Tracking Stored 100 Hour Vehicle Distance Bin 17 (MIL On Bin) : Accumulated Vehicle distance while all NOx sensors are active over the prior 100 hour period for Bin 17 [Note Bin 17 is the MIL ON Bin]";
CM_ BO_ 2566590462 "NOx Tracking Stored 100 Hour Engine Output Energy Bins ";
CM_ SG_ 2566590462 NOxTStd100HEOtptEB1Tt "NOx Tracking Stored 100 Hour Engine Output Energy Bin 1 (Total): Accumulated Engine output energy while all NOx sensors are active over the prior 100 hour period for Bin 1 [Note Bin 1 is the total of Bins 2-14]";
CM_ SG_ 2566590462 NOxTStd100HEOtptEB2 "NOx Tracking Stored 100 Hour Engine Output Energy Bin 2 : Accumulated Engine output energy while all NOx sensors are active over the prior 100 hour period for Bin 2 [Note Bin 2 is the 'idle' bin]";
CM_ SG_ 2566590462 NOxTStd100HEOtptEB3 "NOx Tracking Stored 100 Hour Engine Output Energy Bin 3 : Accumulated Engine output energy while all NOx sensors are active over the prior 100 hour period for Bin 3. ";
CM_ SG_ 2566590462 NOxTStd100HEOtptEB4 "NOx Tracking Stored 100 Hour Engine Output Energy Bin 4: Accumulated Engine output energy while all NOx sensors are active over the prior 100 hour period for Bin 4.";
CM_ SG_ 2566590462 NOxTStd100HEOtptEB5 "NOx Tracking Stored 100 Hour Engine Output Energy Bin 5: Accumulated Engine output energy while all NOx sensors are active over the prior 100 hour period for Bin 5.";
CM_ SG_ 2566590462 NOxTStd100HEOtptEB6 "NOx Tracking Stored 100 Hour Engine Output Energy Bin 6: Accumulated Engine output energy while all NOx sensors are active over the prior 100 hour period for Bin 6. ";
CM_ SG_ 2566590462 NOxTStd100HEOtptEB7 "NOx Tracking Stored 100 Hour Engine Output Energy Bin 7: Accumulated Engine output energy while all NOx sensors are active over the prior 100 hour period for Bin 7. ";
CM_ SG_ 2566590462 NOxTStd100HEOtptEB8 "NOx Tracking Stored 100 Hour Engine Output Energy Bin 8: Accumulated Engine output energy while all NOx sensors are active over the prior 100 hour period for Bin 8. ";
CM_ SG_ 2566590462 NOxTStd100HEOtptEB9 "NOx Tracking Stored 100 Hour Engine Output Energy Bin 9: Accumulated Engine output energy while all NOx sensors are active over the prior 100 hour period for Bin 9";
CM_ SG_ 2566590462 NOxTStd100HEOtptEB10 "NOx Tracking Stored 100 Hour Engine Output Energy Bin 10: Accumulated Engine output energy while all NOx sensors are active over the prior 100 hour period for Bin 10";
CM_ SG_ 2566590462 NOxTStd100HEOtptEB11 "NOx Tracking Stored 100 Hour Engine Output Energy Bin 11: Accumulated Engine output energy while all NOx sensors are active over the prior 100 hour period for Bin 11";
CM_ SG_ 2566590462 NOxTStd100HEOtptEB12 "NOx Tracking Stored 100 Hour Engine Output Energy Bin 12: Accumulated Engine output energy while all NOx sensors are active over the prior 100 hour period for Bin 12";
CM_ SG_ 2566590462 NOxTStd100HEOtptEB13 "NOx Tracking Stored 100 Hour Engine Output Energy Bin 13: Accumulated Engine output energy while all NOx sensors are active over the prior 100 hour period for Bin 13";
CM_ SG_ 2566590462 NOxTStd100HEOtptEB14 "NOx Tracking Stored 100 Hour Engine Output Energy Bin 14 : Accumulated Engine output energy while all NOx sensors are active over the prior 100 hour period for Bin 14";
CM_ SG_ 2566590462 NOxTStd100HEOtptEB15NTEBIN "NOx Tracking Stored 100 Hour Engine Output Energy Bin 15 (NTE BIN) : Accumulated Engine output energy while all NOx sensors are active over the prior 100 hour period for Bin 15 [Note Bin 15 is the NTE Bin]";
CM_ SG_ 2566590462 NOxTStd100HEOtptEB16RB "NOx Tracking Stored 100 Hour Engine Output Energy Bin 16 (Regen Bin) : Accumulated Engine output energy while all NOx sensors are active over the prior 100 hour period for Bin 16 [Note Bin 16 is the Regen Bin]";
CM_ SG_ 2566590462 NOxTStd100HEOtptEB17MILOB "NOx Tracking Stored 100 Hour Engine Output Energy Bin 17 (MIL On Bin) : Accumulated Engine output energy while all NOx sensors are active over the prior 100 hour period for Bin 17 [Note Bin 17 is the MIL On Bin]";
CM_ BO_ 2566590718 "NOx Tracking Stored 100 Hour Engine Out NOx Mass Bins ";
CM_ SG_ 2566590718 NOxTStd100HEOtNOxMssB1Tt "NOx Tracking Stored 100 Hour Engine Out NOx Mass Bin 1 (Total): Accumulated Engine out NOx mass while all NOx sensors are active over the prior 100 hour period for Bin 1 [Note Bin 1 is the total of Bins 2-14]";
CM_ SG_ 2566590718 NOxTStd100HEOtNOxMssB2 "NOx Tracking Stored 100 Hour Engine Out NOx Mass Bin 2 : Accumulated Engine out NOx mass while all NOx sensors are active over the prior 100 hour period for Bin 2 [Note Bin 2 is the 'idle' bin]";
CM_ SG_ 2566590718 NOxTStd100HEOtNOxMssB3 "NOx Tracking Stored 100 Hour Engine Out NOx Mass Bin 3 : Accumulated Engine out NOx mass while all NOx sensors are active over the prior 100 hour period for Bin 3. ";
CM_ SG_ 2566590718 NOxTStd100HEOtNOxMssB4 "NOx Tracking Stored 100 Hour Engine Out NOx Mass Bin 4: Accumulated Engine out NOx mass while all NOx sensors are active over the prior 100 hour period for Bin 4.";
CM_ SG_ 2566590718 NOxTStd100HEOtNOxMssB5 "NOx Tracking Stored 100 Hour Engine Out NOx Mass Bin 5: Accumulated Engine out NOx mass while all NOx sensors are active over the prior 100 hour period for Bin 5.";
CM_ SG_ 2566590718 NOxTStd100HEOtNOxMssB6 "NOx Tracking Stored 100 Hour Engine Out NOx Mass Bin 6: Accumulated Engine out NOx mass while all NOx sensors are active over the prior 100 hour period for Bin 6. ";
CM_ SG_ 2566590718 NOxTStd100HEOtNOxMssB7 "NOx Tracking Stored 100 Hour Engine Out NOx Mass Bin 7: Accumulated Engine out NOx mass while all NOx sensors are active over the prior 100 hour period for Bin 7. ";
CM_ SG_ 2566590718 NOxTStd100HEOtNOxMssB8 "NOx Tracking Stored 100 Hour Engine Out NOx Mass Bin 8: Accumulated Engine out NOx mass while all NOx sensors are active over the prior 100 hour period for Bin 8. ";
CM_ SG_ 2566590718 NOxTStd100HEOtNOxMssB9 "NOx Tracking Stored 100 Hour Engine Out NOx Mass Bin 9: Accumulated Engine out NOx mass while all NOx sensors are active over the prior 100 hour period for Bin 9";
CM_ SG_ 2566590718 NOxTStd100HEOtNOxMssB10 "NOx Tracking Stored 100 Hour Engine Out NOx Mass Bin 10: Accumulated Engine out NOx mass while all NOx sensors are active over the prior 100 hour period for Bin 10";
CM_ SG_ 2566590718 NOxTStd100HEOtNOxMssB11 "NOx Tracking Stored 100 Hour Engine Out NOx Mass Bin 11: Accumulated Engine out NOx mass while all NOx sensors are active over the prior 100 hour period for Bin 11";
CM_ SG_ 2566590718 NOxTStd100HEOtNOxMssB12 "NOx Tracking Stored 100 Hour Engine Out NOx Mass Bin 12: Accumulated Engine out NOx mass while all NOx sensors are active over the prior 100 hour period for Bin 12";
CM_ SG_ 2566590718 NOxTStd100HEOtNOxMssB13 "NOx Tracking Stored 100 Hour Engine Out NOx Mass Bin 13: Accumulated Engine out NOx mass while all NOx sensors are active over the prior 100 hour period for Bin 13";
CM_ SG_ 2566590718 NOxTStd100HEOtNOxMssB14 "NOx Tracking Stored 100 Hour Engine Out NOx Mass Bin 14 : Accumulated Engine out NOx mass while all NOx sensors are active over the prior 100 hour period for Bin 14";
CM_ SG_ 2566590718 NOxTStd100HEOtNOxMssB15NTEBIN "NOx Tracking Stored 100 Hour Engine Out NOx Mass Bin 15 (NTE BIN) : Accumulated Engine out NOx mass while all NOx sensors are active over the prior 100 hour period for Bin 15 [Note Bin 15 is the NTE Bin]";
CM_ SG_ 2566590718 NOxTStd100HEOtNOxMssB16RB "NOx Tracking Stored 100 Hour Engine Out NOx Mass Bin 16 (Regen Bin) : Accumulated Engine out NOx mass while all NOx sensors are active over the prior 100 hour period for Bin 16 [Note Bin 16 is the Regen Bin]";
CM_ SG_ 2566590718 NOxTStd100HEOtNOxMssB17MILOB "NOx Tracking Stored 100 Hour Engine Out NOx Mass Bin 17 (MIL On Bin) : Accumulated Engine out NOx mass while all NOx sensors are active over the prior 100 hour period for Bin 17 [Note Bin 17 is the Mil On Bin]";
CM_ BO_ 2566590974 "NOx Tracking Stored 100 Hour System Out NOx Mass Bins ";
CM_ SG_ 2566590974 NOxTStd100HSstOtNOxMssB1Tt "NOx Tracking Stored 100 Hour System Out NOx Mass Bin 1 (Total): Accumulated system out [SCR outlet] NOx mass while all NOx sensors are active over the prior 100 hour period for Bin 1 [Note Bin 1 is the total of Bins 2-14]";
CM_ SG_ 2566590974 NOxTStd100HSstOtNOxMssB2 "NOx Tracking Stored 100 Hour System Out NOx Mass Bin 2 : Accumulated system out [SCR outlet] NOx mass while all NOx sensors are active over the prior 100 hour period for Bin 2 [Note Bin 2 is the 'idle' bin]";
CM_ SG_ 2566590974 NOxTStd100HSstOtNOxMssB3 "NOx Tracking Stored 100 Hour System Out NOx Mass Bin 3 : Accumulated system out [SCR outlet] NOx mass while all NOx sensors are active over the prior 100 hour period for Bin 3.";
CM_ SG_ 2566590974 NOxTStd100HSstOtNOxMssB4 "NOx Tracking Stored 100 Hour System Out NOx Mass Bin 4: Accumulated system out [SCR outlet] NOx mass while all NOx sensors are active over the prior 100 hour period for Bin 4.";
CM_ SG_ 2566590974 NOxTStd100HSstOtNOxMssB5 "NOx Tracking Stored 100 Hour System Out NOx Mass Bin 5: Accumulated system out [SCR outlet] NOx mass while all NOx sensors are active over the prior 100 hour period for Bin 5.";
CM_ SG_ 2566590974 NOxTStd100HSstOtNOxMssB6 "NOx Tracking Stored 100 Hour System Out NOx Mass Bin 6: Accumulated system out [SCR outlet] NOx mass while all NOx sensors are active over the prior 100 hour period for Bin 6. ";
CM_ SG_ 2566590974 NOxTStd100HSstOtNOxMssB7 "NOx Tracking Stored 100 Hour System Out NOx Mass Bin 7: Accumulated system out [SCR outlet] NOx mass while all NOx sensors are active over the prior 100 hour period for Bin 7. ";
CM_ SG_ 2566590974 NOxTStd100HSstOtNOxMssB8 "NOx Tracking Stored 100 Hour System Out NOx Mass Bin 8: Accumulated system out [SCR outlet] NOx mass while all NOx sensors are active over the prior 100 hour period for Bin 8. ";
CM_ SG_ 2566590974 NOxTStd100HSstOtNOxMssB9 "NOx Tracking Stored 100 Hour System Out NOx Mass Bin 9: Accumulated system out [SCR outlet] NOx mass while all NOx sensors are active over the prior 100 hour period for Bin 9";
CM_ SG_ 2566590974 NOxTStd100HSstOtNOxMssB10 "NOx Tracking Stored 100 Hour System Out NOx Mass Bin 10: Accumulated system out [SCR outlet] NOx mass while all NOx sensors are active over the prior 100 hour period for Bin 10 ";
CM_ SG_ 2566590974 NOxTStd100HSstOtNOxMssB11 "NOx Tracking Stored 100 Hour System Out NOx Mass Bin 11: Accumulated system out [SCR outlet] NOx mass while all NOx sensors are active over the prior 100 hour period for Bin 11";
CM_ SG_ 2566590974 NOxTStd100HSstOtNOxMssB12 "NOx Tracking Stored 100 Hour System Out NOx Mass Bin 12: Accumulated system out [SCR outlet] NOx mass while all NOx sensors are active over the prior 100 hour period for Bin 12";
CM_ SG_ 2566590974 NOxTStd100HSstOtNOxMssB13 "NOx Tracking Stored 100 Hour System Out NOx Mass Bin 13: Accumulated system out [SCR outlet] NOx mass while all NOx sensors are active over the prior 100 hour period for Bin 13";
CM_ SG_ 2566590974 NOxTStd100HSstOtNOxMssB14 "NOx Tracking Stored 100 Hour System Out NOx Mass Bin 14 : Accumulated system out [SCR outlet] NOx mass while all NOx sensors are active over the prior 100 hour period for Bin 14";
CM_ SG_ 2566590974 NOxTStd100HSstOtNOxMssB15NTEBIN "NOx Tracking Stored 100 Hour System Out NOx Mass Bin 15 (NTE BIN) : Accumulated system out [SCR outlet] NOx mass while all NOx sensors are active over the prior 100 hour period for Bin 15 [Note Bin 15 is the Regen Bin]";
CM_ SG_ 2566590974 NOxTStd100HSstOtNOxMssB16RB "NOx Tracking Stored 100 Hour System Out NOx Mass Bin 16 (Regen Bin) : Accumulated system out [SCR outlet] NOx mass while all NOx sensors are active over the prior 100 hour period for Bin 16 [Note Bin 16 is the Regen Bin]";
CM_ SG_ 2566590974 NOxTStd100HSstOtNOxMssB17MILOB "NOx Tracking Stored 100 Hour System Out NOx Mass Bin 17 (MIL On Bin) : Accumulated system out [SCR outlet] NOx mass while all NOx sensors are active over the prior 100 hour period for Bin 17 [Note Bin 17 is the MIL On Bin]";
CM_ BO_ 2566591230 "NOx Tracking Active 100 Hour Fuel Consumption Bins ";
CM_ SG_ 2566591230 NOxTrkngAtv100HrFlCnsmptnBn1Ttl "NOx Tracking Active 100 Hour Fuel Consumption Bin 1 (Total): Accumulated Fuel consumption while all NOx sensors are active over the current 100 hour block for Bin 1 [Note Bin 1 is the total of Bins 2-14]";
CM_ SG_ 2566591230 NOxTrkngAtv100HrFlCnsmptnBn2 "NOx Tracking Active 100 Hour Fuel Consumption Bin 2 : Accumulated Fuel consumption while all NOx sensors are active over the current 100 hour block for Bin 2 [Note Bin 2 is the 'idle' bin]";
CM_ SG_ 2566591230 NOxTrkngAtv100HrFlCnsmptnBn3 "NOx Tracking Active 100 Hour Fuel Consumption Bin 3 : Accumulated Fuel consumption while all NOx sensors are active over the current 100 hour block for Bin 3.";
CM_ SG_ 2566591230 NOxTrkngAtv100HrFlCnsmptnBn4 "NOx Tracking Active 100 Hour Fuel Consumption Bin 4: Accumulated Fuel consumption while all NOx sensors are active over the current 100 hour block for Bin 4.";
CM_ SG_ 2566591230 NOxTrkngAtv100HrFlCnsmptnBn5 "NOx Tracking Active 100 Hour Fuel Consumption Bin 5: Accumulated Fuel consumption while all NOx sensors are active over the current 100 hour block for Bin 5.";
CM_ SG_ 2566591230 NOxTrkngAtv100HrFlCnsmptnBn6 "NOx Tracking Active 100 Hour Fuel Consumption Bin 6: Accumulated Fuel consumption while all NOx sensors are active over the current 100 hour block for Bin 6. ";
CM_ SG_ 2566591230 NOxTrkngAtv100HrFlCnsmptnBn7 "NOx Tracking Active 100 Hour Fuel Consumption Bin 7: Accumulated Fuel consumption while all NOx sensors are active over the current 100 hour block for Bin 7. ";
CM_ SG_ 2566591230 NOxTrkngAtv100HrFlCnsmptnBn8 "NOx Tracking Active 100 Hour Fuel Consumption Bin 8: Accumulated Fuel consumption while all NOx sensors are active over the current 100 hour block for Bin 8. ";
CM_ SG_ 2566591230 NOxTrkngAtv100HrFlCnsmptnBn9 "NOx Tracking Active 100 Hour Fuel Consumption Bin 9: Accumulated Fuel consumption while all NOx sensors are active over the current 100 hour block for Bin 9";
CM_ SG_ 2566591230 NOxTrkngAtv100HrFlCnsmptnBn10 "NOx Tracking Active 100 Hour Fuel Consumption Bin 10: Accumulated Fuel consumption while all NOx sensors are active over the current 100 hour block for Bin 10";
CM_ SG_ 2566591230 NOxTrkngAtv100HrFlCnsmptnBn11 "NOx Tracking Active 100 Hour Fuel Consumption Bin 11: Accumulated Fuel consumption while all NOx sensors are active over the current 100 hour block for Bin 11";
CM_ SG_ 2566591230 NOxTrkngAtv100HrFlCnsmptnBn12 "NOx Tracking Active 100 Hour Fuel Consumption Bin 12: Accumulated Fuel consumption while all NOx sensors are active over the current 100 hour block for Bin 12";
CM_ SG_ 2566591230 NOxTrkngAtv100HrFlCnsmptnBn13 "NOx Tracking Active 100 Hour Fuel Consumption Bin 13: Accumulated Fuel consumption while all NOx sensors are active over the current 100 hour block for Bin 13";
CM_ SG_ 2566591230 NOxTrkngAtv100HrFlCnsmptnBn14 "NOx Tracking Active 100 Hour Fuel Consumption Bin 14 : Accumulated Fuel consumption while all NOx sensors are active over the current 100 hour block for Bin 14";
CM_ SG_ 2566591230 NOxTAtv100HFCsptB15NTEBIN "NOx Tracking Active 100 Hour Fuel Consumption Bin 15 (NTE BIN) : Accumulated Fuel consumption while all NOx sensors are active over the current 100 hour block for Bin 15 [Note Bin 15 is the NTE Bin]";
CM_ SG_ 2566591230 NOxTAtv100HFCsptB16RB "NOx Tracking Active 100 Hour Fuel Consumption Bin 16 (Regen Bin) : Accumulated Fuel consumption while all NOx sensors are active over the current 100 hour block for Bin 16 [Note Bin 16 is the Regen Bin]";
CM_ SG_ 2566591230 NOxTAtv100HFCsptB17MILOB "NOx Tracking Active 100 Hour Fuel Consumption Bin 17 (MIL On Bin) : Accumulated Fuel consumption while all NOx sensors are active over the current 100 hour block for Bin 17 [Note Bin 17 is the Mil On Bin]";
CM_ BO_ 2566591486 "NOx Tracking Active 100 Hour Engine Run Time Bins ";
CM_ SG_ 2566591486 NOxTrkngAtv100HrEngnRnTmBn1Ttl "NOx Tracking Active 100 Hour Engine Run Time Bin 1 (Total): Accumulated Engine run time while all NOx sensors are active over the current 100 hour block for Bin 1 [Note Bin 1 is the total of Bins 2-14]";
CM_ SG_ 2566591486 NOxTrkngAtv100HrEngnRnTmBn2 "NOx Tracking Active 100 Hour Engine Run Time Bin 2 : Accumulated Engine run time while all NOx sensors are active over the current 100 hour block for Bin 2 [Note Bin 2 is the 'idle' bin]";
CM_ SG_ 2566591486 NOxTrkngAtv100HrEngnRnTmBn3 "NOx Tracking Active 100 Hour Engine Run Time Bin 3 : Accumulated Engine run time while all NOx sensors are active over the current 100 hour block for Bin 3. ";
CM_ SG_ 2566591486 NOxTrkngAtv100HrEngnRnTmBn4 "NOx Tracking Active 100 Hour Engine Run Time Bin 4: Accumulated Engine run time while all NOx sensors are active over the current 100 hour block for Bin 4. ";
CM_ SG_ 2566591486 NOxTrkngAtv100HrEngnRnTmBn5 "NOx Tracking Active 100 Hour Engine Run Time Bin 5: Accumulated Engine run time while all NOx sensors are active over the current 100 hour block for Bin 5.";
CM_ SG_ 2566591486 NOxTrkngAtv100HrEngnRnTmBn6 "NOx Tracking Active 100 Hour Engine Run Time Bin 6: Accumulated Engine run time while all NOx sensors are active over the current 100 hour block for Bin 6. ";
CM_ SG_ 2566591486 NOxTrkngAtv100HrEngnRnTmBn7 "NOx Tracking Active 100 Hour Engine Run Time Bin 7: Accumulated Engine run time while all NOx sensors are active over the current 100 hour block for Bin 7. ";
CM_ SG_ 2566591486 NOxTrkngAtv100HrEngnRnTmBn8 "NOx Tracking Active 100 Hour Engine Run Time Bin 8: Accumulated Engine run time while all NOx sensors are active over the current 100 hour block for Bin 8. ";
CM_ SG_ 2566591486 NOxTrkngAtv100HrEngnRnTmBn9 "NOx Tracking Active 100 Hour Engine Run Time Bin 9: Accumulated Engine run time while all NOx sensors are active over the current 100 hour block for Bin 9";
CM_ SG_ 2566591486 NOxTrkngAtv100HrEngnRnTmBn10 "NOx Tracking Active 100 Hour Engine Run Time Bin 10: Accumulated Engine run time while all NOx sensors are active over the current 100 hour block for Bin 10";
CM_ SG_ 2566591486 NOxTrkngAtv100HrEngnRnTmBn11 "NOx Tracking Active 100 Hour Engine Run Time Bin 11: Accumulated Engine run time while all NOx sensors are active over the current 100 hour block for Bin 11";
CM_ SG_ 2566591486 NOxTrkngAtv100HrEngnRnTmBn12 "NOx Tracking Active 100 Hour Engine Run Time Bin 12: Accumulated Engine run time while all NOx sensors are active over the current 100 hour block for Bin 12";
CM_ SG_ 2566591486 NOxTrkngAtv100HrEngnRnTmBn13 "NOx Tracking Active 100 Hour Engine Run Time Bin 13: Accumulated Engine run time while all NOx sensors are active over the current 100 hour block for Bin 13";
CM_ SG_ 2566591486 NOxTrkngAtv100HrEngnRnTmBn14 "NOx Tracking Active 100 Hour Engine Run Time Bin 14 : Accumulated Engine run time while all NOx sensors are active over the current 100 hour block for Bin 14";
CM_ SG_ 2566591486 NOxTAtv100HERTB15NTEBIN "NOx Tracking Active 100 Hour Engine Run Time Bin 15 (NTE BIN) : Accumulated Engine run time while all NOx sensors are active over the current 100 hour block for Bin 15 [Note Bin 15 is the NTE Bin]";
CM_ SG_ 2566591486 NOxTAtv100HERTB16RB "NOx Tracking Active 100 Hour Engine Run Time Bin 16 (Regen Bin) : Accumulated Engine run time while all NOx sensors are active over the current 100 hour block for Bin 16 [Note Bin 16 is the Regen Bin]";
CM_ SG_ 2566591486 NOxTAtv100HERTB17MILOB "NOx Tracking Active 100 Hour Engine Run Time Bin 17 (MIL On Bin) : Accumulated Engine run time while all NOx sensors are active over the current 100 hour block for Bin 17 [Note Bin 17 is the MIL On Bin]";
CM_ BO_ 2566591742 "NOx Tracking Active 100 Hour Vehicle Distance Bins ";
CM_ SG_ 2566591742 NOxTrkngAtv100HrVhlDstnBn1Ttl "NOx Tracking Active 100 Hour Vehicle Distance Bin 1 (Total): Accumulated Vehicle distance while all NOx sensors are active over the current 100 hour block for Bin 1 [Note Bin 1 is the total of Bins 2-14]";
CM_ SG_ 2566591742 NOxTrkngAtv100HrVhlDstnBn2 "NOx Tracking Active 100 Hour Vehicle Distance Bin 2 : Accumulated Vehicle distance while all NOx sensors are active over the current 100 hour block for Bin 2 [Note Bin 2 is the 'idle' bin]";
CM_ SG_ 2566591742 NOxTrkngAtv100HrVhlDstnBn3 "NOx Tracking Active 100 Hour Vehicle Distance Bin 3 : Accumulated Vehicle distance while all NOx sensors are active over the current 100 hour block for Bin 3.";
CM_ SG_ 2566591742 NOxTrkngAtv100HrVhlDstnBn4 "NOx Tracking Active 100 Hour Vehicle Distance Bin 4: Accumulated Vehicle distance while all NOx sensors are active over the current 100 hour block for Bin 4. ";
CM_ SG_ 2566591742 NOxTrkngAtv100HrVhlDstnBn5 "NOx Tracking Active 100 Hour Vehicle Distance Bin 5: Accumulated Vehicle distance while all NOx sensors are active over the current 100 hour block for Bin 5.";
CM_ SG_ 2566591742 NOxTrkngAtv100HrVhlDstnBn6 "NOx Tracking Active 100 Hour Vehicle Distance Bin 6: Accumulated Vehicle distance while all NOx sensors are active over the current 100 hour block for Bin 6. ";
CM_ SG_ 2566591742 NOxTrkngAtv100HrVhlDstnBn7 "NOx Tracking Active 100 Hour Vehicle Distance Bin 7: Accumulated Vehicle distance while all NOx sensors are active over the current 100 hour block for Bin 7. ";
CM_ SG_ 2566591742 NOxTrkngAtv100HrVhlDstnBn8 "NOx Tracking Active 100 Hour Vehicle Distance Bin 8: Accumulated Vehicle distance while all NOx sensors are active over the current 100 hour block for Bin 8. ";
CM_ SG_ 2566591742 NOxTrkngAtv100HrVhlDstnBn9 "NOx Tracking Active 100 Hour Vehicle Distance Bin 9: Accumulated Vehicle distance while all NOx sensors are active over the current 100 hour block for Bin 9";
CM_ SG_ 2566591742 NOxTrkngAtv100HrVhlDstnBn10 "NOx Tracking Active 100 Hour Vehicle Distance Bin 10: Accumulated Vehicle distance while all NOx sensors are active over the current 100 hour block for Bin 10";
CM_ SG_ 2566591742 NOxTrkngAtv100HrVhlDstnBn11 "NOx Tracking Active 100 Hour Vehicle Distance Bin 11: Accumulated Vehicle distance while all NOx sensors are active over the current 100 hour block for Bin 11";
CM_ SG_ 2566591742 NOxTrkngAtv100HrVhlDstnBn12 "NOx Tracking Active 100 Hour Vehicle Distance Bin 12: Accumulated Vehicle distance while all NOx sensors are active over the current 100 hour block for Bin 12";
CM_ SG_ 2566591742 NOxTrkngAtv100HrVhlDstnBn13 "NOx Tracking Active 100 Hour Vehicle Distance Bin 13: Accumulated Vehicle distance while all NOx sensors are active over the current 100 hour block for Bin 13";
CM_ SG_ 2566591742 NOxTrkngAtv100HrVhlDstnBn14 "NOx Tracking Active 100 Hour Vehicle Distance Bin 14 : Accumulated Vehicle distance while all NOx sensors are active over the current 100 hour block for Bin 14";
CM_ SG_ 2566591742 NOxTAtv100HVDstB15NTEBIN "NOx Tracking Active 100 Hour Vehicle Distance Bin 15 (NTE BIN) : Accumulated Vehicle distance while all NOx sensors are active over the current 100 hour block for Bin 15 [Note Bin 15 is the NTE Bin]";
CM_ SG_ 2566591742 NOxTAtv100HVDstB16RB "NOx Tracking Active 100 Hour Vehicle Distance Bin 16 (Regen Bin) : Accumulated Vehicle distance while all NOx sensors are active over the current 100 hour block for Bin 16 [Note Bin 16 is the Regen Bin]";
CM_ SG_ 2566591742 NOxTAtv100HVDstB17MILOB "NOx Tracking Active 100 Hour Vehicle Distance Bin 17 (MIL On Bin) : Accumulated Vehicle distance while all NOx sensors are active over the current 100 hour block for Bin 17 [Note Bin 17 is the Mil On Bin]";
CM_ BO_ 2566591998 "NOx Tracking Active 100 Hour Engine Output Energy Bins ";
CM_ SG_ 2566591998 NOxTAtv100HEOtptEB1Tt "NOx Tracking Active 100 Hour Engine Output Energy Bin 1 (Total): Accumulated Engine output energy while all NOx sensors are active over the current 100 hour block for Bin 1 [Note Bin 1 is the total of Bins 2-14]";
CM_ SG_ 2566591998 NOxTrkngAtv100HrEngnOtptEnrgBn2 "NOx Tracking Active 100 Hour Engine Output Energy Bin 2 : Accumulated Engine output energy while all NOx sensors are active over the current 100 hour block for Bin 2 [Note Bin 2 is the 'idle' bin]";
CM_ SG_ 2566591998 NOxTrkngAtv100HrEngnOtptEnrgBn3 "NOx Tracking Active 100 Hour Engine Output Energy Bin 3 : Accumulated Engine output energy while all NOx sensors are active over the current 100 hour block for Bin 3. ";
CM_ SG_ 2566591998 NOxTrkngAtv100HrEngnOtptEnrgBn4 "NOx Tracking Active 100 Hour Engine Output Energy Bin 4: Accumulated Engine output energy while all NOx sensors are active over the current 100 hour block for Bin 4.";
CM_ SG_ 2566591998 NOxTrkngAtv100HrEngnOtptEnrgBn5 "NOx Tracking Active 100 Hour Engine Output Energy Bin 5: Accumulated Engine output energy while all NOx sensors are active over the current 100 hour block for Bin 5.";
CM_ SG_ 2566591998 NOxTrkngAtv100HrEngnOtptEnrgBn6 "NOx Tracking Active 100 Hour Engine Output Energy Bin 6: Accumulated Engine output energy while all NOx sensors are active over the current 100 hour block for Bin 6. ";
CM_ SG_ 2566591998 NOxTrkngAtv100HrEngnOtptEnrgBn7 "NOx Tracking Active 100 Hour Engine Output Energy Bin 7: Accumulated Engine output energy while all NOx sensors are active over the current 100 hour block for Bin 7. ";
CM_ SG_ 2566591998 NOxTrkngAtv100HrEngnOtptEnrgBn8 "NOx Tracking Active 100 Hour Engine Output Energy Bin 8: Accumulated Engine output energy while all NOx sensors are active over the current 100 hour block for Bin 8. ";
CM_ SG_ 2566591998 NOxTrkngAtv100HrEngnOtptEnrgBn9 "NOx Tracking Active 100 Hour Engine Output Energy Bin 9: Accumulated Engine output energy while all NOx sensors are active over the current 100 hour block for Bin 9";
CM_ SG_ 2566591998 NOxTAtv100HEOtptEB10 "NOx Tracking Active 100 Hour Engine Output Energy Bin 10: Accumulated Engine output energy while all NOx sensors are active over the current 100 hour block for Bin 10";
CM_ SG_ 2566591998 NOxTAtv100HEOtptEB11 "NOx Tracking Active 100 Hour Engine Output Energy Bin 11: Accumulated Engine output energy while all NOx sensors are active over the current 100 hour block for Bin 11";
CM_ SG_ 2566591998 NOxTAtv100HEOtptEB12 "NOx Tracking Active 100 Hour Engine Output Energy Bin 12: Accumulated Engine output energy while all NOx sensors are active over the current 100 hour block for Bin 12";
CM_ SG_ 2566591998 NOxTAtv100HEOtptEB13 "NOx Tracking Active 100 Hour Engine Output Energy Bin 13: Accumulated Engine output energy while all NOx sensors are active over the current 100 hour block for Bin 13";
CM_ SG_ 2566591998 NOxTAtv100HEOtptEB14 "NOx Tracking Active 100 Hour Engine Output Energy Bin 14 : Accumulated Engine output energy while all NOx sensors are active over the current 100 hour block for Bin 14";
CM_ SG_ 2566591998 NOxTAtv100HEOtptEB15NTEBIN "NOx Tracking Active 100 Hour Engine Output Energy Bin 15 (NTE BIN) : Accumulated Engine output energy while all NOx sensors are active over the current 100 hour block for Bin 15 [Note Bin 15 is the NTE Bin]";
CM_ SG_ 2566591998 NOxTAtv100HEOtptEB16RB "NOx Tracking Active 100 Hour Engine Output Energy Bin 16 (Regen Bin) : Accumulated Engine output energy while all NOx sensors are active over the current 100 hour block for Bin 16 [Note Bin 16 is the Regen Bin]";
CM_ SG_ 2566591998 NOxTAtv100HEOtptEB17MILOB "NOx Tracking Active 100 Hour Engine Output Energy Bin 17 (MIL On Bin) : Accumulated Engine output energy while all NOx sensors are active over the current 100 hour block for Bin 17 [Note Bin 17 is the MIL On Bin]";
CM_ BO_ 2566592254 "NOx Tracking Active 100 Hour Engine Out NOx Mass Bins ";
CM_ SG_ 2566592254 NOxTAtv100HEOtNOxMssB1Tt "NOx Tracking Active 100 Hour Engine Out NOx Mass Bin 1 (Total): Accumulated Engine out NOx mass while all NOx sensors are active over the current 100 hour block for Bin 1 [Note Bin 1 is the total of Bins 2-14]";
CM_ SG_ 2566592254 NOxTrkngAtv100HrEngnOtNOxMssBn2 "NOx Tracking Active 100 Hour Engine Out NOx Mass Bin 2 : Accumulated Engine out NOx mass while all NOx sensors are active over the current 100 hour block for Bin 2 [Note Bin 2 is the 'idle' bin]";
CM_ SG_ 2566592254 NOxTrkngAtv100HrEngnOtNOxMssBn3 "NOx Tracking Active 100 Hour Engine Out NOx Mass Bin 3 : Accumulated Engine out NOx mass while all NOx sensors are active over the current 100 hour block for Bin 3. ";
CM_ SG_ 2566592254 NOxTrkngAtv100HrEngnOtNOxMssBn4 "NOx Tracking Active 100 Hour Engine Out NOx Mass Bin 4: Accumulated Engine out NOx mass while all NOx sensors are active over the current 100 hour block for Bin 4.";
CM_ SG_ 2566592254 NOxTrkngAtv100HrEngnOtNOxMssBn5 "NOx Tracking Active 100 Hour Engine Out NOx Mass Bin 5: Accumulated Engine out NOx mass while all NOx sensors are active over the current 100 hour block for Bin 5.";
CM_ SG_ 2566592254 NOxTrkngAtv100HrEngnOtNOxMssBn6 "NOx Tracking Active 100 Hour Engine Out NOx Mass Bin 6: Accumulated Engine out NOx mass while all NOx sensors are active over the current 100 hour block for Bin 6. ";
CM_ SG_ 2566592254 NOxTrkngAtv100HrEngnOtNOxMssBn7 "NOx Tracking Active 100 Hour Engine Out NOx Mass Bin 7: Accumulated Engine out NOx mass while all NOx sensors are active over the current 100 hour block for Bin 7. ";
CM_ SG_ 2566592254 NOxTrkngAtv100HrEngnOtNOxMssBn8 "NOx Tracking Active 100 Hour Engine Out NOx Mass Bin 8: Accumulated Engine out NOx mass while all NOx sensors are active over the current 100 hour block for Bin 8. ";
CM_ SG_ 2566592254 NOxTrkngAtv100HrEngnOtNOxMssBn9 "NOx Tracking Active 100 Hour Engine Out NOx Mass Bin 9: Accumulated Engine out NOx mass while all NOx sensors are active over the current 100 hour block for Bin 9";
CM_ SG_ 2566592254 NOxTAtv100HEOtNOxMssB10 "NOx Tracking Active 100 Hour Engine Out NOx Mass Bin 10: Accumulated Engine out NOx mass while all NOx sensors are active over the current 100 hour block for Bin 10";
CM_ SG_ 2566592254 NOxTAtv100HEOtNOxMssB11 "NOx Tracking Active 100 Hour Engine Out NOx Mass Bin 11: Accumulated Engine out NOx mass while all NOx sensors are active over the current 100 hour block for Bin 11";
CM_ SG_ 2566592254 NOxTAtv100HEOtNOxMssB12 "NOx Tracking Active 100 Hour Engine Out NOx Mass Bin 12: Accumulated Engine out NOx mass while all NOx sensors are active over the current 100 hour block for Bin 12";
CM_ SG_ 2566592254 NOxTAtv100HEOtNOxMssB13 "NOx Tracking Active 100 Hour Engine Out NOx Mass Bin 13: Accumulated Engine out NOx mass while all NOx sensors are active over the current 100 hour block for Bin 13";
CM_ SG_ 2566592254 NOxTAtv100HEOtNOxMssB14 "NOx Tracking Active 100 Hour Engine Out NOx Mass Bin 14 : Accumulated Engine out NOx mass while all NOx sensors are active over the current 100 hour block for Bin 14";
CM_ SG_ 2566592254 NOxTAtv100HEOtNOxMssB15NTEBIN "NOx Tracking Active 100 Hour Engine Out NOx Mass Bin 15 (NTE BIN) : Accumulated Engine out NOx mass while all NOx sensors are active over the current 100 hour block for Bin 15 [Note Bin 15 is the NTE Bin]";
CM_ SG_ 2566592254 NOxTAtv100HEOtNOxMssB16RB "NOx Tracking Active 100 Hour Engine Out NOx Mass Bin 16 (Regen Bin) : Accumulated Engine out NOx mass while all NOx sensors are active over the current 100 hour block for Bin 16 [Note Bin 16 is the Regen Bin]";
CM_ SG_ 2566592254 NOxTAtv100HEOtNOxMssB17MILOB "NOx Tracking Active 100 Hour Engine Out NOx Mass Bin 17 (MIL On Bin) : Accumulated Engine out NOx mass while all NOx sensors are active over the current 100 hour block for Bin 17 [Note Bin 17 the Mil On Bin]";
CM_ BO_ 2566592510 "NOx Tracking Active 100 Hour System Out NOx Mass Bins ";
CM_ SG_ 2566592510 NOxTAtv100HSstOtNOxMssB1Tt "NOx Tracking Active 100 Hour System Out NOx Mass Bin 1 (Total): Accumulated system out [SCR outlet] NOx mass while all NOx sensors are active over the current 100 hour block for Bin 1 [Note Bin 1 is the total of Bins 2-14]";
CM_ SG_ 2566592510 NOxTrkngAtv100HrSstmOtNOxMssBn2 "NOx Tracking Active 100 Hour System Out NOx Mass Bin 2 : Accumulated system out [SCR outlet] NOx mass while all NOx sensors are active over the current 100 hour block for Bin 2 [Note Bin 2 is the 'idle' bin]";
CM_ SG_ 2566592510 NOxTrkngAtv100HrSstmOtNOxMssBn3 "NOx Tracking Active 100 Hour System Out NOx Mass Bin 3 : Accumulated system out [SCR outlet] NOx mass while all NOx sensors are active over the current 100 hour block for Bin 3.";
CM_ SG_ 2566592510 NOxTrkngAtv100HrSstmOtNOxMssBn4 "NOx Tracking Active 100 Hour System Out NOx Mass Bin 4: Accumulated system out [SCR outlet] NOx mass while all NOx sensors are active over the current 100 hour block for Bin 4.";
CM_ SG_ 2566592510 NOxTrkngAtv100HrSstmOtNOxMssBn5 "NOx Tracking Active 100 Hour System Out NOx Mass Bin 5: Accumulated system out [SCR outlet] NOx mass while all NOx sensors are active over the current 100 hour block for Bin 5.";
CM_ SG_ 2566592510 NOxTrkngAtv100HrSstmOtNOxMssBn6 "NOx Tracking Active 100 Hour System Out NOx Mass Bin 6: Accumulated system out [SCR outlet] NOx mass while all NOx sensors are active over the current 100 hour block for Bin 6. ";
CM_ SG_ 2566592510 NOxTrkngAtv100HrSstmOtNOxMssBn7 "NOx Tracking Active 100 Hour System Out NOx Mass Bin 7: Accumulated system out [SCR outlet] NOx mass while all NOx sensors are active over the current 100 hour block for Bin 7. ";
CM_ SG_ 2566592510 NOxTrkngAtv100HrSstmOtNOxMssBn8 "NOx Tracking Active 100 Hour System Out NOx Mass Bin 8: Accumulated system out [SCR outlet] NOx mass while all NOx sensors are active over the current 100 hour block for Bin 8. ";
CM_ SG_ 2566592510 NOxTrkngAtv100HrSstmOtNOxMssBn9 "NOx Tracking Active 100 Hour System Out NOx Mass Bin 9: Accumulated system out [SCR outlet] NOx mass while all NOx sensors are active over the current 100 hour block for Bin 9";
CM_ SG_ 2566592510 NOxTAtv100HSstOtNOxMssB10 "NOx Tracking Active 100 Hour System Out NOx Mass Bin 10: Accumulated system out [SCR outlet] NOx mass while all NOx sensors are active over the current 100 hour block for Bin 10 ";
CM_ SG_ 2566592510 NOxTAtv100HSstOtNOxMssB11 "NOx Tracking Active 100 Hour System Out NOx Mass Bin 11: Accumulated system out [SCR outlet] NOx mass while all NOx sensors are active over the current 100 hour block for Bin 11";
CM_ SG_ 2566592510 NOxTAtv100HSstOtNOxMssB12 "NOx Tracking Active 100 Hour System Out NOx Mass Bin 12: Accumulated system out [SCR outlet] NOx mass while all NOx sensors are active over the current 100 hour block for Bin 12";
CM_ SG_ 2566592510 NOxTAtv100HSstOtNOxMssB13 "NOx Tracking Active 100 Hour System Out NOx Mass Bin 13: Accumulated system out [SCR outlet] NOx mass while all NOx sensors are active over the current 100 hour block for Bin 13";
CM_ SG_ 2566592510 NOxTAtv100HSstOtNOxMssB14 "NOx Tracking Active 100 Hour System Out NOx Mass Bin 14 : Accumulated system out [SCR outlet] NOx mass while all NOx sensors are active over the current 100 hour block for Bin 14";
CM_ SG_ 2566592510 NOxTAtv100HSstOtNOxMssB15NTEBIN "NOx Tracking Active 100 Hour System Out NOx Mass Bin 15 (NTE BIN) : Accumulated system out [SCR outlet] NOx mass while all NOx sensors are active over the current 100 hour block for Bin 15 [Note Bin 15 is the Regen Bin]";
CM_ SG_ 2566592510 NOxTAtv100HSstOtNOxMssB16RB "NOx Tracking Active 100 Hour System Out NOx Mass Bin 16 (Regen Bin) : Accumulated system out [SCR outlet] NOx mass while all NOx sensors are active over the current 100 hour block for Bin 16 [Note Bin 16 is the Regen Bin]";
CM_ SG_ 2566592510 NOxTAtv100HSstOtNOxMssB17MILOB "NOx Tracking Active 100 Hour System Out NOx Mass Bin 17 (MIL On Bin) : Accumulated system out [SCR outlet] NOx mass while all NOx sensors are active over the current 100 hour block for Bin 17 [Note Bin 17 is the MIL On Bin]";
CM_ BO_ 2365266174 "Motor/Generator 6 Inverter Control 2";
CM_ SG_ 2365266174 MtrGnrtr6InvrtrRtLmtsRqst2CRC "Motor/Generator 6 Inverter Rate Limits Request 2 CRC: The CRC is defined as follows:• Length: 8 bits• Polynomial: x^8+x^5+x^3+x^2+x+1• Initial Value: FFh• Input Data Reflection: Not reflected• Result Data Reflection: Not reflected• XOR value: FFhSAE ...";
CM_ SG_ 2365266174 MtrGnrtr6InvrtrRtLmtsRqst2Cntr "Motor/Generator 6 Inverter Rate Limits Request 2 Counter: The message counter is used to detect situations where the transmitting ECU malfunction repeats the same frame all the time. The receiver of the information may use the counter parameter to de...";
CM_ SG_ 2365266174 MtrGnrtr6InvrtrPIDCntrlAppllMd "Motor/Generator 6 Inverter PID Control Applicable Mode : Defines the Mode that the PID Gain parameters apply for this instance of the inverter.  See SPN 12172 [Control Setpoint Mode] for a definition of modes for control purposes.Applicable modes:000...";
CM_ SG_ 2365266174 MtGt6IvtPIDCtNzdDtG "Motor/Generator 6 Inverter PID Control Normalized Differential Gain: A PID controller can be parametrized by factors Kp, Ki and Kd. This parameter defines the normalized integral gain (Kin) for control applications in this inverter instance. The norm...";
CM_ SG_ 2365266174 MtGt6IvtPIDCtNzdItG "Motor/Generator 6 Inverter PID Control Normalized Integral Gain: A PID controller can be parametrized by factors Kp, Ki and Kd. This parameter defines the normalized integral gain (Kin) for control applications in this inverter instance. The normaliz...";
CM_ SG_ 2365266174 MtGt6IvtPIDCtNzdPptG "Motor/Generator 6 Inverter PID Control Normalized Proportional Gain: A PID controller can be parametrized by factors Kp, Ki and Kd. This parameter defines the normalized proportional gain (Kpn) for control applications in this inverter instance. The ...";
CM_ SG_ 2365266174 MtGt6IvtPIDCtFdFwdTq "Motor/Generator 6 Inverter PID Control Feed-Forward Torque: A PID controller can have a Feed-Forward Torque added to its output. This parameter defines the Feed-Forward Torque Setpoint for control applications in this inverter instance. The Setpoint ...";
CM_ BO_ 2566593022 "Motor/Generator 6 Inverter Limits Request Power";
CM_ SG_ 2566593022 MtrGnrtr6InvrtrLmtsRqstPwrCRC "Motor/Generator 6 Inverter Limits Request Power CRC: The CRC is defined as follows:• Length: 8 bits• Polynomial: x^8+x^5+x^3+x^2+x+1• Initial Value: FFh• Input Data Reflection: Not reflected• Result Data Reflection: Not reflected• XOR value: FFhSAE m...";
CM_ SG_ 2566593022 MtrGnrtr6InvrtrLmtsRqstPwrCntr "Motor/Generator 6 Inverter Limits Request Power Counter: The message counter is used to detect situations where the transmitting ECU malfunction repeats the same frame all the time. The receiver of the information may use the counter parameter to det...";
CM_ SG_ 2566593022 MtGt6IvtLtsRqstMPwMx "Motor/Generator 6 Inverter Limits Request Mechanical Power Maximum: This requests a maximum limit for the mechanical power.Refer to SPN 12177 [Reference Power] to convert % to kW. Request a value of FBFh to instruct the inverter to use its default va...";
CM_ SG_ 2566593022 MtGt6IvtLtsRqstMPwM "Motor/Generator 6 Inverter Limits Request Mechanical Power Minimum: This requests a minimum limit for the mechanical power.Refer to SPN 12177 [Reference Power] to convert % to kW. Request a value of FBFh to instruct the inverter to use its default va...";
CM_ SG_ 2566593022 MtGt6IvtLtsRqstDCSdPwMx "Motor/Generator 6 Inverter Limits Request DC Side Power Maximum: This requests a maximum limit for the DC Side power.Refer to SPN 12177 [Reference Power] to convert % to kW. Request a value of FBFh to instruct the inverter to use its default values.F...";
CM_ SG_ 2566593022 MtGt6IvtLtsRqstDCSdPwM "Motor/Generator 6 Inverter Limits Request DC Side Power Minimum: This requests a minimum limit for the DC Side power.Refer to SPN 12177 [Reference Power] to convert % to kW. Request a value of FBFh to instruct the inverter to use its default values.F...";
BA_DEF_ SG_  "SPN" INT 0 524287;
BA_DEF_ BO_  "VFrameFormat" ENUM  "StandardCAN","ExtendedCAN","reserved","J1939PG";
BA_DEF_DEF_  "SPN" 0;
BA_DEF_DEF_  "VFrameFormat" "J1939PG";
BA_ "SPN" SG_ 2566574846 EngnTrhrgr3OlTmprtr 12889;
BA_ "SPN" SG_ 2566574846 EngnTrhrgr4OlTmprtr 12890;
BA_ "SPN" SG_ 2566574846 EngnTrhrgr5OlTmprtr 12891;
BA_ "SPN" SG_ 2566574846 EngnTrhrgr6OlTmprtr 12892;
BA_ "SPN" SG_ 2566575102 TSC1CntrlPrpsP7InhtCmmnd 12868;
BA_ "SPN" SG_ 2566575358 EVSE1ACRMSCurrent 12866;
BA_ "SPN" SG_ 2566575358 EVSE1ACRMSVoltage 12867;
BA_ "SPN" SG_ 2566575614 EVSEACRMSCurrentLimitL1 12865;
BA_ "SPN" SG_ 2566575614 EVSEACRMSCurrentLimitL2 13003;
BA_ "SPN" SG_ 2566575614 EVSEACRMSCurrentLimitL3 13004;
BA_ "SPN" SG_ 2566575614 EVSEACRMSCurrentLimitNeutral 13005;
BA_ "SPN" SG_ 2566575870 EVSE1ConnectorReleaseLatch 12861;
BA_ "SPN" SG_ 2566575870 EVSE1ManualOverride 12862;
BA_ "SPN" SG_ 2566575870 EVSE1ConnectorLockState 12863;
BA_ "SPN" SG_ 2566581758 TmprtrSnsngMdl1PrlmnrFMI 12820;
BA_ "SPN" SG_ 2566581758 TmprtrSnsngMdl2PrlmnrFMI 12821;
BA_ "SPN" SG_ 2566581758 TmprtrSnsngMdl3PrlmnrFMI 12822;
BA_ "SPN" SG_ 2566581758 TmprtrSnsngMdl4PrlmnrFMI 12823;
BA_ "SPN" SG_ 2566581758 TmprtrSnsngMdl5PrlmnrFMI 12824;
BA_ "SPN" SG_ 2566581758 TmprtrSnsngMdl6PrlmnrFMI 12825;
BA_ "SPN" SG_ 2566581758 TmprtrSnsngMdl7PrlmnrFMI 12826;
BA_ "SPN" SG_ 2566581758 TmprtrSnsngMdl8PrlmnrFMI 12827;
BA_ "SPN" SG_ 2566582014 TmprtrSnsngMdl9PrlmnrFMI 12828;
BA_ "SPN" SG_ 2566582014 TmprtrSnsngMdl10PrlmnrFMI 12829;
BA_ "SPN" SG_ 2566582014 TmprtrSnsngMdl11PrlmnrFMI 12830;
BA_ "SPN" SG_ 2566582014 TmprtrSnsngMdl12PrlmnrFMI 12831;
BA_ "SPN" SG_ 2566582014 TmprtrSnsngMdl13PrlmnrFMI 12832;
BA_ "SPN" SG_ 2566582014 TmprtrSnsngMdl14PrlmnrFMI 12833;
BA_ "SPN" SG_ 2566582014 TmprtrSnsngMdl15PrlmnrFMI 12834;
BA_ "SPN" SG_ 2566582014 TmprtrSnsngMdl16PrlmnrFMI 12835;
BA_ "SPN" SG_ 2566582270 Aftrtrtmnt2SCRNrmlzdCnvrsnEffn 12860;
BA_ "SPN" SG_ 2566582526 Aftrtrtmnt1SCRNrmlzdCnvrsnEffn 12859;
BA_ "SPN" SG_ 2566582782 HrdLftmPrplsnSstmAtvTm 12797;
BA_ "SPN" SG_ 2566582782 HrdLftmIdlPrplsnSstmAtvTm 12798;
BA_ "SPN" SG_ 2566582782 HrdLftmUrnPrplsnSstmAtvTm 12799;
BA_ "SPN" SG_ 2566583038 HrdStrd100HrRntPrplsnSstmAtvTm 12794;
BA_ "SPN" SG_ 2566583038 HrdStrd100HrIdlPrplsnSstmAtvTm 12795;
BA_ "SPN" SG_ 2566583038 HrdStrd100HrUrnPrplsnSstmAtvTm 12796;
BA_ "SPN" SG_ 2566583294 HrdAtv100HrPrplsnSstmAtvTm 12791;
BA_ "SPN" SG_ 2566583294 HrdAtv100HrIdlPrplsnSstmAtvTm 12792;
BA_ "SPN" SG_ 2566583294 HrdAtv100HrUrnPrplsnSstmAtvTm 12793;
BA_ "SPN" SG_ 2566583550 HdLtDstTvdCDptOptwtE 12783;
BA_ "SPN" SG_ 2566583550 HdLtDstTvdCDptOptwtER 12784;
BA_ "SPN" SG_ 2566583550 HdLtDstTvdDvStCIsOpt 12785;
BA_ "SPN" SG_ 2566583550 HrdLftmFlCnsmdnChrgDpltngOprtn 12786;
BA_ "SPN" SG_ 2566583550 HdLtFCsdDvStCIsOpt 12787;
BA_ "SPN" SG_ 2566583550 HdLtGdECsdCDptOptwtE 12788;
BA_ "SPN" SG_ 2566583550 HdLtGdECsdCDptOptwtER 12789;
BA_ "SPN" SG_ 2566583550 HrdLftmGrdEnrgntthBttr 12790;
BA_ "SPN" SG_ 2566583806 HdStd100HDstTvdCDptOptwtE 12775;
BA_ "SPN" SG_ 2566583806 HdStd100HDstTvdCDptOptwtER 12776;
BA_ "SPN" SG_ 2566583806 HdStd100HDstTvdDvStCIsOpt 12777;
BA_ "SPN" SG_ 2566583806 HdStd100HFCsdCDptOpt 12778;
BA_ "SPN" SG_ 2566583806 HdStd100HFCsdDvStCIsOpt 12779;
BA_ "SPN" SG_ 2566583806 HdStd100HGdECsdCDptOptwtE 12780;
BA_ "SPN" SG_ 2566583806 HdStd100HGdECsdCDptOptwtER 12781;
BA_ "SPN" SG_ 2566583806 HrdStrd100HrGrdEnrgntthBttr 12782;
BA_ "SPN" SG_ 2566584062 HdAtv100HDstTvdCDptOptwtE 12767;
BA_ "SPN" SG_ 2566584062 HdAtv100HDstTvdCDptOptwtER 12768;
BA_ "SPN" SG_ 2566584062 HdAtv100HDstTvdDvStCIsOpt 12769;
BA_ "SPN" SG_ 2566584062 HdAtv100HFCsdCDptOpt 12770;
BA_ "SPN" SG_ 2566584062 HdAtv100HFCsdDvStCIsOpt 12771;
BA_ "SPN" SG_ 2566584062 HdAtv100HGdECsdCDptOptwtE 12772;
BA_ "SPN" SG_ 2566584062 HdAtv100HGdECsdCDptOptwtER 12773;
BA_ "SPN" SG_ 2566584062 HrdAtv100HrGrdEnrgntthBttr 12774;
BA_ "SPN" SG_ 2566584318 Atttt1DPFRCptSttEVDst1 12759;
BA_ "SPN" SG_ 2566584318 Atttt1DPFRCptEdEVDst1 12760;
BA_ "SPN" SG_ 2566584318 Atttt1DPFRCptSttEVDst2 12761;
BA_ "SPN" SG_ 2566584318 Atttt1DPFRCptEdEVDst2 12762;
BA_ "SPN" SG_ 2566584318 Atttt1DPFRCptSttEVDst3 12763;
BA_ "SPN" SG_ 2566584318 Atttt1DPFRCptEdEVDst3 12764;
BA_ "SPN" SG_ 2566584318 Atttt1TtERtWtNDEFDv 12765;
BA_ "SPN" SG_ 2566584318 Atttt1TtTSCRItBw200Css 12766;
BA_ "SPN" SG_ 2566584830 Aftrtrtmnt1SCR2InltNOxMssFlw 12754;
BA_ "SPN" SG_ 2566584830 Aftrtrtmnt1SCR2OtltNOxMssFlw 12755;
BA_ "SPN" SG_ 2566584830 Aftrtrtmnt1SCR2MdldNH3StrgLvl 12756;
BA_ "SPN" SG_ 2566584830 Aftrtrtmnt1SCR2TrgtNH3StrgLvl 12757;
BA_ "SPN" SG_ 2566585086 Atttt1SCR1EExstNOxMssFw 12750;
BA_ "SPN" SG_ 2566585086 Aftrtrtmnt1SCR1TlppNOxMssFlw 12751;
BA_ "SPN" SG_ 2566585086 Aftrtrtmnt1SCR1MdldAtlStrgLvl 12752;
BA_ "SPN" SG_ 2566585086 Aftrtrtmnt1SCR1TrgtNH3StrgLvl 12753;
BA_ "SPN" SG_ 2566585342 EVAPSystemPurgePressure 12744;
BA_ "SPN" SG_ 2566585342 EVAPSystemVaporPressure 12745;
BA_ "SPN" SG_ 2566585342 EVAPSystemPurgeValveCommand 12746;
BA_ "SPN" SG_ 2566585342 EVAPSystemPurgeValvePosition 12747;
BA_ "SPN" SG_ 2566585598 GHGTrkngLftmEngnRnTm 12730;
BA_ "SPN" SG_ 2566585598 GHGTrkngLftmVhlDstn 12731;
BA_ "SPN" SG_ 2566585598 GHGTrkngLftmVhlFlCnsmptn 12732;
BA_ "SPN" SG_ 2566585598 GHGTrkngLftmEngnFlCnsmptn 12733;
BA_ "SPN" SG_ 2566585598 GHGTrkngLftmEngnOtptEnrg 12734;
BA_ "SPN" SG_ 2566585598 GHGTrkngLftmPstvKntEnrgNmrtr 12735;
BA_ "SPN" SG_ 2566585598 GHGTrkngLftmUrnSpdRnTm 12736;
BA_ "SPN" SG_ 2566585598 GHGTrackingLifetimeIdleRunTime 12737;
BA_ "SPN" SG_ 2566585598 GHGTrkngLftmEngnIdlFlCnsmptn 12738;
BA_ "SPN" SG_ 2566585598 GHGTrkngLftmEngnPwrTkOffRnTm 12739;
BA_ "SPN" SG_ 2566585598 GHGTLtEPwTOFCspt 12740;
BA_ "SPN" SG_ 2566585598 GHGTLtAttEStdwTAtvtCt 12741;
BA_ "SPN" SG_ 2566585598 GHGTrkngLftmStpStrtThnlgRnTm 12742;
BA_ "SPN" SG_ 2566585854 GHGTrkngStrd100HrEngnRnTm 12715;
BA_ "SPN" SG_ 2566585854 GHGTrkngStrd100HrVhlDstn 12716;
BA_ "SPN" SG_ 2566585854 GHGTrkngStrd100HrVhlFlCnsmptn 12717;
BA_ "SPN" SG_ 2566585854 GHGTrkngStrd100HrEngnFlCnsmptn 12718;
BA_ "SPN" SG_ 2566585854 GHGTrkngStrd100HrEngnOtptEnrg 12719;
BA_ "SPN" SG_ 2566585854 GHGTStd100HPstvKtENt 12720;
BA_ "SPN" SG_ 2566585854 GHGTrkngStrd100HrUrnSpdRnTm 12721;
BA_ "SPN" SG_ 2566585854 GHGTrkngStrd100HrIdlRnTm 12722;
BA_ "SPN" SG_ 2566585854 GHGTStd100HEIdFCspt 12723;
BA_ "SPN" SG_ 2566585854 GHGTStd100HEPwTORT 12724;
BA_ "SPN" SG_ 2566585854 GHGTStd100HEPwTOFCspt 12725;
BA_ "SPN" SG_ 2566585854 GHGTStd100HAttEStdwTAtvtCt 12726;
BA_ "SPN" SG_ 2566585854 GHGTStd100HStpSttTRT 12727;
BA_ "SPN" SG_ 2566586110 GHGTrkngAtv100HrEngnRnTm 12700;
BA_ "SPN" SG_ 2566586110 GHGTrkngAtv100HrVhlDstn 12701;
BA_ "SPN" SG_ 2566586110 GHGTrkngAtv100HrVhlFlCnsmptn 12702;
BA_ "SPN" SG_ 2566586110 GHGTrkngAtv100HrEngnFlCnsmptn 12703;
BA_ "SPN" SG_ 2566586110 GHGTrkngAtv100HrEngnOtptEnrg 12704;
BA_ "SPN" SG_ 2566586110 GHGTAtv100HPstvKtENt 12705;
BA_ "SPN" SG_ 2566586110 GHGTrkngAtv100HrUrnSpdRnTm 12706;
BA_ "SPN" SG_ 2566586110 GHGTrkngAtv100HrIdlRnTm 12707;
BA_ "SPN" SG_ 2566586110 GHGTAtv100HEIdFCspt 12708;
BA_ "SPN" SG_ 2566586110 GHGTAtv100HEPwTORT 12709;
BA_ "SPN" SG_ 2566586110 GHGTAtv100HEPwTOFCspt 12710;
BA_ "SPN" SG_ 2566586110 GHGTAtv100HAttEStdwTAtvtCt 12711;
BA_ "SPN" SG_ 2566586110 GHGTAtv100HStpSttTRT 12712;
BA_ "SPN" SG_ 2566587134 NOxTEAtvtLtFCsptB1Tt 12675;
BA_ "SPN" SG_ 2566587134 NOxTEAtvtLtFCsptB2 12676;
BA_ "SPN" SG_ 2566587134 NOxTEAtvtLtFCsptB3 12677;
BA_ "SPN" SG_ 2566587134 NOxTEAtvtLtFCsptB4 12678;
BA_ "SPN" SG_ 2566587134 NOxTEAtvtLtFCsptB5 12679;
BA_ "SPN" SG_ 2566587134 NOxTEAtvtLtFCsptB6 12680;
BA_ "SPN" SG_ 2566587134 NOxTEAtvtLtFCsptB7 12681;
BA_ "SPN" SG_ 2566587134 NOxTEAtvtLtFCsptB8 12682;
BA_ "SPN" SG_ 2566587134 NOxTEAtvtLtFCsptB9 12683;
BA_ "SPN" SG_ 2566587134 NOxTEAtvtLtFCsptB10 12684;
BA_ "SPN" SG_ 2566587134 NOxTEAtvtLtFCsptB11 12685;
BA_ "SPN" SG_ 2566587134 NOxTEAtvtLtFCsptB12 12686;
BA_ "SPN" SG_ 2566587134 NOxTEAtvtLtFCsptB13 12687;
BA_ "SPN" SG_ 2566587134 NOxTEAtvtLtFCsptB14 12688;
BA_ "SPN" SG_ 2566587134 NOxTEAtvtLtFCsptB15NTEBIN 12689;
BA_ "SPN" SG_ 2566587134 NOxTEAtvtLtFCsptB16RB 12690;
BA_ "SPN" SG_ 2566587134 NOxTEAtvtLtFCsptB17MILOB 12713;
BA_ "SPN" SG_ 2566587390 NOxTEAtvtLtERTB1Tt 12659;
BA_ "SPN" SG_ 2566587390 NOxTrkngEngnAtvtLftmEngnRnTmBn2 12660;
BA_ "SPN" SG_ 2566587390 NOxTrkngEngnAtvtLftmEngnRnTmBn3 12661;
BA_ "SPN" SG_ 2566587390 NOxTrkngEngnAtvtLftmEngnRnTmBn4 12662;
BA_ "SPN" SG_ 2566587390 NOxTrkngEngnAtvtLftmEngnRnTmBn5 12663;
BA_ "SPN" SG_ 2566587390 NOxTrkngEngnAtvtLftmEngnRnTmBn6 12664;
BA_ "SPN" SG_ 2566587390 NOxTrkngEngnAtvtLftmEngnRnTmBn7 12665;
BA_ "SPN" SG_ 2566587390 NOxTrkngEngnAtvtLftmEngnRnTmBn8 12666;
BA_ "SPN" SG_ 2566587390 NOxTrkngEngnAtvtLftmEngnRnTmBn9 12667;
BA_ "SPN" SG_ 2566587390 NOxTEAtvtLtERTB10 12668;
BA_ "SPN" SG_ 2566587390 NOxTEAtvtLtERTB11 12669;
BA_ "SPN" SG_ 2566587390 NOxTEAtvtLtERTB12 12670;
BA_ "SPN" SG_ 2566587390 NOxTEAtvtLtERTB13 12671;
BA_ "SPN" SG_ 2566587390 NOxTEAtvtLtERTB14 12672;
BA_ "SPN" SG_ 2566587390 NOxTEAtvtLtERTB15NTEBIN 12673;
BA_ "SPN" SG_ 2566587390 NOxTEAtvtLtERTB16RB 12674;
BA_ "SPN" SG_ 2566587390 NOxTEAtvtLtERTB17MILOB 12714;
BA_ "SPN" SG_ 2566587646 NOxTEAtvtLtVDstB1Tt 12643;
BA_ "SPN" SG_ 2566587646 NOxTrkngEngnAtvtLftmVhlDstnBn2 12644;
BA_ "SPN" SG_ 2566587646 NOxTrkngEngnAtvtLftmVhlDstnBn3 12645;
BA_ "SPN" SG_ 2566587646 NOxTrkngEngnAtvtLftmVhlDstnBn4 12646;
BA_ "SPN" SG_ 2566587646 NOxTrkngEngnAtvtLftmVhlDstnBn5 12647;
BA_ "SPN" SG_ 2566587646 NOxTrkngEngnAtvtLftmVhlDstnBn6 12648;
BA_ "SPN" SG_ 2566587646 NOxTrkngEngnAtvtLftmVhlDstnBn7 12649;
BA_ "SPN" SG_ 2566587646 NOxTrkngEngnAtvtLftmVhlDstnBn8 12650;
BA_ "SPN" SG_ 2566587646 NOxTrkngEngnAtvtLftmVhlDstnBn9 12651;
BA_ "SPN" SG_ 2566587646 NOxTrkngEngnAtvtLftmVhlDstnBn10 12652;
BA_ "SPN" SG_ 2566587646 NOxTrkngEngnAtvtLftmVhlDstnBn11 12653;
BA_ "SPN" SG_ 2566587646 NOxTrkngEngnAtvtLftmVhlDstnBn12 12654;
BA_ "SPN" SG_ 2566587646 NOxTrkngEngnAtvtLftmVhlDstnBn13 12655;
BA_ "SPN" SG_ 2566587646 NOxTrkngEngnAtvtLftmVhlDstnBn14 12656;
BA_ "SPN" SG_ 2566587646 NOxTEAtvtLtVDstB15NTEBIN 12657;
BA_ "SPN" SG_ 2566587646 NOxTEAtvtLtVDstB16RB 12658;
BA_ "SPN" SG_ 2566587646 NOxTEAtvtLtVDstB17MILOB 12728;
BA_ "SPN" SG_ 2566587902 NOxTEAtvtLtEOtptEB1Tt 12627;
BA_ "SPN" SG_ 2566587902 NOxTEAtvtLtEOtptEB2 12628;
BA_ "SPN" SG_ 2566587902 NOxTEAtvtLtEOtptEB3 12629;
BA_ "SPN" SG_ 2566587902 NOxTEAtvtLtEOtptEB4 12630;
BA_ "SPN" SG_ 2566587902 NOxTEAtvtLtEOtptEB5 12631;
BA_ "SPN" SG_ 2566587902 NOxTEAtvtLtEOtptEB6 12632;
BA_ "SPN" SG_ 2566587902 NOxTEAtvtLtEOtptEB7 12633;
BA_ "SPN" SG_ 2566587902 NOxTEAtvtLtEOtptEB8 12634;
BA_ "SPN" SG_ 2566587902 NOxTEAtvtLtEOtptEB9 12635;
BA_ "SPN" SG_ 2566587902 NOxTEAtvtLtEOtptEB10 12636;
BA_ "SPN" SG_ 2566587902 NOxTEAtvtLtEOtptEB11 12637;
BA_ "SPN" SG_ 2566587902 NOxTEAtvtLtEOtptEB12 12638;
BA_ "SPN" SG_ 2566587902 NOxTEAtvtLtEOtptEB13 12639;
BA_ "SPN" SG_ 2566587902 NOxTEAtvtLtEOtptEB14 12640;
BA_ "SPN" SG_ 2566587902 NOxTEAtvtLtEOtptEB15NTEBIN 12641;
BA_ "SPN" SG_ 2566587902 NOxTEAtvtLtEOtptEB16RB 12642;
BA_ "SPN" SG_ 2566587902 NOxTEAtvtLtEOtptEB17MILOB 12729;
BA_ "SPN" SG_ 2566588158 NOxTVdNOxLtFCsptB1Tt 12610;
BA_ "SPN" SG_ 2566588158 NOxTrkngVldNOxLftmFlCnsmptnBn2 12611;
BA_ "SPN" SG_ 2566588158 NOxTrkngVldNOxLftmFlCnsmptnBn3 12612;
BA_ "SPN" SG_ 2566588158 NOxTrkngVldNOxLftmFlCnsmptnBn4 12613;
BA_ "SPN" SG_ 2566588158 NOxTrkngVldNOxLftmFlCnsmptnBn5 12614;
BA_ "SPN" SG_ 2566588158 NOxTrkngVldNOxLftmFlCnsmptnBn6 12615;
BA_ "SPN" SG_ 2566588158 NOxTrkngVldNOxLftmFlCnsmptnBn7 12616;
BA_ "SPN" SG_ 2566588158 NOxTrkngVldNOxLftmFlCnsmptnBn8 12617;
BA_ "SPN" SG_ 2566588158 NOxTrkngVldNOxLftmFlCnsmptnBn9 12618;
BA_ "SPN" SG_ 2566588158 NOxTrkngVldNOxLftmFlCnsmptnBn10 12619;
BA_ "SPN" SG_ 2566588158 NOxTrkngVldNOxLftmFlCnsmptnBn11 12620;
BA_ "SPN" SG_ 2566588158 NOxTrkngVldNOxLftmFlCnsmptnBn12 12621;
BA_ "SPN" SG_ 2566588158 NOxTrkngVldNOxLftmFlCnsmptnBn13 12622;
BA_ "SPN" SG_ 2566588158 NOxTrkngVldNOxLftmFlCnsmptnBn14 12623;
BA_ "SPN" SG_ 2566588158 NOxTVdNOxLtFCsptB15NTEBIN 12624;
BA_ "SPN" SG_ 2566588158 NOxTVdNOxLtFCsptB16RB 12625;
BA_ "SPN" SG_ 2566588158 NOxTVdNOxLtFCsptB17MILOB 12626;
BA_ "SPN" SG_ 2566588414 NOxTVdNOxLtERTB1Tt 12593;
BA_ "SPN" SG_ 2566588414 NOxTrkngVldNOxLftmEngnRnTmBn2 12594;
BA_ "SPN" SG_ 2566588414 NOxTrkngVldNOxLftmEngnRnTmBn3 12595;
BA_ "SPN" SG_ 2566588414 NOxTrkngVldNOxLftmEngnRnTmBn4 12596;
BA_ "SPN" SG_ 2566588414 NOxTrkngVldNOxLftmEngnRnTmBn5 12597;
BA_ "SPN" SG_ 2566588414 NOxTrkngVldNOxLftmEngnRnTmBn6 12598;
BA_ "SPN" SG_ 2566588414 NOxTrkngVldNOxLftmEngnRnTmBn7 12599;
BA_ "SPN" SG_ 2566588414 NOxTrkngVldNOxLftmEngnRnTmBn8 12600;
BA_ "SPN" SG_ 2566588414 NOxTrkngVldNOxLftmEngnRnTmBn9 12601;
BA_ "SPN" SG_ 2566588414 NOxTrkngVldNOxLftmEngnRnTmBn10 12602;
BA_ "SPN" SG_ 2566588414 NOxTrkngVldNOxLftmEngnRnTmBn11 12603;
BA_ "SPN" SG_ 2566588414 NOxTrkngVldNOxLftmEngnRnTmBn12 12604;
BA_ "SPN" SG_ 2566588414 NOxTrkngVldNOxLftmEngnRnTmBn13 12605;
BA_ "SPN" SG_ 2566588414 NOxTrkngVldNOxLftmEngnRnTmBn14 12606;
BA_ "SPN" SG_ 2566588414 NOxTVdNOxLtERTB15NTEBIN 12607;
BA_ "SPN" SG_ 2566588414 NOxTVdNOxLtERTB16RB 12608;
BA_ "SPN" SG_ 2566588414 NOxTVdNOxLtERTB17MILOB 12609;
BA_ "SPN" SG_ 2566588670 NOxTrkngVldNOxLftmVhlDstnBn1Ttl 12576;
BA_ "SPN" SG_ 2566588670 NOxTrkngVldNOxLftmVhlDstnBn2 12577;
BA_ "SPN" SG_ 2566588670 NOxTrkngVldNOxLftmVhlDstnBn3 12578;
BA_ "SPN" SG_ 2566588670 NOxTrkngVldNOxLftmVhlDstnBn4 12579;
BA_ "SPN" SG_ 2566588670 NOxTrkngVldNOxLftmVhlDstnBn5 12580;
BA_ "SPN" SG_ 2566588670 NOxTrkngVldNOxLftmVhlDstnBn6 12581;
BA_ "SPN" SG_ 2566588670 NOxTrkngVldNOxLftmVhlDstnBn7 12582;
BA_ "SPN" SG_ 2566588670 NOxTrkngVldNOxLftmVhlDstnBn8 12583;
BA_ "SPN" SG_ 2566588670 NOxTrkngVldNOxLftmVhlDstnBn9 12584;
BA_ "SPN" SG_ 2566588670 NOxTrkngVldNOxLftmVhlDstnBn10 12585;
BA_ "SPN" SG_ 2566588670 NOxTrkngVldNOxLftmVhlDstnBn11 12586;
BA_ "SPN" SG_ 2566588670 NOxTrkngVldNOxLftmVhlDstnBn12 12587;
BA_ "SPN" SG_ 2566588670 NOxTrkngVldNOxLftmVhlDstnBn13 12588;
BA_ "SPN" SG_ 2566588670 NOxTrkngVldNOxLftmVhlDstnBn14 12589;
BA_ "SPN" SG_ 2566588670 NOxTVdNOxLtVDstB15NTEBIN 12590;
BA_ "SPN" SG_ 2566588670 NOxTVdNOxLtVDstB16RB 12591;
BA_ "SPN" SG_ 2566588670 NOxTVdNOxLtVDstB17MILOB 12592;
BA_ "SPN" SG_ 2566588926 NOxTVdNOxLtEOtptEB1Tt 12559;
BA_ "SPN" SG_ 2566588926 NOxTVdNOxLtEOtptEB2 12560;
BA_ "SPN" SG_ 2566588926 NOxTVdNOxLtEOtptEB3 12561;
BA_ "SPN" SG_ 2566588926 NOxTVdNOxLtEOtptEB4 12562;
BA_ "SPN" SG_ 2566588926 NOxTVdNOxLtEOtptEB5 12563;
BA_ "SPN" SG_ 2566588926 NOxTVdNOxLtEOtptEB6 12564;
BA_ "SPN" SG_ 2566588926 NOxTVdNOxLtEOtptEB7 12565;
BA_ "SPN" SG_ 2566588926 NOxTVdNOxLtEOtptEB8 12566;
BA_ "SPN" SG_ 2566588926 NOxTVdNOxLtEOtptEB9 12567;
BA_ "SPN" SG_ 2566588926 NOxTVdNOxLtEOtptEB10 12568;
BA_ "SPN" SG_ 2566588926 NOxTVdNOxLtEOtptEB11 12569;
BA_ "SPN" SG_ 2566588926 NOxTVdNOxLtEOtptEB12 12570;
BA_ "SPN" SG_ 2566588926 NOxTVdNOxLtEOtptEB13 12571;
BA_ "SPN" SG_ 2566588926 NOxTVdNOxLtEOtptEB14 12572;
BA_ "SPN" SG_ 2566588926 NOxTVdNOxLtEOtptEB15NTEBIN 12573;
BA_ "SPN" SG_ 2566588926 NOxTVdNOxLtEOtptEB16RB 12574;
BA_ "SPN" SG_ 2566588926 NOxTVdNOxLtEOtptEB17MILOB 12575;
BA_ "SPN" SG_ 2566589182 NOxTVdNOxLtEOtNOxMssB1Tt 12542;
BA_ "SPN" SG_ 2566589182 NOxTVdNOxLtEOtNOxMssB2 12543;
BA_ "SPN" SG_ 2566589182 NOxTVdNOxLtEOtNOxMssB3 12544;
BA_ "SPN" SG_ 2566589182 NOxTVdNOxLtEOtNOxMssB4 12545;
BA_ "SPN" SG_ 2566589182 NOxTVdNOxLtEOtNOxMssB5 12546;
BA_ "SPN" SG_ 2566589182 NOxTVdNOxLtEOtNOxMssB6 12547;
BA_ "SPN" SG_ 2566589182 NOxTVdNOxLtEOtNOxMssB7 12548;
BA_ "SPN" SG_ 2566589182 NOxTVdNOxLtEOtNOxMssB8 12549;
BA_ "SPN" SG_ 2566589182 NOxTVdNOxLtEOtNOxMssB9 12550;
BA_ "SPN" SG_ 2566589182 NOxTVdNOxLtEOtNOxMssB10 12551;
BA_ "SPN" SG_ 2566589182 NOxTVdNOxLtEOtNOxMssB11 12552;
BA_ "SPN" SG_ 2566589182 NOxTVdNOxLtEOtNOxMssB12 12553;
BA_ "SPN" SG_ 2566589182 NOxTVdNOxLtEOtNOxMssB13 12554;
BA_ "SPN" SG_ 2566589182 NOxTVdNOxLtEOtNOxMssB14 12555;
BA_ "SPN" SG_ 2566589182 NOxTVdNOxLtEOtNOxMssB15NTEBIN 12556;
BA_ "SPN" SG_ 2566589182 NOxTVdNOxLtEOtNOxMssB16RB 12557;
BA_ "SPN" SG_ 2566589182 NOxTVdNOxLtEOtNOxMssB17MILOB 12558;
BA_ "SPN" SG_ 2566589438 NOxTVdNOxLtSstOtNOxMssB1Tt 12525;
BA_ "SPN" SG_ 2566589438 NOxTVdNOxLtSstOtNOxMssB2 12526;
BA_ "SPN" SG_ 2566589438 NOxTVdNOxLtSstOtNOxMssB3 12527;
BA_ "SPN" SG_ 2566589438 NOxTVdNOxLtSstOtNOxMssB4 12528;
BA_ "SPN" SG_ 2566589438 NOxTVdNOxLtSstOtNOxMssB5 12529;
BA_ "SPN" SG_ 2566589438 NOxTVdNOxLtSstOtNOxMssB6 12530;
BA_ "SPN" SG_ 2566589438 NOxTVdNOxLtSstOtNOxMssB7 12531;
BA_ "SPN" SG_ 2566589438 NOxTVdNOxLtSstOtNOxMssB8 12532;
BA_ "SPN" SG_ 2566589438 NOxTVdNOxLtSstOtNOxMssB9 12533;
BA_ "SPN" SG_ 2566589438 NOxTVdNOxLtSstOtNOxMssB10 12534;
BA_ "SPN" SG_ 2566589438 NOxTVdNOxLtSstOtNOxMssB11 12535;
BA_ "SPN" SG_ 2566589438 NOxTVdNOxLtSstOtNOxMssB12 12536;
BA_ "SPN" SG_ 2566589438 NOxTVdNOxLtSstOtNOxMssB13 12537;
BA_ "SPN" SG_ 2566589438 NOxTVdNOxLtSstOtNOxMssB14 12538;
BA_ "SPN" SG_ 2566589438 NOxTVdNOxLtSstOtNOxMssB15NTEBIN 12539;
BA_ "SPN" SG_ 2566589438 NOxTVdNOxLtSstOtNOxMssB16RB 12540;
BA_ "SPN" SG_ 2566589438 NOxTVdNOxLtSstOtNOxMssB17MILOB 12541;
BA_ "SPN" SG_ 2566589694 NOxTStd100HFCsptB1Tt 12508;
BA_ "SPN" SG_ 2566589694 NOxTrkngStrd100HrFlCnsmptnBn2 12509;
BA_ "SPN" SG_ 2566589694 NOxTrkngStrd100HrFlCnsmptnBn3 12510;
BA_ "SPN" SG_ 2566589694 NOxTrkngStrd100HrFlCnsmptnBn4 12511;
BA_ "SPN" SG_ 2566589694 NOxTrkngStrd100HrFlCnsmptnBn5 12512;
BA_ "SPN" SG_ 2566589694 NOxTrkngStrd100HrFlCnsmptnBn6 12513;
BA_ "SPN" SG_ 2566589694 NOxTrkngStrd100HrFlCnsmptnBn7 12514;
BA_ "SPN" SG_ 2566589694 NOxTrkngStrd100HrFlCnsmptnBn8 12515;
BA_ "SPN" SG_ 2566589694 NOxTrkngStrd100HrFlCnsmptnBn9 12516;
BA_ "SPN" SG_ 2566589694 NOxTrkngStrd100HrFlCnsmptnBn10 12517;
BA_ "SPN" SG_ 2566589694 NOxTrkngStrd100HrFlCnsmptnBn11 12518;
BA_ "SPN" SG_ 2566589694 NOxTrkngStrd100HrFlCnsmptnBn12 12519;
BA_ "SPN" SG_ 2566589694 NOxTrkngStrd100HrFlCnsmptnBn13 12520;
BA_ "SPN" SG_ 2566589694 NOxTrkngStrd100HrFlCnsmptnBn14 12521;
BA_ "SPN" SG_ 2566589694 NOxTStd100HFCsptB15NTEBIN 12522;
BA_ "SPN" SG_ 2566589694 NOxTStd100HFCsptB16RB 12523;
BA_ "SPN" SG_ 2566589694 NOxTStd100HFCsptB17MILOB 12524;
BA_ "SPN" SG_ 2566589950 NOxTrkngStrd100HrEngnRnTmBn1Ttl 12491;
BA_ "SPN" SG_ 2566589950 NOxTrkngStrd100HrEngnRnTmBn2 12492;
BA_ "SPN" SG_ 2566589950 NOxTrkngStrd100HrEngnRnTmBn3 12493;
BA_ "SPN" SG_ 2566589950 NOxTrkngStrd100HrEngnRnTmBn4 12494;
BA_ "SPN" SG_ 2566589950 NOxTrkngStrd100HrEngnRnTmBn5 12495;
BA_ "SPN" SG_ 2566589950 NOxTrkngStrd100HrEngnRnTmBn6 12496;
BA_ "SPN" SG_ 2566589950 NOxTrkngStrd100HrEngnRnTmBn7 12497;
BA_ "SPN" SG_ 2566589950 NOxTrkngStrd100HrEngnRnTmBn8 12498;
BA_ "SPN" SG_ 2566589950 NOxTrkngStrd100HrEngnRnTmBn9 12499;
BA_ "SPN" SG_ 2566589950 NOxTrkngStrd100HrEngnRnTmBn10 12500;
BA_ "SPN" SG_ 2566589950 NOxTrkngStrd100HrEngnRnTmBn11 12501;
BA_ "SPN" SG_ 2566589950 NOxTrkngStrd100HrEngnRnTmBn12 12502;
BA_ "SPN" SG_ 2566589950 NOxTrkngStrd100HrEngnRnTmBn13 12503;
BA_ "SPN" SG_ 2566589950 NOxTrkngStrd100HrEngnRnTmBn14 12504;
BA_ "SPN" SG_ 2566589950 NOxTStd100HERTB15NTEBIN 12505;
BA_ "SPN" SG_ 2566589950 NOxTStd100HERTB16RB 12506;
BA_ "SPN" SG_ 2566589950 NOxTStd100HERTB17MILOB 12507;
BA_ "SPN" SG_ 2566590206 NOxTrkngStrd100HrVhlDstnBn1Ttl 12474;
BA_ "SPN" SG_ 2566590206 NOxTrkngStrd100HrVhlDstnBn2 12475;
BA_ "SPN" SG_ 2566590206 NOxTrkngStrd100HrVhlDstnBn3 12476;
BA_ "SPN" SG_ 2566590206 NOxTrkngStrd100HrVhlDstnBn4 12477;
BA_ "SPN" SG_ 2566590206 NOxTrkngStrd100HrVhlDstnBn5 12478;
BA_ "SPN" SG_ 2566590206 NOxTrkngStrd100HrVhlDstnBn6 12479;
BA_ "SPN" SG_ 2566590206 NOxTrkngStrd100HrVhlDstnBn7 12480;
BA_ "SPN" SG_ 2566590206 NOxTrkngStrd100HrVhlDstnBn8 12481;
BA_ "SPN" SG_ 2566590206 NOxTrkngStrd100HrVhlDstnBn9 12482;
BA_ "SPN" SG_ 2566590206 NOxTrkngStrd100HrVhlDstnBn10 12483;
BA_ "SPN" SG_ 2566590206 NOxTrkngStrd100HrVhlDstnBn11 12484;
BA_ "SPN" SG_ 2566590206 NOxTrkngStrd100HrVhlDstnBn12 12485;
BA_ "SPN" SG_ 2566590206 NOxTrkngStrd100HrVhlDstnBn13 12486;
BA_ "SPN" SG_ 2566590206 NOxTrkngStrd100HrVhlDstnBn14 12487;
BA_ "SPN" SG_ 2566590206 NOxTStd100HVDstB15NTEBIN 12488;
BA_ "SPN" SG_ 2566590206 NOxTStd100HVDstB16RB 12489;
BA_ "SPN" SG_ 2566590206 NOxTStd100HVDstB17MILOB 12490;
BA_ "SPN" SG_ 2566590462 NOxTStd100HEOtptEB1Tt 12457;
BA_ "SPN" SG_ 2566590462 NOxTStd100HEOtptEB2 12458;
BA_ "SPN" SG_ 2566590462 NOxTStd100HEOtptEB3 12459;
BA_ "SPN" SG_ 2566590462 NOxTStd100HEOtptEB4 12460;
BA_ "SPN" SG_ 2566590462 NOxTStd100HEOtptEB5 12461;
BA_ "SPN" SG_ 2566590462 NOxTStd100HEOtptEB6 12462;
BA_ "SPN" SG_ 2566590462 NOxTStd100HEOtptEB7 12463;
BA_ "SPN" SG_ 2566590462 NOxTStd100HEOtptEB8 12464;
BA_ "SPN" SG_ 2566590462 NOxTStd100HEOtptEB9 12465;
BA_ "SPN" SG_ 2566590462 NOxTStd100HEOtptEB10 12466;
BA_ "SPN" SG_ 2566590462 NOxTStd100HEOtptEB11 12467;
BA_ "SPN" SG_ 2566590462 NOxTStd100HEOtptEB12 12468;
BA_ "SPN" SG_ 2566590462 NOxTStd100HEOtptEB13 12469;
BA_ "SPN" SG_ 2566590462 NOxTStd100HEOtptEB14 12470;
BA_ "SPN" SG_ 2566590462 NOxTStd100HEOtptEB15NTEBIN 12471;
BA_ "SPN" SG_ 2566590462 NOxTStd100HEOtptEB16RB 12472;
BA_ "SPN" SG_ 2566590462 NOxTStd100HEOtptEB17MILOB 12473;
BA_ "SPN" SG_ 2566590718 NOxTStd100HEOtNOxMssB1Tt 12440;
BA_ "SPN" SG_ 2566590718 NOxTStd100HEOtNOxMssB2 12441;
BA_ "SPN" SG_ 2566590718 NOxTStd100HEOtNOxMssB3 12442;
BA_ "SPN" SG_ 2566590718 NOxTStd100HEOtNOxMssB4 12443;
BA_ "SPN" SG_ 2566590718 NOxTStd100HEOtNOxMssB5 12444;
BA_ "SPN" SG_ 2566590718 NOxTStd100HEOtNOxMssB6 12445;
BA_ "SPN" SG_ 2566590718 NOxTStd100HEOtNOxMssB7 12446;
BA_ "SPN" SG_ 2566590718 NOxTStd100HEOtNOxMssB8 12447;
BA_ "SPN" SG_ 2566590718 NOxTStd100HEOtNOxMssB9 12448;
BA_ "SPN" SG_ 2566590718 NOxTStd100HEOtNOxMssB10 12449;
BA_ "SPN" SG_ 2566590718 NOxTStd100HEOtNOxMssB11 12450;
BA_ "SPN" SG_ 2566590718 NOxTStd100HEOtNOxMssB12 12451;
BA_ "SPN" SG_ 2566590718 NOxTStd100HEOtNOxMssB13 12452;
BA_ "SPN" SG_ 2566590718 NOxTStd100HEOtNOxMssB14 12453;
BA_ "SPN" SG_ 2566590718 NOxTStd100HEOtNOxMssB15NTEBIN 12454;
BA_ "SPN" SG_ 2566590718 NOxTStd100HEOtNOxMssB16RB 12455;
BA_ "SPN" SG_ 2566590718 NOxTStd100HEOtNOxMssB17MILOB 12456;
BA_ "SPN" SG_ 2566590974 NOxTStd100HSstOtNOxMssB1Tt 12423;
BA_ "SPN" SG_ 2566590974 NOxTStd100HSstOtNOxMssB2 12424;
BA_ "SPN" SG_ 2566590974 NOxTStd100HSstOtNOxMssB3 12425;
BA_ "SPN" SG_ 2566590974 NOxTStd100HSstOtNOxMssB4 12426;
BA_ "SPN" SG_ 2566590974 NOxTStd100HSstOtNOxMssB5 12427;
BA_ "SPN" SG_ 2566590974 NOxTStd100HSstOtNOxMssB6 12428;
BA_ "SPN" SG_ 2566590974 NOxTStd100HSstOtNOxMssB7 12429;
BA_ "SPN" SG_ 2566590974 NOxTStd100HSstOtNOxMssB8 12430;
BA_ "SPN" SG_ 2566590974 NOxTStd100HSstOtNOxMssB9 12431;
BA_ "SPN" SG_ 2566590974 NOxTStd100HSstOtNOxMssB10 12432;
BA_ "SPN" SG_ 2566590974 NOxTStd100HSstOtNOxMssB11 12433;
BA_ "SPN" SG_ 2566590974 NOxTStd100HSstOtNOxMssB12 12434;
BA_ "SPN" SG_ 2566590974 NOxTStd100HSstOtNOxMssB13 12435;
BA_ "SPN" SG_ 2566590974 NOxTStd100HSstOtNOxMssB14 12436;
BA_ "SPN" SG_ 2566590974 NOxTStd100HSstOtNOxMssB15NTEBIN 12437;
BA_ "SPN" SG_ 2566590974 NOxTStd100HSstOtNOxMssB16RB 12438;
BA_ "SPN" SG_ 2566590974 NOxTStd100HSstOtNOxMssB17MILOB 12439;
BA_ "SPN" SG_ 2566591230 NOxTrkngAtv100HrFlCnsmptnBn1Ttl 12406;
BA_ "SPN" SG_ 2566591230 NOxTrkngAtv100HrFlCnsmptnBn2 12407;
BA_ "SPN" SG_ 2566591230 NOxTrkngAtv100HrFlCnsmptnBn3 12408;
BA_ "SPN" SG_ 2566591230 NOxTrkngAtv100HrFlCnsmptnBn4 12409;
BA_ "SPN" SG_ 2566591230 NOxTrkngAtv100HrFlCnsmptnBn5 12410;
BA_ "SPN" SG_ 2566591230 NOxTrkngAtv100HrFlCnsmptnBn6 12411;
BA_ "SPN" SG_ 2566591230 NOxTrkngAtv100HrFlCnsmptnBn7 12412;
BA_ "SPN" SG_ 2566591230 NOxTrkngAtv100HrFlCnsmptnBn8 12413;
BA_ "SPN" SG_ 2566591230 NOxTrkngAtv100HrFlCnsmptnBn9 12414;
BA_ "SPN" SG_ 2566591230 NOxTrkngAtv100HrFlCnsmptnBn10 12415;
BA_ "SPN" SG_ 2566591230 NOxTrkngAtv100HrFlCnsmptnBn11 12416;
BA_ "SPN" SG_ 2566591230 NOxTrkngAtv100HrFlCnsmptnBn12 12417;
BA_ "SPN" SG_ 2566591230 NOxTrkngAtv100HrFlCnsmptnBn13 12418;
BA_ "SPN" SG_ 2566591230 NOxTrkngAtv100HrFlCnsmptnBn14 12419;
BA_ "SPN" SG_ 2566591230 NOxTAtv100HFCsptB15NTEBIN 12420;
BA_ "SPN" SG_ 2566591230 NOxTAtv100HFCsptB16RB 12421;
BA_ "SPN" SG_ 2566591230 NOxTAtv100HFCsptB17MILOB 12422;
BA_ "SPN" SG_ 2566591486 NOxTrkngAtv100HrEngnRnTmBn1Ttl 12389;
BA_ "SPN" SG_ 2566591486 NOxTrkngAtv100HrEngnRnTmBn2 12390;
BA_ "SPN" SG_ 2566591486 NOxTrkngAtv100HrEngnRnTmBn3 12391;
BA_ "SPN" SG_ 2566591486 NOxTrkngAtv100HrEngnRnTmBn4 12392;
BA_ "SPN" SG_ 2566591486 NOxTrkngAtv100HrEngnRnTmBn5 12393;
BA_ "SPN" SG_ 2566591486 NOxTrkngAtv100HrEngnRnTmBn6 12394;
BA_ "SPN" SG_ 2566591486 NOxTrkngAtv100HrEngnRnTmBn7 12395;
BA_ "SPN" SG_ 2566591486 NOxTrkngAtv100HrEngnRnTmBn8 12396;
BA_ "SPN" SG_ 2566591486 NOxTrkngAtv100HrEngnRnTmBn9 12397;
BA_ "SPN" SG_ 2566591486 NOxTrkngAtv100HrEngnRnTmBn10 12398;
BA_ "SPN" SG_ 2566591486 NOxTrkngAtv100HrEngnRnTmBn11 12399;
BA_ "SPN" SG_ 2566591486 NOxTrkngAtv100HrEngnRnTmBn12 12400;
BA_ "SPN" SG_ 2566591486 NOxTrkngAtv100HrEngnRnTmBn13 12401;
BA_ "SPN" SG_ 2566591486 NOxTrkngAtv100HrEngnRnTmBn14 12402;
BA_ "SPN" SG_ 2566591486 NOxTAtv100HERTB15NTEBIN 12403;
BA_ "SPN" SG_ 2566591486 NOxTAtv100HERTB16RB 12404;
BA_ "SPN" SG_ 2566591486 NOxTAtv100HERTB17MILOB 12405;
BA_ "SPN" SG_ 2566591742 NOxTrkngAtv100HrVhlDstnBn1Ttl 12372;
BA_ "SPN" SG_ 2566591742 NOxTrkngAtv100HrVhlDstnBn2 12373;
BA_ "SPN" SG_ 2566591742 NOxTrkngAtv100HrVhlDstnBn3 12374;
BA_ "SPN" SG_ 2566591742 NOxTrkngAtv100HrVhlDstnBn4 12375;
BA_ "SPN" SG_ 2566591742 NOxTrkngAtv100HrVhlDstnBn5 12376;
BA_ "SPN" SG_ 2566591742 NOxTrkngAtv100HrVhlDstnBn6 12377;
BA_ "SPN" SG_ 2566591742 NOxTrkngAtv100HrVhlDstnBn7 12378;
BA_ "SPN" SG_ 2566591742 NOxTrkngAtv100HrVhlDstnBn8 12379;
BA_ "SPN" SG_ 2566591742 NOxTrkngAtv100HrVhlDstnBn9 12380;
BA_ "SPN" SG_ 2566591742 NOxTrkngAtv100HrVhlDstnBn10 12381;
BA_ "SPN" SG_ 2566591742 NOxTrkngAtv100HrVhlDstnBn11 12382;
BA_ "SPN" SG_ 2566591742 NOxTrkngAtv100HrVhlDstnBn12 12383;
BA_ "SPN" SG_ 2566591742 NOxTrkngAtv100HrVhlDstnBn13 12384;
BA_ "SPN" SG_ 2566591742 NOxTrkngAtv100HrVhlDstnBn14 12385;
BA_ "SPN" SG_ 2566591742 NOxTAtv100HVDstB15NTEBIN 12386;
BA_ "SPN" SG_ 2566591742 NOxTAtv100HVDstB16RB 12387;
BA_ "SPN" SG_ 2566591742 NOxTAtv100HVDstB17MILOB 12388;
BA_ "SPN" SG_ 2566591998 NOxTAtv100HEOtptEB1Tt 12355;
BA_ "SPN" SG_ 2566591998 NOxTrkngAtv100HrEngnOtptEnrgBn2 12356;
BA_ "SPN" SG_ 2566591998 NOxTrkngAtv100HrEngnOtptEnrgBn3 12357;
BA_ "SPN" SG_ 2566591998 NOxTrkngAtv100HrEngnOtptEnrgBn4 12358;
BA_ "SPN" SG_ 2566591998 NOxTrkngAtv100HrEngnOtptEnrgBn5 12359;
BA_ "SPN" SG_ 2566591998 NOxTrkngAtv100HrEngnOtptEnrgBn6 12360;
BA_ "SPN" SG_ 2566591998 NOxTrkngAtv100HrEngnOtptEnrgBn7 12361;
BA_ "SPN" SG_ 2566591998 NOxTrkngAtv100HrEngnOtptEnrgBn8 12362;
BA_ "SPN" SG_ 2566591998 NOxTrkngAtv100HrEngnOtptEnrgBn9 12363;
BA_ "SPN" SG_ 2566591998 NOxTAtv100HEOtptEB10 12364;
BA_ "SPN" SG_ 2566591998 NOxTAtv100HEOtptEB11 12365;
BA_ "SPN" SG_ 2566591998 NOxTAtv100HEOtptEB12 12366;
BA_ "SPN" SG_ 2566591998 NOxTAtv100HEOtptEB13 12367;
BA_ "SPN" SG_ 2566591998 NOxTAtv100HEOtptEB14 12368;
BA_ "SPN" SG_ 2566591998 NOxTAtv100HEOtptEB15NTEBIN 12369;
BA_ "SPN" SG_ 2566591998 NOxTAtv100HEOtptEB16RB 12370;
BA_ "SPN" SG_ 2566591998 NOxTAtv100HEOtptEB17MILOB 12371;
BA_ "SPN" SG_ 2566592254 NOxTAtv100HEOtNOxMssB1Tt 12338;
BA_ "SPN" SG_ 2566592254 NOxTrkngAtv100HrEngnOtNOxMssBn2 12339;
BA_ "SPN" SG_ 2566592254 NOxTrkngAtv100HrEngnOtNOxMssBn3 12340;
BA_ "SPN" SG_ 2566592254 NOxTrkngAtv100HrEngnOtNOxMssBn4 12341;
BA_ "SPN" SG_ 2566592254 NOxTrkngAtv100HrEngnOtNOxMssBn5 12342;
BA_ "SPN" SG_ 2566592254 NOxTrkngAtv100HrEngnOtNOxMssBn6 12343;
BA_ "SPN" SG_ 2566592254 NOxTrkngAtv100HrEngnOtNOxMssBn7 12344;
BA_ "SPN" SG_ 2566592254 NOxTrkngAtv100HrEngnOtNOxMssBn8 12345;
BA_ "SPN" SG_ 2566592254 NOxTrkngAtv100HrEngnOtNOxMssBn9 12346;
BA_ "SPN" SG_ 2566592254 NOxTAtv100HEOtNOxMssB10 12347;
BA_ "SPN" SG_ 2566592254 NOxTAtv100HEOtNOxMssB11 12348;
BA_ "SPN" SG_ 2566592254 NOxTAtv100HEOtNOxMssB12 12349;
BA_ "SPN" SG_ 2566592254 NOxTAtv100HEOtNOxMssB13 12350;
BA_ "SPN" SG_ 2566592254 NOxTAtv100HEOtNOxMssB14 12351;
BA_ "SPN" SG_ 2566592254 NOxTAtv100HEOtNOxMssB15NTEBIN 12352;
BA_ "SPN" SG_ 2566592254 NOxTAtv100HEOtNOxMssB16RB 12353;
BA_ "SPN" SG_ 2566592254 NOxTAtv100HEOtNOxMssB17MILOB 12354;
BA_ "SPN" SG_ 2566592510 NOxTAtv100HSstOtNOxMssB1Tt 12321;
BA_ "SPN" SG_ 2566592510 NOxTrkngAtv100HrSstmOtNOxMssBn2 12322;
BA_ "SPN" SG_ 2566592510 NOxTrkngAtv100HrSstmOtNOxMssBn3 12323;
BA_ "SPN" SG_ 2566592510 NOxTrkngAtv100HrSstmOtNOxMssBn4 12324;
BA_ "SPN" SG_ 2566592510 NOxTrkngAtv100HrSstmOtNOxMssBn5 12325;
BA_ "SPN" SG_ 2566592510 NOxTrkngAtv100HrSstmOtNOxMssBn6 12326;
BA_ "SPN" SG_ 2566592510 NOxTrkngAtv100HrSstmOtNOxMssBn7 12327;
BA_ "SPN" SG_ 2566592510 NOxTrkngAtv100HrSstmOtNOxMssBn8 12328;
BA_ "SPN" SG_ 2566592510 NOxTrkngAtv100HrSstmOtNOxMssBn9 12329;
BA_ "SPN" SG_ 2566592510 NOxTAtv100HSstOtNOxMssB10 12330;
BA_ "SPN" SG_ 2566592510 NOxTAtv100HSstOtNOxMssB11 12331;
BA_ "SPN" SG_ 2566592510 NOxTAtv100HSstOtNOxMssB12 12332;
BA_ "SPN" SG_ 2566592510 NOxTAtv100HSstOtNOxMssB13 12333;
BA_ "SPN" SG_ 2566592510 NOxTAtv100HSstOtNOxMssB14 12334;
BA_ "SPN" SG_ 2566592510 NOxTAtv100HSstOtNOxMssB15NTEBIN 12335;
BA_ "SPN" SG_ 2566592510 NOxTAtv100HSstOtNOxMssB16RB 12336;
BA_ "SPN" SG_ 2566592510 NOxTAtv100HSstOtNOxMssB17MILOB 12337;
BA_ "SPN" SG_ 2365266174 MtrGnrtr6InvrtrRtLmtsRqst2CRC 12266;
BA_ "SPN" SG_ 2365266174 MtrGnrtr6InvrtrRtLmtsRqst2Cntr 12267;
BA_ "SPN" SG_ 2365266174 MtrGnrtr6InvrtrPIDCntrlAppllMd 12268;
BA_ "SPN" SG_ 2365266174 MtGt6IvtPIDCtNzdDtG 12269;
BA_ "SPN" SG_ 2365266174 MtGt6IvtPIDCtNzdItG 12270;
BA_ "SPN" SG_ 2365266174 MtGt6IvtPIDCtNzdPptG 12271;
BA_ "SPN" SG_ 2365266174 MtGt6IvtPIDCtFdFwdTq 12272;
BA_ "SPN" SG_ 2566593022 MtrGnrtr6InvrtrLmtsRqstPwrCRC 12181;
BA_ "SPN" SG_ 2566593022 MtrGnrtr6InvrtrLmtsRqstPwrCntr 12182;
BA_ "SPN" SG_ 2566593022 MtGt6IvtLtsRqstMPwMx 12183;
BA_ "SPN" SG_ 2566593022 MtGt6IvtLtsRqstMPwM 12184;
BA_ "SPN" SG_ 2566593022 MtGt6IvtLtsRqstDCSdPwMx 12185;
BA_ "SPN" SG_ 2566593022 MtGt6IvtLtsRqstDCSdPwM 12186;
